VERSION ""

NS_ :

BS_:

BU_: RLPSU DPSU APSU PSB SHVU_RR vHS_B2 FCS EMCU SLB RCM CGW_CCU vDummy_HS_B ATS RLHV PFSU SGU ALBCU DSAU SWRC SHVU_FR RCS RRPSU BLTN_CAM SCM DLBCU OHCL RWPC RRHV WPC HOD ASAU

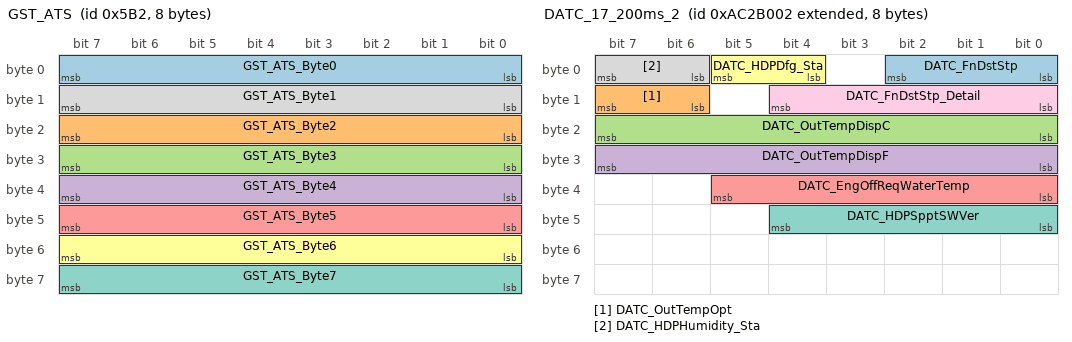
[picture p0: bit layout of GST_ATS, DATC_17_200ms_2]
BO_ 1458 GST_ATS: 8 CGW_CCU
 SG_ GST_ATS_Byte0 : 0|8@1+ (1,0) [0|0] ""  ATS
 SG_ GST_ATS_Byte2 : 16|8@1+ (1,0) [0|0] ""  ATS
 SG_ GST_ATS_Byte3 : 24|8@1+ (1,0) [0|0] ""  ATS
 SG_ GST_ATS_Byte4 : 32|8@1+ (1,0) [0|0] ""  ATS
 SG_ GST_ATS_Byte5 : 40|8@1+ (1,0) [0|0] ""  ATS
 SG_ GST_ATS_Byte6 : 48|8@1+ (1,0) [0|0] ""  ATS
 SG_ GST_ATS_Byte7 : 56|8@1+ (1,0) [0|0] ""  ATS
 SG_ GST_ATS_Byte1 : 8|8@1+ (1,0) [0|0] ""  ATS

BO_ 2328014850 DATC_17_200ms_2: 8 CGW_CCU
 SG_ DATC_FnDstStp : 0|3@1+ (1,0) [0|0] ""  ATS
 SG_ DATC_OutTempOpt : 14|2@1+ (1,0) [0|0] ""  Vector__XXX
 SG_ DATC_OutTempDispC : 16|8@1+ (0.5,-41) [0|0] "¡É"  ATS
 SG_ DATC_OutTempDispF : 24|8@1+ (1,-42) [0|0] "¢µ"  ATS
 SG_ DATC_EngOffReqWaterTemp : 32|6@1+ (1,38) [0|0] "¡É"  Vector__XXX
 SG_ DATC_HDPDfg_Sta : 4|2@1+ (1,0) [0|0] ""  Vector__XXX
 SG_ DATC_HDPSpptSWVer : 40|5@1+ (1,0) [0|0] ""  Vector__XXX
 SG_ DATC_HDPHumidity_Sta : 6|2@1+ (1,0) [0|0] ""  Vector__XXX
 SG_ DATC_FnDstStp_Detail : 8|5@1+ (1,0) [0|0] ""  ATS

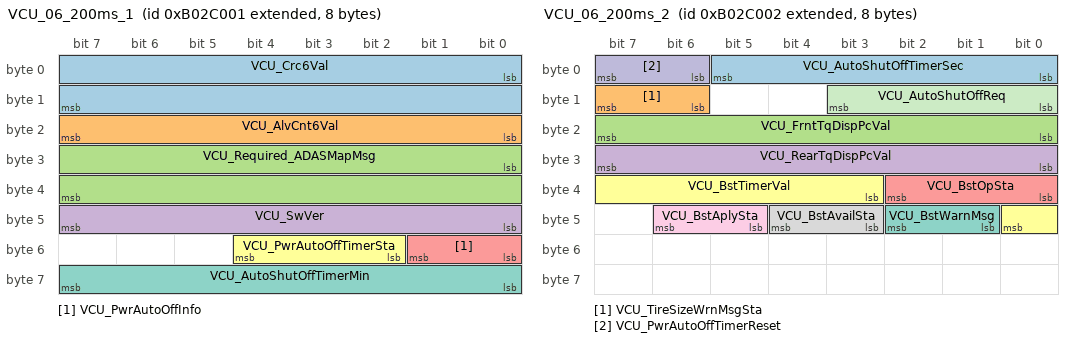
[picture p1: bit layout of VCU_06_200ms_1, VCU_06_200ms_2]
BO_ 2332213249 VCU_06_200ms_1: 8 CGW_CCU
 SG_ VCU_Crc6Val : 0|16@1+ (1,0) [0|0] ""  Vector__XXX
 SG_ VCU_AlvCnt6Val : 16|8@1+ (1,0) [0|0] ""  Vector__XXX
 SG_ VCU_Required_ADASMapMsg : 24|16@1+ (1,0) [0|0] ""  Vector__XXX
 SG_ VCU_SwVer : 40|8@1+ (1,0) [0|0] ""  Vector__XXX
 SG_ VCU_PwrAutoOffInfo : 48|2@1+ (1,0) [0|0] ""  Vector__XXX
 SG_ VCU_PwrAutoOffTimerSta : 50|3@1+ (1,0) [0|0] ""  Vector__XXX
 SG_ VCU_AutoShutOffTimerMin : 56|8@1+ (1,0) [0|0] ""  Vector__XXX

BO_ 2328014851 DATC_17_200ms_3: 8 CGW_CCU

BO_ 2332213250 VCU_06_200ms_2: 8 CGW_CCU
 SG_ VCU_AutoShutOffTimerSec : 0|6@1+ (1,0) [0|0] ""  Vector__XXX
 SG_ VCU_TireSizeWrnMsgSta : 14|2@1+ (1,0) [0|0] ""  Vector__XXX
 SG_ VCU_FrntTqDispPcVal : 16|8@1- (1,0) [0|0] ""  Vector__XXX
 SG_ VCU_RearTqDispPcVal : 24|8@1- (1,0) [0|0] ""  Vector__XXX
 SG_ VCU_BstOpSta : 32|3@1+ (1,0) [0|0] ""  PSB,DLBCU
 SG_ VCU_BstTimerVal : 35|6@1+ (1,0) [0|0] ""  PSB,DLBCU
 SG_ VCU_BstWarnMsg : 41|2@1+ (1,0) [0|0] ""  PSB,DLBCU
 SG_ VCU_BstAvailSta : 43|2@1+ (1,0) [0|0] ""  DLBCU
 SG_ VCU_BstAplySta : 45|2@1+ (1,0) [0|0] ""  DLBCU
 SG_ VCU_PwrAutoOffTimerReset : 6|2@1+ (1,0) [0|0] ""  Vector__XXX
 SG_ VCU_AutoShutOffReq : 8|4@1+ (1,0) [0|0] ""  Vector__XXX

BO_ 2332213251 VCU_06_200ms_3: 8 CGW_CCU

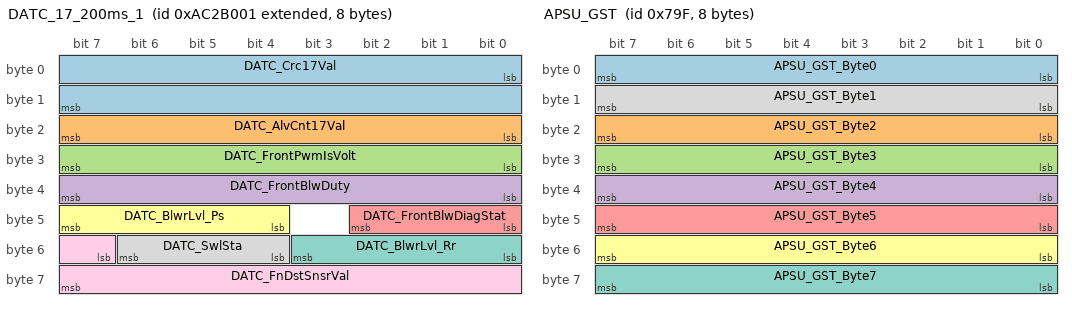
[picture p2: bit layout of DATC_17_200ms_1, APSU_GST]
BO_ 2328014849 DATC_17_200ms_1: 8 CGW_CCU
 SG_ DATC_Crc17Val : 0|16@1+ (1,0) [0|0] ""  Vector__XXX
 SG_ DATC_AlvCnt17Val : 16|8@1+ (1,0) [0|0] ""  Vector__XXX
 SG_ DATC_FrontPwmIsVolt : 24|8@1+ (0.02,0) [0|0] "V"  Vector__XXX
 SG_ DATC_FrontBlwDuty : 32|8@1+ (1,0) [0|0] ""  Vector__XXX
 SG_ DATC_FrontBlwDiagStat : 40|3@1+ (1,0) [0|0] ""  Vector__XXX
 SG_ DATC_BlwrLvl_Ps : 44|4@1+ (1,0) [0|0] ""  Vector__XXX
 SG_ DATC_BlwrLvl_Rr : 48|4@1+ (1,0) [0|0] ""  Vector__XXX
 SG_ DATC_SwlSta : 52|3@1+ (1,0) [0|0] ""  Vector__XXX
 SG_ DATC_FnDstSnsrVal : 55|9@1+ (1,0) [0|0] ""  Vector__XXX

BO_ 1951 APSU_GST: 8 APSU
 SG_ APSU_GST_Byte0 : 0|8@1+ (1,0) [0|0] ""  CGW_CCU
 SG_ APSU_GST_Byte2 : 16|8@1+ (1,0) [0|0] ""  CGW_CCU
 SG_ APSU_GST_Byte3 : 24|8@1+ (1,0) [0|0] ""  CGW_CCU
 SG_ APSU_GST_Byte4 : 32|8@1+ (1,0) [0|0] ""  CGW_CCU
 SG_ APSU_GST_Byte5 : 40|8@1+ (1,0) [0|0] ""  CGW_CCU
 SG_ APSU_GST_Byte6 : 48|8@1+ (1,0) [0|0] ""  CGW_CCU
 SG_ APSU_GST_Byte7 : 56|8@1+ (1,0) [0|0] ""  CGW_CCU
 SG_ APSU_GST_Byte1 : 8|8@1+ (1,0) [0|0] ""  CGW_CCU

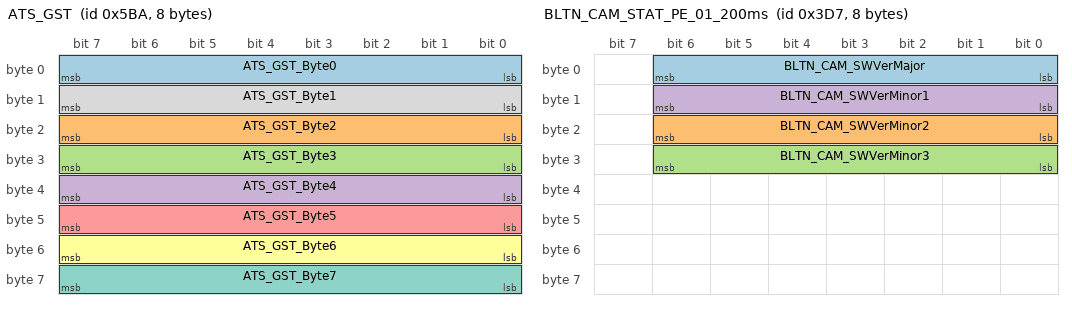
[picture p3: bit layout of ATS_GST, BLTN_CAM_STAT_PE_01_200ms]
BO_ 1466 ATS_GST: 8 ATS
 SG_ ATS_GST_Byte0 : 0|8@1+ (1,0) [0|0] ""  CGW_CCU
 SG_ ATS_GST_Byte2 : 16|8@1+ (1,0) [0|0] ""  CGW_CCU
 SG_ ATS_GST_Byte3 : 24|8@1+ (1,0) [0|0] ""  CGW_CCU
 SG_ ATS_GST_Byte4 : 32|8@1+ (1,0) [0|0] ""  CGW_CCU
 SG_ ATS_GST_Byte5 : 40|8@1+ (1,0) [0|0] ""  CGW_CCU
 SG_ ATS_GST_Byte6 : 48|8@1+ (1,0) [0|0] ""  CGW_CCU
 SG_ ATS_GST_Byte7 : 56|8@1+ (1,0) [0|0] ""  CGW_CCU
 SG_ ATS_GST_Byte1 : 8|8@1+ (1,0) [0|0] ""  CGW_CCU

BO_ 983 BLTN_CAM_STAT_PE_01_200ms: 8 BLTN_CAM
 SG_ BLTN_CAM_SWVerMajor : 0|7@1+ (1,0) [0|0] ""  CGW_CCU
 SG_ BLTN_CAM_SWVerMinor2 : 16|7@1+ (1,0) [0|0] ""  CGW_CCU
 SG_ BLTN_CAM_SWVerMinor3 : 24|7@1+ (1,0) [0|0] ""  CGW_CCU
 SG_ BLTN_CAM_SWVerMinor1 : 8|7@1+ (1,0) [0|0] ""  CGW_CCU

BO_ 981 APSS_01_200ms: 8 APSU
 SG_ APSS_StExtFwdMvBtn : 0|2@1+ (1,0) [0|0] ""  Vector__XXX
 SG_ APSS_StSldFwdMvBtn : 16|2@1+ (1,0) [0|0] ""  CGW_CCU
 SG_ APSS_StSldBwdMvBtn : 18|2@1+ (1,0) [0|0] ""  CGW_CCU
 SG_ APSS_StExtBwdMvBtn : 2|2@1+ (1,0) [0|0] ""  Vector__XXX
 SG_ APSS_StRclFwdMvBtn : 20|2@1+ (1,0) [0|0] ""  CGW_CCU
 SG_ APSS_StRclBwdMvBtn : 22|2@1+ (1,0) [0|0] ""  CGW_CCU
 SG_ APSS_StHgtUpMvBtn : 24|2@1+ (1,0) [0|0] ""  CGW_CCU
 SG_ APSS_StHgtDnMvBtn : 26|2@1+ (1,0) [0|0] ""  CGW_CCU
 SG_ APSS_StTltUpMvBtn : 28|2@1+ (1,0) [0|0] ""  CGW_CCU
 SG_ APSS_StTltDnMvBtn : 30|2@1+ (1,0) [0|0] ""  CGW_CCU
 SG_ APSS_StHRestUpMvBtn : 32|2@1+ (1,0) [0|0] ""  CGW_CCU
 SG_ APSS_StHRestDnMvBtn : 34|2@1+ (1,0) [0|0] ""  CGW_CCU
 SG_ APSS_StHRestFwdMvBtn : 36|2@1+ (1,0) [0|0] ""  CGW_CCU
 SG_ APSS_StHRestBwdMvBtn : 38|2@1+ (1,0) [0|0] ""  CGW_CCU
 SG_ APSS_StLegUpMvBtn : 40|2@1+ (1,0) [0|0] ""  Vector__XXX
 SG_ APSS_StLegDnMvBtn : 42|2@1+ (1,0) [0|0] ""  Vector__XXX
 SG_ APSS_StRlxModeBtn : 44|2@1+ (1,0) [0|0] ""  Vector__XXX
 SG_ APSS_StRlxReturnBtn : 46|2@1+ (1,0) [0|0] ""  Vector__XXX
 SG_ APSS_StRlxTltUpMvBtn : 48|2@1+ (1,0) [0|0] ""  Vector__XXX
 SG_ APSS_StRlxTltDnMvBtn : 50|2@1+ (1,0) [0|0] ""  Vector__XXX

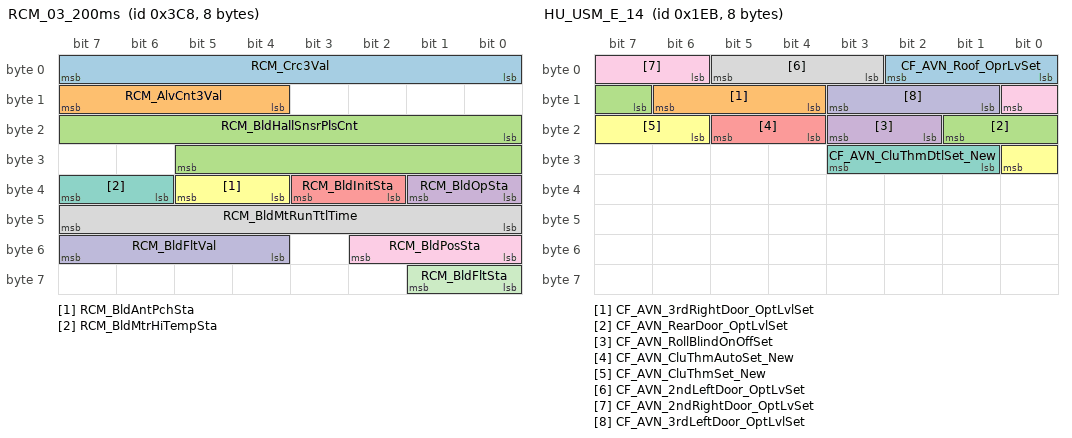
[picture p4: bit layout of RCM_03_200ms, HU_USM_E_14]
BO_ 968 RCM_03_200ms: 8 RCM
 SG_ RCM_Crc3Val : 0|8@1+ (1,0) [0|0] ""  Vector__XXX
 SG_ RCM_AlvCnt3Val : 12|4@1+ (1,0) [0|0] ""  Vector__XXX
 SG_ RCM_BldHallSnsrPlsCnt : 16|14@1+ (1,0) [0|0] "pulse count"  Vector__XXX
 SG_ RCM_BldOpSta : 32|2@1+ (1,0) [0|0] ""  Vector__XXX
 SG_ RCM_BldInitSta : 34|2@1+ (1,0) [0|0] ""  Vector__XXX
 SG_ RCM_BldAntPchSta : 36|2@1+ (1,0) [0|0] ""  Vector__XXX
 SG_ RCM_BldMtrHiTempSta : 38|2@1+ (1,0) [0|0] ""  Vector__XXX
 SG_ RCM_BldMtRunTtlTime : 40|8@1+ (1,0) [0|0] "Sec"  Vector__XXX
 SG_ RCM_BldPosSta : 48|3@1+ (1,0) [0|0] ""  SGU
 SG_ RCM_BldFltVal : 52|4@1+ (1,0) [0|0] ""  Vector__XXX
 SG_ RCM_BldFltSta : 56|2@1+ (1,0) [0|0] ""  Vector__XXX

BO_ 491 HU_USM_E_14: 8 CGW_CCU
 SG_ CF_AVN_Roof_OprLvSet : 0|3@1+ (1,0) [0|0] ""  SGU
 SG_ CF_AVN_3rdRightDoor_OptLvlSet : 12|3@1+ (1,0) [0|0] ""  SGU
 SG_ CF_AVN_RearDoor_OptLvlSet : 15|3@1+ (1,0) [0|0] ""  SGU
 SG_ CF_AVN_RollBlindOnOffSet : 18|2@1+ (1,0) [0|0] ""  SGU
 SG_ CF_AVN_CluThmAutoSet_New : 20|2@1+ (1,0) [0|0] ""  Vector__XXX
 SG_ CF_AVN_CluThmSet_New : 22|3@1+ (1,0) [0|0] ""  Vector__XXX
 SG_ CF_AVN_CluThmDtlSet_New : 25|3@1+ (1,0) [0|0] ""  Vector__XXX
 SG_ CF_AVN_2ndLeftDoor_OptLvSet : 3|3@1+ (1,0) [0|0] ""  SGU
 SG_ CF_AVN_2ndRightDoor_OptLvSet : 6|3@1+ (1,0) [0|0] ""  SGU
 SG_ CF_AVN_3rdLeftDoor_OptLvlSet : 9|3@1+ (1,0) [0|0] ""  SGU

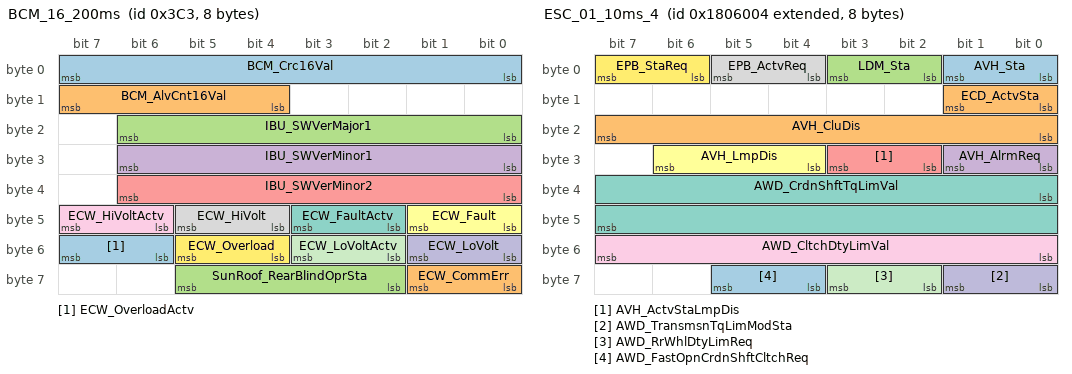
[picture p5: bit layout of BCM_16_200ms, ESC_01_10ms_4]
BO_ 963 BCM_16_200ms: 8 CGW_CCU
 SG_ BCM_Crc16Val : 0|8@1+ (1,0) [0|0] ""  Vector__XXX
 SG_ BCM_AlvCnt16Val : 12|4@1+ (1,0) [0|0] ""  Vector__XXX
 SG_ IBU_SWVerMajor1 : 16|7@1+ (1,0) [0|0] ""  Vector__XXX
 SG_ IBU_SWVerMinor1 : 24|7@1+ (1,0) [0|0] ""  Vector__XXX
 SG_ IBU_SWVerMinor2 : 32|7@1+ (1,0) [0|0] ""  Vector__XXX
 SG_ ECW_Fault : 40|2@1+ (1,0) [0|0] ""  Vector__XXX
 SG_ ECW_FaultActv : 42|2@1+ (1,0) [0|0] ""  Vector__XXX
 SG_ ECW_HiVolt : 44|2@1+ (1,0) [0|0] ""  Vector__XXX
 SG_ ECW_HiVoltActv : 46|2@1+ (1,0) [0|0] ""  Vector__XXX
 SG_ ECW_LoVolt : 48|2@1+ (1,0) [0|0] ""  Vector__XXX
 SG_ ECW_LoVoltActv : 50|2@1+ (1,0) [0|0] ""  Vector__XXX
 SG_ ECW_Overload : 52|2@1+ (1,0) [0|0] ""  Vector__XXX
 SG_ ECW_OverloadActv : 54|2@1+ (1,0) [0|0] ""  Vector__XXX
 SG_ ECW_CommErr : 56|2@1+ (1,0) [0|0] ""  Vector__XXX
 SG_ SunRoof_RearBlindOprSta : 58|4@1+ (1,0) [0|0] ""  ATS

BO_ 2172674052 ESC_01_10ms_4: 8 CGW_CCU
 SG_ AVH_Sta : 0|2@1+ (1,0) [0|0] ""  Vector__XXX
 SG_ AVH_CluDis : 16|8@1+ (1,0) [0|0] ""  Vector__XXX
 SG_ LDM_Sta : 2|2@1+ (1,0) [0|0] ""  Vector__XXX
 SG_ AVH_AlrmReq : 24|2@1+ (1,0) [0|0] ""  Vector__XXX
 SG_ AVH_ActvStaLmpDis : 26|2@1+ (1,0) [0|0] ""  Vector__XXX
 SG_ AVH_LmpDis : 28|3@1+ (1,0) [0|0] ""  Vector__XXX
 SG_ AWD_CrdnShftTqLimVal : 32|16@1+ (1,0) [0|0] "Nm"  Vector__XXX
 SG_ EPB_ActvReq : 4|2@1+ (1,0) [0|0] ""  Vector__XXX
 SG_ AWD_CltchDtyLimVal : 48|8@1+ (0.390625,0) [0|0] "%"  Vector__XXX
 SG_ AWD_TransmsnTqLimModSta : 56|2@1+ (1,0) [0|0] ""  Vector__XXX
 SG_ AWD_RrWhlDtyLimReq : 58|2@1+ (1,0) [0|0] ""  Vector__XXX
 SG_ EPB_StaReq : 6|2@1+ (1,0) [0|0] ""  Vector__XXX
 SG_ AWD_FastOpnCrdnShftCltchReq : 60|2@1+ (1,0) [0|0] ""  Vector__XXX
 SG_ ECD_ActvSta : 8|2@1+ (1,0) [0|0] ""  Vector__XXX

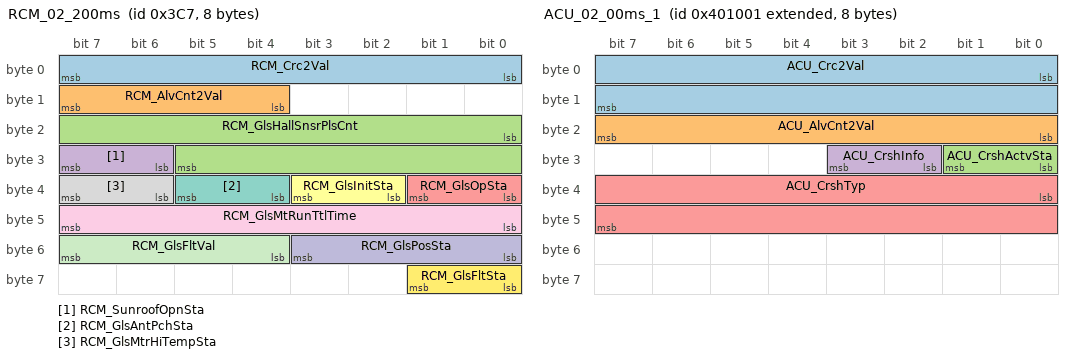
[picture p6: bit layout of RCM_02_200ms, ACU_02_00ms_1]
BO_ 967 RCM_02_200ms: 8 RCM
 SG_ RCM_Crc2Val : 0|8@1+ (1,0) [0|0] ""  Vector__XXX
 SG_ RCM_AlvCnt2Val : 12|4@1+ (1,0) [0|0] ""  Vector__XXX
 SG_ RCM_GlsHallSnsrPlsCnt : 16|14@1+ (1,0) [0|0] "pulse count"  Vector__XXX
 SG_ RCM_SunroofOpnSta : 30|2@1+ (1,0) [0|0] ""  CGW_CCU
 SG_ RCM_GlsOpSta : 32|2@1+ (1,0) [0|0] ""  CGW_CCU
 SG_ RCM_GlsInitSta : 34|2@1+ (1,0) [0|0] ""  Vector__XXX
 SG_ RCM_GlsAntPchSta : 36|2@1+ (1,0) [0|0] ""  Vector__XXX
 SG_ RCM_GlsMtrHiTempSta : 38|2@1+ (1,0) [0|0] ""  Vector__XXX
 SG_ RCM_GlsMtRunTtlTime : 40|8@1+ (1,0) [0|0] "Sec"  Vector__XXX
 SG_ RCM_GlsPosSta : 48|4@1+ (1,0) [0|0] ""  Vector__XXX
 SG_ RCM_GlsFltVal : 52|4@1+ (1,0) [0|0] ""  Vector__XXX
 SG_ RCM_GlsFltSta : 56|2@1+ (1,0) [0|0] ""  CGW_CCU

BO_ 2151682049 ACU_02_00ms_1: 8 CGW_CCU
 SG_ ACU_Crc2Val : 0|16@1+ (1,0) [0|0] ""  Vector__XXX
 SG_ ACU_AlvCnt2Val : 16|8@1+ (1,0) [0|0] ""  Vector__XXX
 SG_ ACU_CrshActvSta : 24|2@1+ (1,0) [0|0] ""  APSU,RRPSU,RLPSU
 SG_ ACU_CrshInfo : 26|2@1+ (1,0) [0|0] ""  Vector__XXX
 SG_ ACU_CrshTyp : 32|16@1+ (1,0) [0|0] ""  Vector__XXX

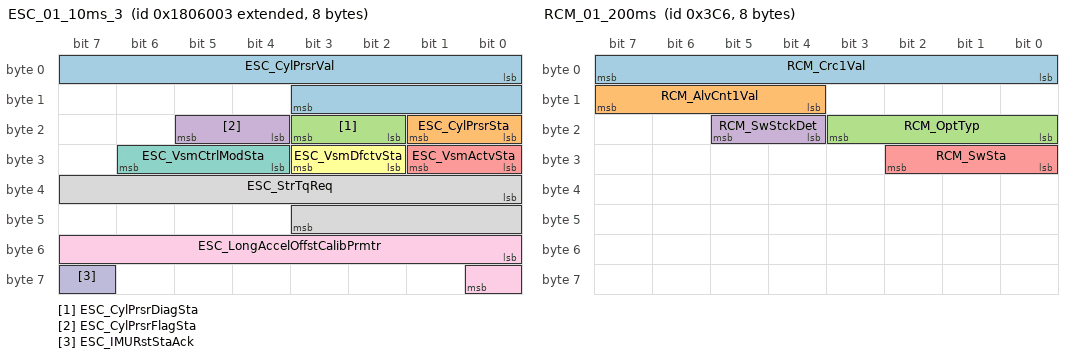
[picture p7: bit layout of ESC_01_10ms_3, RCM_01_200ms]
BO_ 2172674051 ESC_01_10ms_3: 8 CGW_CCU
 SG_ ESC_CylPrsrVal : 0|12@1+ (0.1,0) [0|0] "Bar"  PSB
 SG_ ESC_CylPrsrSta : 16|2@1+ (1,0) [0|0] ""  PSB
 SG_ ESC_CylPrsrDiagSta : 18|2@1+ (1,0) [0|0] ""  PSB
 SG_ ESC_CylPrsrFlagSta : 20|2@1+ (1,0) [0|0] ""  Vector__XXX
 SG_ ESC_VsmActvSta : 24|2@1+ (1,0) [0|0] ""  Vector__XXX
 SG_ ESC_VsmDfctvSta : 26|2@1+ (1,0) [0|0] ""  Vector__XXX
 SG_ ESC_VsmCtrlModSta : 28|3@1+ (1,0) [0|0] ""  Vector__XXX
 SG_ ESC_StrTqReq : 32|12@1+ (0.01,-20.48) [0|0] "Nm"  Vector__XXX
 SG_ ESC_LongAccelOffstCalibPrmtr : 48|9@1+ (0.001,-0.255) [0|0] "g"  Vector__XXX
 SG_ ESC_IMURstStaAck : 63|1@1+ (1,0) [0|0] ""  Vector__XXX

BO_ 966 RCM_01_200ms: 8 RCM
 SG_ RCM_Crc1Val : 0|8@1+ (1,0) [0|0] ""  Vector__XXX
 SG_ RCM_AlvCnt1Val : 12|4@1+ (1,0) [0|0] ""  Vector__XXX
 SG_ RCM_OptTyp : 16|4@1+ (1,0) [0|0] ""  CGW_CCU
 SG_ RCM_SwStckDet : 20|2@1+ (1,0) [0|0] ""  Vector__XXX
 SG_ RCM_SwSta : 24|3@1+ (1,0) [0|0] ""  Vector__XXX

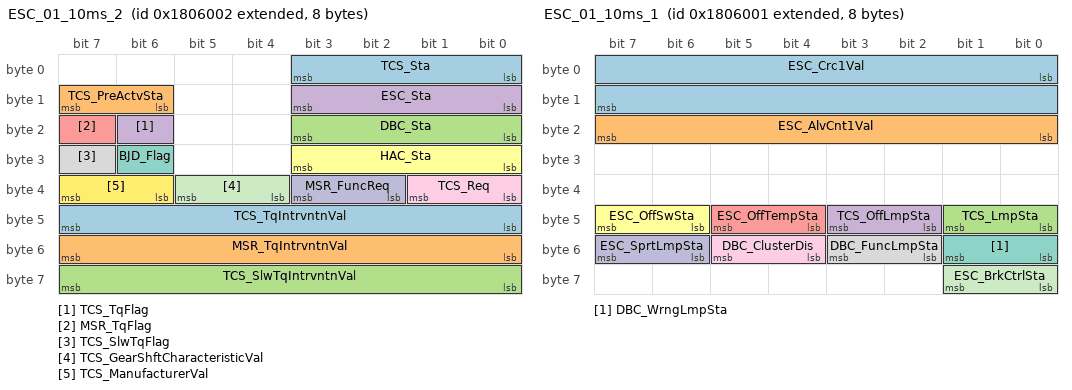
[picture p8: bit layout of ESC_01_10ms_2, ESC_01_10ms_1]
BO_ 2172674050 ESC_01_10ms_2: 8 CGW_CCU
 SG_ TCS_Sta : 0|4@1+ (1,0) [0|0] ""  Vector__XXX
 SG_ TCS_PreActvSta : 14|2@1+ (1,0) [0|0] ""  Vector__XXX
 SG_ DBC_Sta : 16|4@1+ (1,0) [0|0] ""  Vector__XXX
 SG_ TCS_TqFlag : 22|1@1+ (1,0) [0|0] ""  Vector__XXX
 SG_ MSR_TqFlag : 23|1@1+ (1,0) [0|0] ""  Vector__XXX
 SG_ HAC_Sta : 24|4@1+ (1,0) [0|0] ""  Vector__XXX
 SG_ BJD_Flag : 30|1@1+ (1,0) [0|0] ""  Vector__XXX
 SG_ TCS_SlwTqFlag : 31|1@1+ (1,0) [0|0] ""  Vector__XXX
 SG_ TCS_Req : 32|2@1+ (1,0) [0|0] ""  Vector__XXX
 SG_ MSR_FuncReq : 34|2@1+ (1,0) [0|0] ""  Vector__XXX
 SG_ TCS_GearShftCharacteristicVal : 36|2@1+ (1,0) [0|0] ""  Vector__XXX
 SG_ TCS_ManufacturerVal : 38|2@1+ (1,0) [0|0] ""  Vector__XXX
 SG_ TCS_TqIntrvntnVal : 40|8@1+ (0.390625,0) [0|0] "%"  Vector__XXX
 SG_ MSR_TqIntrvntnVal : 48|8@1+ (0.390625,0) [0|0] "%"  Vector__XXX
 SG_ TCS_SlwTqIntrvntnVal : 56|8@1+ (0.390625,0) [0|0] "%"  Vector__XXX
 SG_ ESC_Sta : 8|4@1+ (1,0) [0|0] ""  Vector__XXX

BO_ 2172674049 ESC_01_10ms_1: 8 CGW_CCU
 SG_ ESC_Crc1Val : 0|16@1+ (1,0) [0|0] ""  Vector__XXX
 SG_ ESC_AlvCnt1Val : 16|8@1+ (1,0) [0|0] ""  Vector__XXX
 SG_ TCS_LmpSta : 40|2@1+ (1,0) [0|0] ""  Vector__XXX
 SG_ TCS_OffLmpSta : 42|2@1+ (1,0) [0|0] ""  Vector__XXX
 SG_ ESC_OffTempSta : 44|2@1+ (1,0) [0|0] ""  Vector__XXX
 SG_ ESC_OffSwSta : 46|2@1+ (1,0) [0|0] ""  Vector__XXX
 SG_ DBC_WrngLmpSta : 48|2@1+ (1,0) [0|0] ""  Vector__XXX
 SG_ DBC_FuncLmpSta : 50|2@1+ (1,0) [0|0] ""  Vector__XXX
 SG_ DBC_ClusterDis : 52|2@1+ (1,0) [0|0] ""  Vector__XXX
 SG_ ESC_SprtLmpSta : 54|2@1+ (1,0) [0|0] ""  Vector__XXX
 SG_ ESC_BrkCtrlSta : 56|2@1+ (1,0) [0|0] ""  Vector__XXX

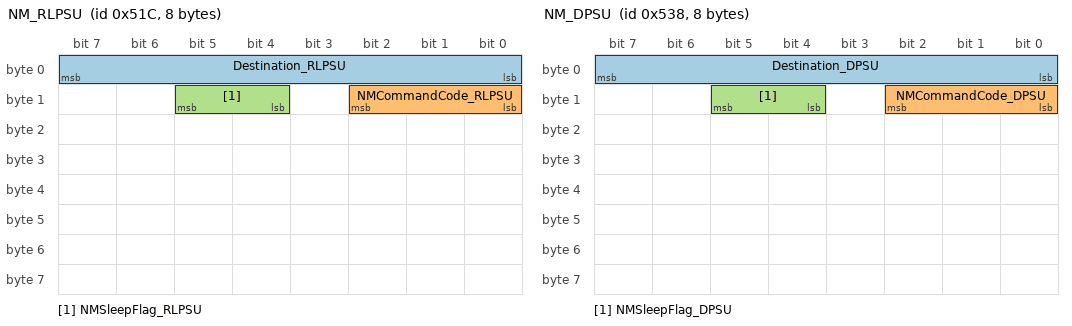
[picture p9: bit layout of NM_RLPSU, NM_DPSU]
BO_ 1308 NM_RLPSU: 8 RLPSU
 SG_ Destination_RLPSU : 0|8@1+ (1,0) [0|0] ""  DPSU,APSU,PSB,SHVU_RR,vHS_B2,FCS,EMCU,SLB,RCM,CGW_CCU,vDummy_HS_B,ATS,RLHV,PFSU,SGU,ALBCU,DSAU,SWRC,SHVU_FR,RCS,RRPSU,BLTN_CAM,SCM,DLBCU,OHCL,RWPC,RRHV,WPC,HOD,ASAU
 SG_ NMCommandCode_RLPSU : 8|3@1+ (1,0) [0|0] ""  DPSU,APSU,PSB,SHVU_RR,vHS_B2,FCS,EMCU,SLB,RCM,CGW_CCU,vDummy_HS_B,ATS,RLHV,PFSU,SGU,ALBCU,DSAU,SWRC,SHVU_FR,RCS,RRPSU,BLTN_CAM,SCM,DLBCU,OHCL,RWPC,RRHV,WPC,HOD,ASAU
 SG_ NMSleepFlag_RLPSU : 12|2@1+ (1,0) [0|0] ""  DPSU,APSU,PSB,SHVU_RR,vHS_B2,FCS,EMCU,SLB,RCM,CGW_CCU,vDummy_HS_B,ATS,RLHV,PFSU,SGU,ALBCU,DSAU,SWRC,SHVU_FR,RCS,RRPSU,BLTN_CAM,SCM,DLBCU,OHCL,RWPC,RRHV,WPC,HOD,ASAU

BO_ 1336 NM_DPSU: 8 DPSU
 SG_ Destination_DPSU : 0|8@1+ (1,0) [0|0] ""  RLPSU,APSU,PSB,SHVU_RR,vHS_B2,FCS,EMCU,SLB,RCM,CGW_CCU,vDummy_HS_B,ATS,RLHV,PFSU,SGU,ALBCU,DSAU,SWRC,SHVU_FR,RCS,RRPSU,BLTN_CAM,SCM,DLBCU,OHCL,RWPC,RRHV,WPC,HOD,ASAU
 SG_ NMCommandCode_DPSU : 8|3@1+ (1,0) [0|0] ""  RLPSU,APSU,PSB,SHVU_RR,vHS_B2,FCS,EMCU,SLB,RCM,CGW_CCU,vDummy_HS_B,ATS,RLHV,PFSU,SGU,ALBCU,DSAU,SWRC,SHVU_FR,RCS,RRPSU,BLTN_CAM,SCM,DLBCU,OHCL,RWPC,RRHV,WPC,HOD,ASAU
 SG_ NMSleepFlag_DPSU : 12|2@1+ (1,0) [0|0] ""  RLPSU,APSU,PSB,SHVU_RR,vHS_B2,FCS,EMCU,SLB,RCM,CGW_CCU,vDummy_HS_B,ATS,RLHV,PFSU,SGU,ALBCU,DSAU,SWRC,SHVU_FR,RCS,RRPSU,BLTN_CAM,SCM,DLBCU,OHCL,RWPC,RRHV,WPC,HOD,ASAU

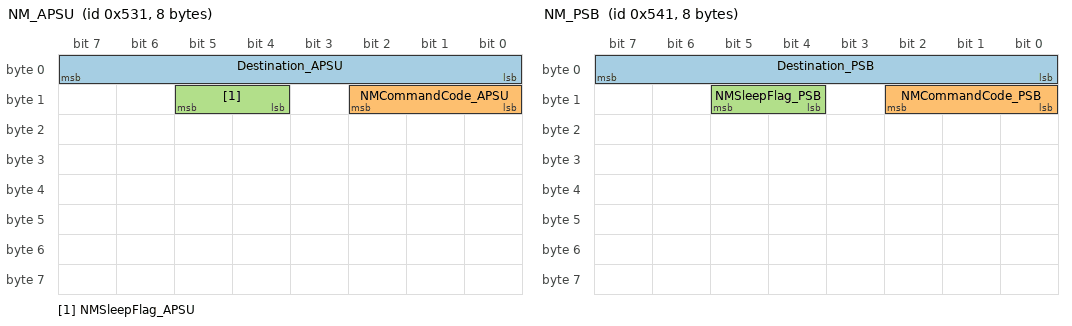
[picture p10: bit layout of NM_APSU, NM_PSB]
BO_ 1329 NM_APSU: 8 APSU
 SG_ Destination_APSU : 0|8@1+ (1,0) [0|0] ""  RLPSU,DPSU,PSB,SHVU_RR,vHS_B2,FCS,EMCU,SLB,RCM,CGW_CCU,vDummy_HS_B,ATS,RLHV,PFSU,SGU,ALBCU,DSAU,SWRC,SHVU_FR,RCS,RRPSU,BLTN_CAM,SCM,DLBCU,OHCL,RWPC,RRHV,WPC,HOD,ASAU
 SG_ NMCommandCode_APSU : 8|3@1+ (1,0) [0|0] ""  RLPSU,DPSU,PSB,SHVU_RR,vHS_B2,FCS,EMCU,SLB,RCM,CGW_CCU,vDummy_HS_B,ATS,RLHV,PFSU,SGU,ALBCU,DSAU,SWRC,SHVU_FR,RCS,RRPSU,BLTN_CAM,SCM,DLBCU,OHCL,RWPC,RRHV,WPC,HOD,ASAU
 SG_ NMSleepFlag_APSU : 12|2@1+ (1,0) [0|0] ""  RLPSU,DPSU,PSB,SHVU_RR,vHS_B2,FCS,EMCU,SLB,RCM,CGW_CCU,vDummy_HS_B,ATS,RLHV,PFSU,SGU,ALBCU,DSAU,SWRC,SHVU_FR,RCS,RRPSU,BLTN_CAM,SCM,DLBCU,OHCL,RWPC,RRHV,WPC,HOD,ASAU

BO_ 1345 NM_PSB: 8 PSB
 SG_ Destination_PSB : 0|8@1+ (1,0) [0|0] ""  RLPSU,DPSU,APSU,SHVU_RR,vHS_B2,FCS,EMCU,SLB,RCM,CGW_CCU,vDummy_HS_B,ATS,RLHV,PFSU,SGU,ALBCU,DSAU,SWRC,SHVU_FR,RCS,RRPSU,BLTN_CAM,SCM,DLBCU,OHCL,RWPC,RRHV,WPC,HOD,ASAU
 SG_ NMCommandCode_PSB : 8|3@1+ (1,0) [0|0] ""  RLPSU,DPSU,APSU,SHVU_RR,vHS_B2,FCS,EMCU,SLB,RCM,CGW_CCU,vDummy_HS_B,ATS,RLHV,PFSU,SGU,ALBCU,DSAU,SWRC,SHVU_FR,RCS,RRPSU,BLTN_CAM,SCM,DLBCU,OHCL,RWPC,RRHV,WPC,HOD,ASAU
 SG_ NMSleepFlag_PSB : 12|2@1+ (1,0) [0|0] ""  RLPSU,DPSU,APSU,SHVU_RR,vHS_B2,FCS,EMCU,SLB,RCM,CGW_CCU,vDummy_HS_B,ATS,RLHV,PFSU,SGU,ALBCU,DSAU,SWRC,SHVU_FR,RCS,RRPSU,BLTN_CAM,SCM,DLBCU,OHCL,RWPC,RRHV,WPC,HOD,ASAU

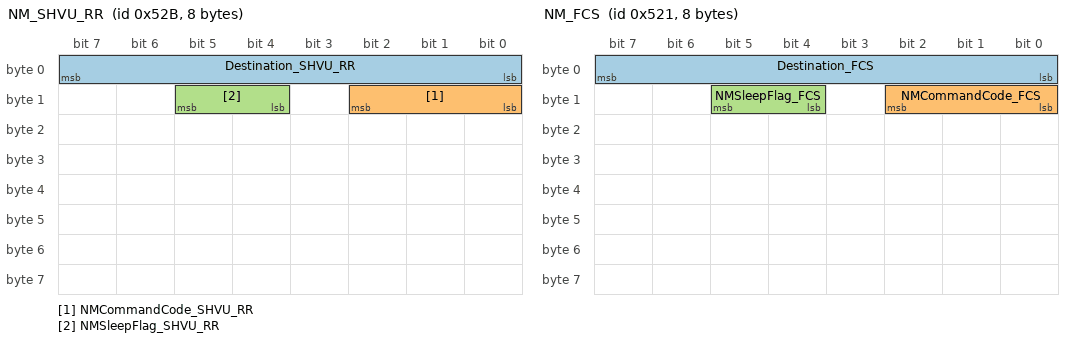
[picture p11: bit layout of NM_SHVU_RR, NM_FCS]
BO_ 1323 NM_SHVU_RR: 8 SHVU_RR
 SG_ Destination_SHVU_RR : 0|8@1+ (1,0) [0|0] ""  RLPSU,DPSU,APSU,PSB,vHS_B2,FCS,EMCU,SLB,RCM,CGW_CCU,vDummy_HS_B,ATS,RLHV,PFSU,SGU,ALBCU,DSAU,SWRC,SHVU_FR,RCS,RRPSU,BLTN_CAM,SCM,DLBCU,OHCL,RWPC,RRHV,WPC,HOD,ASAU
 SG_ NMCommandCode_SHVU_RR : 8|3@1+ (1,0) [0|0] ""  RLPSU,DPSU,APSU,PSB,vHS_B2,FCS,EMCU,SLB,RCM,CGW_CCU,vDummy_HS_B,ATS,RLHV,PFSU,SGU,ALBCU,DSAU,SWRC,SHVU_FR,RCS,RRPSU,BLTN_CAM,SCM,DLBCU,OHCL,RWPC,RRHV,WPC,HOD,ASAU
 SG_ NMSleepFlag_SHVU_RR : 12|2@1+ (1,0) [0|0] ""  RLPSU,DPSU,APSU,PSB,vHS_B2,FCS,EMCU,SLB,RCM,CGW_CCU,vDummy_HS_B,ATS,RLHV,PFSU,SGU,ALBCU,DSAU,SWRC,SHVU_FR,RCS,RRPSU,BLTN_CAM,SCM,DLBCU,OHCL,RWPC,RRHV,WPC,HOD,ASAU

BO_ 1313 NM_FCS: 8 FCS
 SG_ Destination_FCS : 0|8@1+ (1,0) [0|0] ""  RLPSU,DPSU,APSU,PSB,SHVU_RR,vHS_B2,EMCU,SLB,RCM,CGW_CCU,vDummy_HS_B,ATS,RLHV,PFSU,SGU,ALBCU,DSAU,SWRC,SHVU_FR,RCS,RRPSU,BLTN_CAM,SCM,DLBCU,OHCL,RWPC,RRHV,WPC,HOD,ASAU
 SG_ NMCommandCode_FCS : 8|3@1+ (1,0) [0|0] ""  RLPSU,DPSU,APSU,PSB,SHVU_RR,vHS_B2,EMCU,SLB,RCM,CGW_CCU,vDummy_HS_B,ATS,RLHV,PFSU,SGU,ALBCU,DSAU,SWRC,SHVU_FR,RCS,RRPSU,BLTN_CAM,SCM,DLBCU,OHCL,RWPC,RRHV,WPC,HOD,ASAU
 SG_ NMSleepFlag_FCS : 12|2@1+ (1,0) [0|0] ""  RLPSU,DPSU,APSU,PSB,SHVU_RR,vHS_B2,EMCU,SLB,RCM,CGW_CCU,vDummy_HS_B,ATS,RLHV,PFSU,SGU,ALBCU,DSAU,SWRC,SHVU_FR,RCS,RRPSU,BLTN_CAM,SCM,DLBCU,OHCL,RWPC,RRHV,WPC,HOD,ASAU

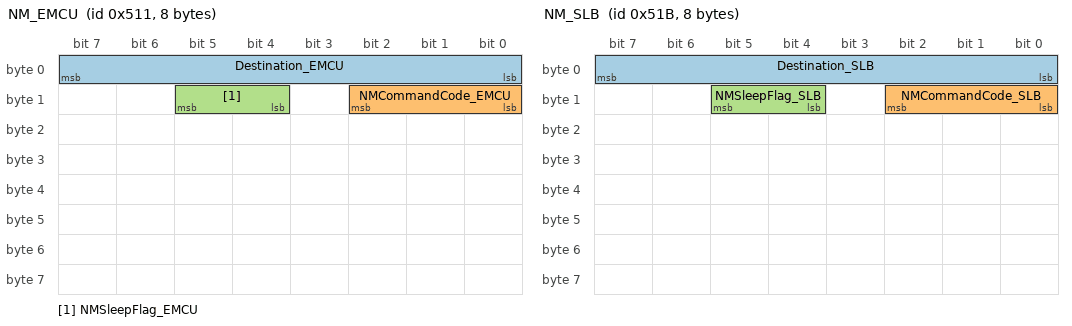
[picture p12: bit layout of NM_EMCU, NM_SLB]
BO_ 1297 NM_EMCU: 8 EMCU
 SG_ Destination_EMCU : 0|8@1+ (1,0) [0|0] ""  RLPSU,DPSU,APSU,PSB,SHVU_RR,vHS_B2,FCS,SLB,RCM,CGW_CCU,vDummy_HS_B,ATS,RLHV,PFSU,SGU,ALBCU,DSAU,SWRC,SHVU_FR,RCS,RRPSU,BLTN_CAM,SCM,DLBCU,OHCL,RWPC,RRHV,WPC,HOD,ASAU
 SG_ NMCommandCode_EMCU : 8|3@1+ (1,0) [0|0] ""  RLPSU,DPSU,APSU,PSB,SHVU_RR,vHS_B2,FCS,SLB,RCM,CGW_CCU,vDummy_HS_B,ATS,RLHV,PFSU,SGU,ALBCU,DSAU,SWRC,SHVU_FR,RCS,RRPSU,BLTN_CAM,SCM,DLBCU,OHCL,RWPC,RRHV,WPC,HOD,ASAU
 SG_ NMSleepFlag_EMCU : 12|2@1+ (1,0) [0|0] ""  RLPSU,DPSU,APSU,PSB,SHVU_RR,vHS_B2,FCS,SLB,RCM,CGW_CCU,vDummy_HS_B,ATS,RLHV,PFSU,SGU,ALBCU,DSAU,SWRC,SHVU_FR,RCS,RRPSU,BLTN_CAM,SCM,DLBCU,OHCL,RWPC,RRHV,WPC,HOD,ASAU

BO_ 1307 NM_SLB: 8 SLB
 SG_ Destination_SLB : 0|8@1+ (1,0) [0|0] ""  RLPSU,DPSU,APSU,PSB,SHVU_RR,vHS_B2,FCS,EMCU,RCM,CGW_CCU,vDummy_HS_B,ATS,RLHV,PFSU,SGU,ALBCU,DSAU,SWRC,SHVU_FR,RCS,RRPSU,BLTN_CAM,SCM,DLBCU,OHCL,RWPC,RRHV,WPC,HOD,ASAU
 SG_ NMCommandCode_SLB : 8|3@1+ (1,0) [0|0] ""  RLPSU,DPSU,APSU,PSB,SHVU_RR,vHS_B2,FCS,EMCU,RCM,CGW_CCU,vDummy_HS_B,ATS,RLHV,PFSU,SGU,ALBCU,DSAU,SWRC,SHVU_FR,RCS,RRPSU,BLTN_CAM,SCM,DLBCU,OHCL,RWPC,RRHV,WPC,HOD,ASAU
 SG_ NMSleepFlag_SLB : 12|2@1+ (1,0) [0|0] ""  RLPSU,DPSU,APSU,PSB,SHVU_RR,vHS_B2,FCS,EMCU,RCM,CGW_CCU,vDummy_HS_B,ATS,RLHV,PFSU,SGU,ALBCU,DSAU,SWRC,SHVU_FR,RCS,RRPSU,BLTN_CAM,SCM,DLBCU,OHCL,RWPC,RRHV,WPC,HOD,ASAU

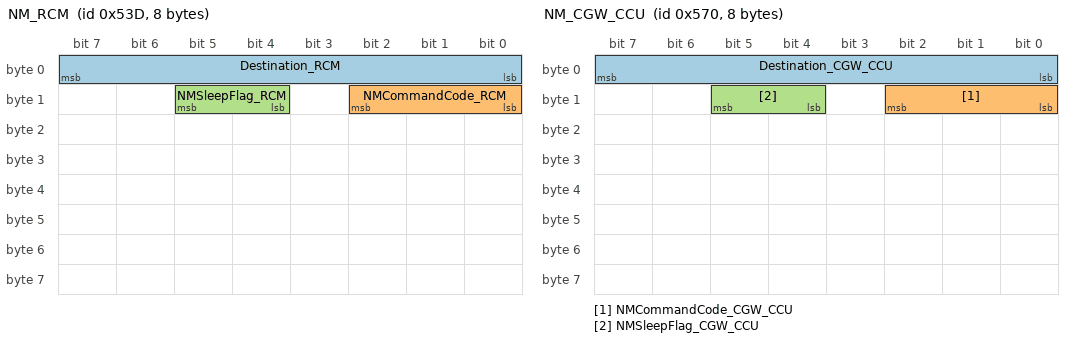
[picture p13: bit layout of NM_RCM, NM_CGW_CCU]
BO_ 1341 NM_RCM: 8 RCM
 SG_ Destination_RCM : 0|8@1+ (1,0) [0|0] ""  RLPSU,DPSU,APSU,PSB,SHVU_RR,vHS_B2,FCS,EMCU,SLB,CGW_CCU,vDummy_HS_B,ATS,RLHV,PFSU,SGU,ALBCU,DSAU,SWRC,SHVU_FR,RCS,RRPSU,BLTN_CAM,SCM,DLBCU,OHCL,RWPC,RRHV,WPC,HOD,ASAU
 SG_ NMCommandCode_RCM : 8|3@1+ (1,0) [0|0] ""  RLPSU,DPSU,APSU,PSB,SHVU_RR,vHS_B2,FCS,EMCU,SLB,CGW_CCU,vDummy_HS_B,ATS,RLHV,PFSU,SGU,ALBCU,DSAU,SWRC,SHVU_FR,RCS,RRPSU,BLTN_CAM,SCM,DLBCU,OHCL,RWPC,RRHV,WPC,HOD,ASAU
 SG_ NMSleepFlag_RCM : 12|2@1+ (1,0) [0|0] ""  RLPSU,DPSU,APSU,PSB,SHVU_RR,vHS_B2,FCS,EMCU,SLB,CGW_CCU,vDummy_HS_B,ATS,RLHV,PFSU,SGU,ALBCU,DSAU,SWRC,SHVU_FR,RCS,RRPSU,BLTN_CAM,SCM,DLBCU,OHCL,RWPC,RRHV,WPC,HOD,ASAU

BO_ 1392 NM_CGW_CCU: 8 CGW_CCU
 SG_ Destination_CGW_CCU : 0|8@1+ (1,0) [0|0] ""  RLPSU,DPSU,APSU,PSB,SHVU_RR,vHS_B2,FCS,EMCU,SLB,RCM,vDummy_HS_B,ATS,RLHV,PFSU,SGU,ALBCU,DSAU,SWRC,SHVU_FR,RCS,RRPSU,BLTN_CAM,SCM,DLBCU,OHCL,RWPC,RRHV,WPC,HOD,ASAU
 SG_ NMCommandCode_CGW_CCU : 8|3@1+ (1,0) [0|0] ""  RLPSU,DPSU,APSU,PSB,SHVU_RR,vHS_B2,FCS,EMCU,SLB,RCM,vDummy_HS_B,ATS,RLHV,PFSU,SGU,ALBCU,DSAU,SWRC,SHVU_FR,RCS,RRPSU,BLTN_CAM,SCM,DLBCU,OHCL,RWPC,RRHV,WPC,HOD,ASAU
 SG_ NMSleepFlag_CGW_CCU : 12|2@1+ (1,0) [0|0] ""  RLPSU,DPSU,APSU,PSB,SHVU_RR,vHS_B2,FCS,EMCU,SLB,RCM,vDummy_HS_B,ATS,RLHV,PFSU,SGU,ALBCU,DSAU,SWRC,SHVU_FR,RCS,RRPSU,BLTN_CAM,SCM,DLBCU,OHCL,RWPC,RRHV,WPC,HOD,ASAU

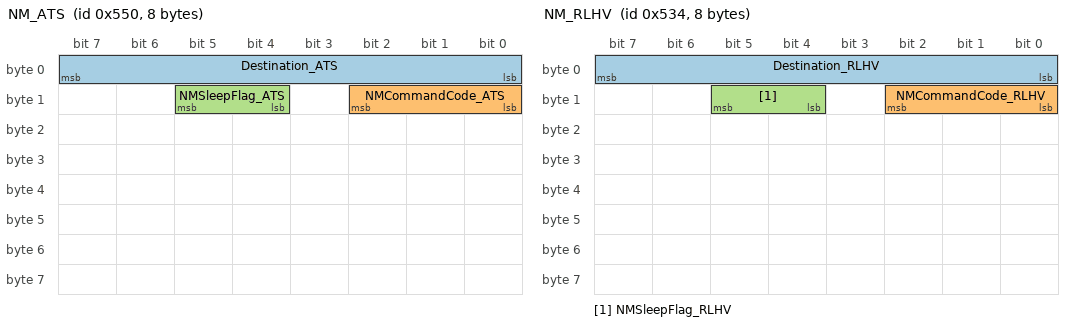
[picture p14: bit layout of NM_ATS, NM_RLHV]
BO_ 1360 NM_ATS: 8 ATS
 SG_ Destination_ATS : 0|8@1+ (1,0) [0|0] ""  RLPSU,DPSU,APSU,PSB,SHVU_RR,vHS_B2,FCS,EMCU,SLB,RCM,CGW_CCU,vDummy_HS_B,RLHV,PFSU,SGU,ALBCU,DSAU,SWRC,SHVU_FR,RCS,RRPSU,BLTN_CAM,SCM,DLBCU,OHCL,RWPC,RRHV,WPC,HOD,ASAU
 SG_ NMCommandCode_ATS : 8|3@1+ (1,0) [0|0] ""  RLPSU,DPSU,APSU,PSB,SHVU_RR,vHS_B2,FCS,EMCU,SLB,RCM,CGW_CCU,vDummy_HS_B,RLHV,PFSU,SGU,ALBCU,DSAU,SWRC,SHVU_FR,RCS,RRPSU,BLTN_CAM,SCM,DLBCU,OHCL,RWPC,RRHV,WPC,HOD,ASAU
 SG_ NMSleepFlag_ATS : 12|2@1+ (1,0) [0|0] ""  RLPSU,DPSU,APSU,PSB,SHVU_RR,vHS_B2,FCS,EMCU,SLB,RCM,CGW_CCU,vDummy_HS_B,RLHV,PFSU,SGU,ALBCU,DSAU,SWRC,SHVU_FR,RCS,RRPSU,BLTN_CAM,SCM,DLBCU,OHCL,RWPC,RRHV,WPC,HOD,ASAU

BO_ 1332 NM_RLHV: 8 RLHV
 SG_ Destination_RLHV : 0|8@1+ (1,0) [0|0] ""  RLPSU,DPSU,APSU,PSB,SHVU_RR,vHS_B2,FCS,EMCU,SLB,RCM,CGW_CCU,vDummy_HS_B,ATS,PFSU,SGU,ALBCU,DSAU,SWRC,SHVU_FR,RCS,RRPSU,BLTN_CAM,SCM,DLBCU,OHCL,RWPC,RRHV,WPC,HOD,ASAU
 SG_ NMCommandCode_RLHV : 8|3@1+ (1,0) [0|0] ""  RLPSU,DPSU,APSU,PSB,SHVU_RR,vHS_B2,FCS,EMCU,SLB,RCM,CGW_CCU,vDummy_HS_B,ATS,PFSU,SGU,ALBCU,DSAU,SWRC,SHVU_FR,RCS,RRPSU,BLTN_CAM,SCM,DLBCU,OHCL,RWPC,RRHV,WPC,HOD,ASAU
 SG_ NMSleepFlag_RLHV : 12|2@1+ (1,0) [0|0] ""  RLPSU,DPSU,APSU,PSB,SHVU_RR,vHS_B2,FCS,EMCU,SLB,RCM,CGW_CCU,vDummy_HS_B,ATS,PFSU,SGU,ALBCU,DSAU,SWRC,SHVU_FR,RCS,RRPSU,BLTN_CAM,SCM,DLBCU,OHCL,RWPC,RRHV,WPC,HOD,ASAU

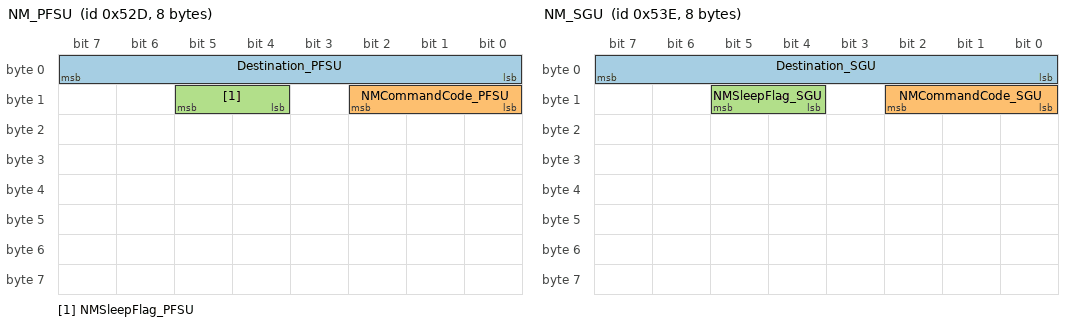
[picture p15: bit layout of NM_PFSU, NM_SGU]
BO_ 1325 NM_PFSU: 8 PFSU
 SG_ Destination_PFSU : 0|8@1+ (1,0) [0|0] ""  RLPSU,DPSU,APSU,PSB,SHVU_RR,vHS_B2,FCS,EMCU,SLB,RCM,CGW_CCU,vDummy_HS_B,ATS,RLHV,SGU,ALBCU,DSAU,SWRC,SHVU_FR,RCS,RRPSU,BLTN_CAM,SCM,DLBCU,OHCL,RWPC,RRHV,WPC,HOD,ASAU
 SG_ NMCommandCode_PFSU : 8|3@1+ (1,0) [0|0] ""  RLPSU,DPSU,APSU,PSB,SHVU_RR,vHS_B2,FCS,EMCU,SLB,RCM,CGW_CCU,vDummy_HS_B,ATS,RLHV,SGU,ALBCU,DSAU,SWRC,SHVU_FR,RCS,RRPSU,BLTN_CAM,SCM,DLBCU,OHCL,RWPC,RRHV,WPC,HOD,ASAU
 SG_ NMSleepFlag_PFSU : 12|2@1+ (1,0) [0|0] ""  RLPSU,DPSU,APSU,PSB,SHVU_RR,vHS_B2,FCS,EMCU,SLB,RCM,CGW_CCU,vDummy_HS_B,ATS,RLHV,SGU,ALBCU,DSAU,SWRC,SHVU_FR,RCS,RRPSU,BLTN_CAM,SCM,DLBCU,OHCL,RWPC,RRHV,WPC,HOD,ASAU

BO_ 1342 NM_SGU: 8 SGU
 SG_ Destination_SGU : 0|8@1+ (1,0) [0|0] ""  RLPSU,DPSU,APSU,PSB,SHVU_RR,vHS_B2,FCS,EMCU,SLB,RCM,CGW_CCU,vDummy_HS_B,ATS,RLHV,PFSU,ALBCU,DSAU,SWRC,SHVU_FR,RCS,RRPSU,BLTN_CAM,SCM,DLBCU,OHCL,RWPC,RRHV,WPC,HOD,ASAU
 SG_ NMCommandCode_SGU : 8|3@1+ (1,0) [0|0] ""  RLPSU,DPSU,APSU,PSB,SHVU_RR,vHS_B2,FCS,EMCU,SLB,RCM,CGW_CCU,vDummy_HS_B,ATS,RLHV,PFSU,ALBCU,DSAU,SWRC,SHVU_FR,RCS,RRPSU,BLTN_CAM,SCM,DLBCU,OHCL,RWPC,RRHV,WPC,HOD,ASAU
 SG_ NMSleepFlag_SGU : 12|2@1+ (1,0) [0|0] ""  RLPSU,DPSU,APSU,PSB,SHVU_RR,vHS_B2,FCS,EMCU,SLB,RCM,CGW_CCU,vDummy_HS_B,ATS,RLHV,PFSU,ALBCU,DSAU,SWRC,SHVU_FR,RCS,RRPSU,BLTN_CAM,SCM,DLBCU,OHCL,RWPC,RRHV,WPC,HOD,ASAU

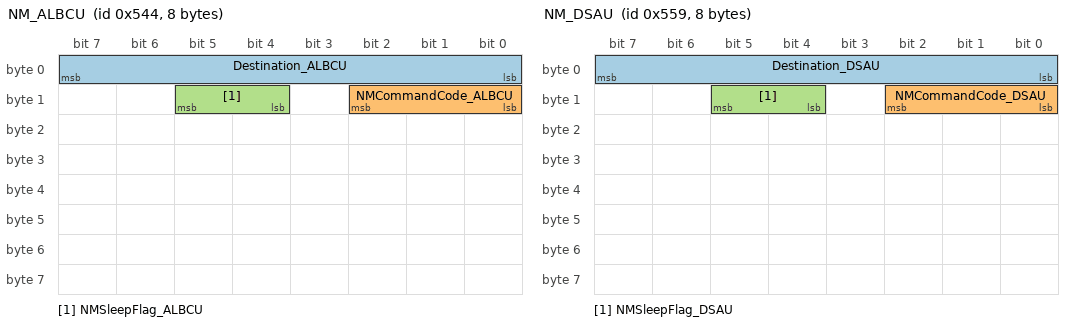
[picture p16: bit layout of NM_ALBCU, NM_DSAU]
BO_ 1348 NM_ALBCU: 8 ALBCU
 SG_ Destination_ALBCU : 0|8@1+ (1,0) [0|0] ""  RLPSU,DPSU,APSU,PSB,SHVU_RR,vHS_B2,FCS,EMCU,SLB,RCM,CGW_CCU,vDummy_HS_B,ATS,RLHV,PFSU,SGU,DSAU,SWRC,SHVU_FR,RCS,RRPSU,BLTN_CAM,SCM,DLBCU,OHCL,RWPC,RRHV,WPC,HOD,ASAU
 SG_ NMCommandCode_ALBCU : 8|3@1+ (1,0) [0|0] ""  RLPSU,DPSU,APSU,PSB,SHVU_RR,vHS_B2,FCS,EMCU,SLB,RCM,CGW_CCU,vDummy_HS_B,ATS,RLHV,PFSU,SGU,DSAU,SWRC,SHVU_FR,RCS,RRPSU,BLTN_CAM,SCM,DLBCU,OHCL,RWPC,RRHV,WPC,HOD,ASAU
 SG_ NMSleepFlag_ALBCU : 12|2@1+ (1,0) [0|0] ""  RLPSU,DPSU,APSU,PSB,SHVU_RR,vHS_B2,FCS,EMCU,SLB,RCM,CGW_CCU,vDummy_HS_B,ATS,RLHV,PFSU,SGU,DSAU,SWRC,SHVU_FR,RCS,RRPSU,BLTN_CAM,SCM,DLBCU,OHCL,RWPC,RRHV,WPC,HOD,ASAU

BO_ 1369 NM_DSAU: 8 DSAU
 SG_ Destination_DSAU : 0|8@1+ (1,0) [0|0] ""  RLPSU,DPSU,APSU,PSB,SHVU_RR,vHS_B2,FCS,EMCU,SLB,RCM,CGW_CCU,vDummy_HS_B,ATS,RLHV,PFSU,SGU,ALBCU,SWRC,SHVU_FR,RCS,RRPSU,BLTN_CAM,SCM,DLBCU,OHCL,RWPC,RRHV,WPC,HOD,ASAU
 SG_ NMCommandCode_DSAU : 8|3@1+ (1,0) [0|0] ""  RLPSU,DPSU,APSU,PSB,SHVU_RR,vHS_B2,FCS,EMCU,SLB,RCM,CGW_CCU,vDummy_HS_B,ATS,RLHV,PFSU,SGU,ALBCU,SWRC,SHVU_FR,RCS,RRPSU,BLTN_CAM,SCM,DLBCU,OHCL,RWPC,RRHV,WPC,HOD,ASAU
 SG_ NMSleepFlag_DSAU : 12|2@1+ (1,0) [0|0] ""  RLPSU,DPSU,APSU,PSB,SHVU_RR,vHS_B2,FCS,EMCU,SLB,RCM,CGW_CCU,vDummy_HS_B,ATS,RLHV,PFSU,SGU,ALBCU,SWRC,SHVU_FR,RCS,RRPSU,BLTN_CAM,SCM,DLBCU,OHCL,RWPC,RRHV,WPC,HOD,ASAU

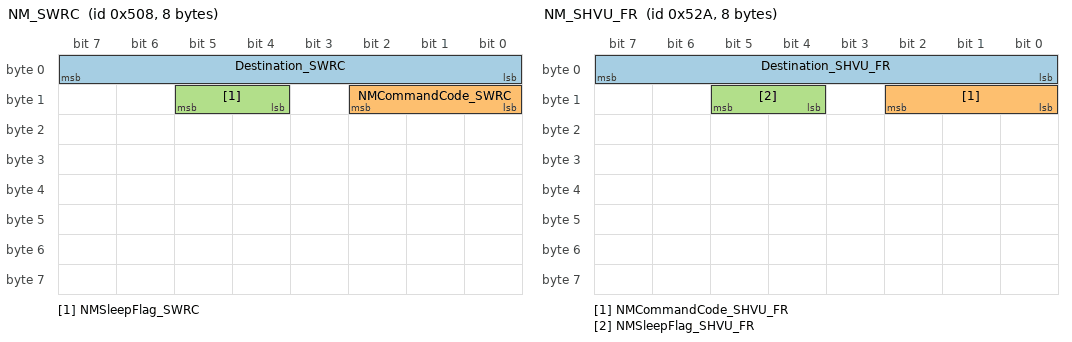
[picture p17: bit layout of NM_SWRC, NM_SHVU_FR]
BO_ 1288 NM_SWRC: 8 SWRC
 SG_ Destination_SWRC : 0|8@1+ (1,0) [0|0] ""  RLPSU,DPSU,APSU,PSB,SHVU_RR,vHS_B2,FCS,EMCU,SLB,RCM,CGW_CCU,vDummy_HS_B,ATS,RLHV,PFSU,SGU,ALBCU,DSAU,SHVU_FR,RCS,RRPSU,BLTN_CAM,SCM,DLBCU,OHCL,RWPC,RRHV,WPC,HOD,ASAU
 SG_ NMCommandCode_SWRC : 8|3@1+ (1,0) [0|0] ""  RLPSU,DPSU,APSU,PSB,SHVU_RR,vHS_B2,FCS,EMCU,SLB,RCM,CGW_CCU,vDummy_HS_B,ATS,RLHV,PFSU,SGU,ALBCU,DSAU,SHVU_FR,RCS,RRPSU,BLTN_CAM,SCM,DLBCU,OHCL,RWPC,RRHV,WPC,HOD,ASAU
 SG_ NMSleepFlag_SWRC : 12|2@1+ (1,0) [0|0] ""  RLPSU,DPSU,APSU,PSB,SHVU_RR,vHS_B2,FCS,EMCU,SLB,RCM,CGW_CCU,vDummy_HS_B,ATS,RLHV,PFSU,SGU,ALBCU,DSAU,SHVU_FR,RCS,RRPSU,BLTN_CAM,SCM,DLBCU,OHCL,RWPC,RRHV,WPC,HOD,ASAU

BO_ 1322 NM_SHVU_FR: 8 SHVU_FR
 SG_ Destination_SHVU_FR : 0|8@1+ (1,0) [0|0] ""  RLPSU,DPSU,APSU,PSB,SHVU_RR,vHS_B2,FCS,EMCU,SLB,RCM,CGW_CCU,vDummy_HS_B,ATS,RLHV,PFSU,SGU,ALBCU,DSAU,SWRC,RCS,RRPSU,BLTN_CAM,SCM,DLBCU,OHCL,RWPC,RRHV,WPC,HOD,ASAU
 SG_ NMCommandCode_SHVU_FR : 8|3@1+ (1,0) [0|0] ""  RLPSU,DPSU,APSU,PSB,SHVU_RR,vHS_B2,FCS,EMCU,SLB,RCM,CGW_CCU,vDummy_HS_B,ATS,RLHV,PFSU,SGU,ALBCU,DSAU,SWRC,RCS,RRPSU,BLTN_CAM,SCM,DLBCU,OHCL,RWPC,RRHV,WPC,HOD,ASAU
 SG_ NMSleepFlag_SHVU_FR : 12|2@1+ (1,0) [0|0] ""  RLPSU,DPSU,APSU,PSB,SHVU_RR,vHS_B2,FCS,EMCU,SLB,RCM,CGW_CCU,vDummy_HS_B,ATS,RLHV,PFSU,SGU,ALBCU,DSAU,SWRC,RCS,RRPSU,BLTN_CAM,SCM,DLBCU,OHCL,RWPC,RRHV,WPC,HOD,ASAU

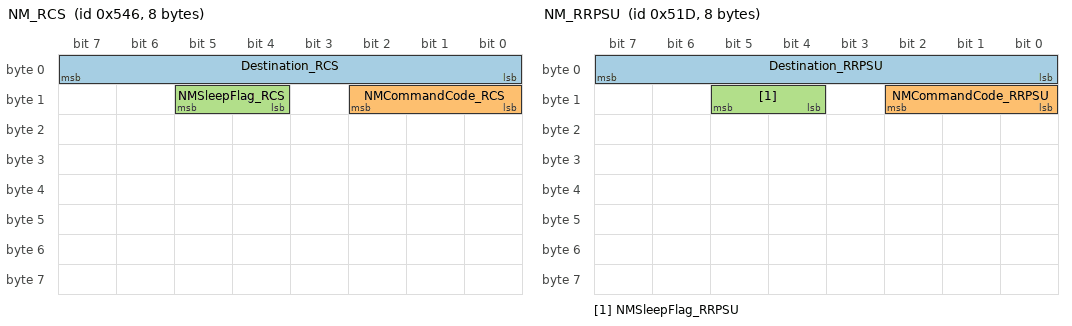
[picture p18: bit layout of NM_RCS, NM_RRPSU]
BO_ 1350 NM_RCS: 8 RCS
 SG_ Destination_RCS : 0|8@1+ (1,0) [0|0] ""  RLPSU,DPSU,APSU,PSB,SHVU_RR,vHS_B2,FCS,EMCU,SLB,RCM,CGW_CCU,vDummy_HS_B,ATS,RLHV,PFSU,SGU,ALBCU,DSAU,SWRC,SHVU_FR,RRPSU,BLTN_CAM,SCM,DLBCU,OHCL,RWPC,RRHV,WPC,HOD,ASAU
 SG_ NMCommandCode_RCS : 8|3@1+ (1,0) [0|0] ""  RLPSU,DPSU,APSU,PSB,SHVU_RR,vHS_B2,FCS,EMCU,SLB,RCM,CGW_CCU,vDummy_HS_B,ATS,RLHV,PFSU,SGU,ALBCU,DSAU,SWRC,SHVU_FR,RRPSU,BLTN_CAM,SCM,DLBCU,OHCL,RWPC,RRHV,WPC,HOD,ASAU
 SG_ NMSleepFlag_RCS : 12|2@1+ (1,0) [0|0] ""  RLPSU,DPSU,APSU,PSB,SHVU_RR,vHS_B2,FCS,EMCU,SLB,RCM,CGW_CCU,vDummy_HS_B,ATS,RLHV,PFSU,SGU,ALBCU,DSAU,SWRC,SHVU_FR,RRPSU,BLTN_CAM,SCM,DLBCU,OHCL,RWPC,RRHV,WPC,HOD,ASAU

BO_ 1309 NM_RRPSU: 8 RRPSU
 SG_ Destination_RRPSU : 0|8@1+ (1,0) [0|0] ""  RLPSU,DPSU,APSU,PSB,SHVU_RR,vHS_B2,FCS,EMCU,SLB,RCM,CGW_CCU,vDummy_HS_B,ATS,RLHV,PFSU,SGU,ALBCU,DSAU,SWRC,SHVU_FR,RCS,BLTN_CAM,SCM,DLBCU,OHCL,RWPC,RRHV,WPC,HOD,ASAU
 SG_ NMCommandCode_RRPSU : 8|3@1+ (1,0) [0|0] ""  RLPSU,DPSU,APSU,PSB,SHVU_RR,vHS_B2,FCS,EMCU,SLB,RCM,CGW_CCU,vDummy_HS_B,ATS,RLHV,PFSU,SGU,ALBCU,DSAU,SWRC,SHVU_FR,RCS,BLTN_CAM,SCM,DLBCU,OHCL,RWPC,RRHV,WPC,HOD,ASAU
 SG_ NMSleepFlag_RRPSU : 12|2@1+ (1,0) [0|0] ""  RLPSU,DPSU,APSU,PSB,SHVU_RR,vHS_B2,FCS,EMCU,SLB,RCM,CGW_CCU,vDummy_HS_B,ATS,RLHV,PFSU,SGU,ALBCU,DSAU,SWRC,SHVU_FR,RCS,BLTN_CAM,SCM,DLBCU,OHCL,RWPC,RRHV,WPC,HOD,ASAU

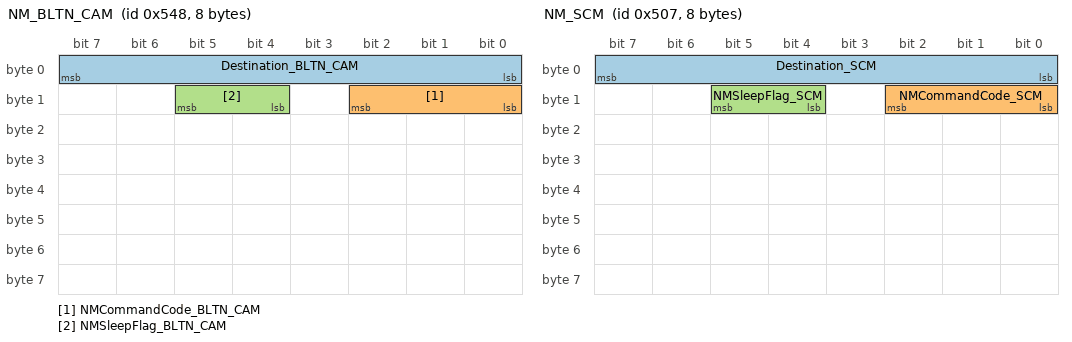
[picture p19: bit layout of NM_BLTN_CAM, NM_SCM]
BO_ 1352 NM_BLTN_CAM: 8 BLTN_CAM
 SG_ Destination_BLTN_CAM : 0|8@1+ (1,0) [0|0] ""  RLPSU,DPSU,APSU,PSB,SHVU_RR,vHS_B2,FCS,EMCU,SLB,RCM,CGW_CCU,vDummy_HS_B,ATS,RLHV,PFSU,SGU,ALBCU,DSAU,SWRC,SHVU_FR,RCS,RRPSU,SCM,DLBCU,OHCL,RWPC,RRHV,WPC,HOD,ASAU
 SG_ NMCommandCode_BLTN_CAM : 8|3@1+ (1,0) [0|0] ""  RLPSU,DPSU,APSU,PSB,SHVU_RR,vHS_B2,FCS,EMCU,SLB,RCM,CGW_CCU,vDummy_HS_B,ATS,RLHV,PFSU,SGU,ALBCU,DSAU,SWRC,SHVU_FR,RCS,RRPSU,SCM,DLBCU,OHCL,RWPC,RRHV,WPC,HOD,ASAU
 SG_ NMSleepFlag_BLTN_CAM : 12|2@1+ (1,0) [0|0] ""  RLPSU,DPSU,APSU,PSB,SHVU_RR,vHS_B2,FCS,EMCU,SLB,RCM,CGW_CCU,vDummy_HS_B,ATS,RLHV,PFSU,SGU,ALBCU,DSAU,SWRC,SHVU_FR,RCS,RRPSU,SCM,DLBCU,OHCL,RWPC,RRHV,WPC,HOD,ASAU

BO_ 1287 NM_SCM: 8 SCM
 SG_ Destination_SCM : 0|8@1+ (1,0) [0|0] ""  RLPSU,DPSU,APSU,PSB,SHVU_RR,vHS_B2,FCS,EMCU,SLB,RCM,CGW_CCU,vDummy_HS_B,ATS,RLHV,PFSU,SGU,ALBCU,DSAU,SWRC,SHVU_FR,RCS,RRPSU,BLTN_CAM,DLBCU,OHCL,RWPC,RRHV,WPC,HOD,ASAU
 SG_ NMCommandCode_SCM : 8|3@1+ (1,0) [0|0] ""  RLPSU,DPSU,APSU,PSB,SHVU_RR,vHS_B2,FCS,EMCU,SLB,RCM,CGW_CCU,vDummy_HS_B,ATS,RLHV,PFSU,SGU,ALBCU,DSAU,SWRC,SHVU_FR,RCS,RRPSU,BLTN_CAM,DLBCU,OHCL,RWPC,RRHV,WPC,HOD,ASAU
 SG_ NMSleepFlag_SCM : 12|2@1+ (1,0) [0|0] ""  RLPSU,DPSU,APSU,PSB,SHVU_RR,vHS_B2,FCS,EMCU,SLB,RCM,CGW_CCU,vDummy_HS_B,ATS,RLHV,PFSU,SGU,ALBCU,DSAU,SWRC,SHVU_FR,RCS,RRPSU,BLTN_CAM,DLBCU,OHCL,RWPC,RRHV,WPC,HOD,ASAU

BO_ 1344 NM_DLBCU: 8 DLBCU
 SG_ Destination_DLBCU : 0|8@1+ (1,0) [0|0] ""  RLPSU,DPSU,APSU,PSB,SHVU_RR,vHS_B2,FCS,EMCU,SLB,RCM,CGW_CCU,vDummy_HS_B,ATS,RLHV,PFSU,SGU,ALBCU,DSAU,SWRC,SHVU_FR,RCS,RRPSU,BLTN_CAM,SCM,OHCL,RWPC,RRHV,WPC,HOD,ASAU
 SG_ NMCommandCode_DLBCU : 8|3@1+ (1,0) [0|0] ""  RLPSU,DPSU,APSU,PSB,SHVU_RR,vHS_B2,FCS,EMCU,SLB,RCM,CGW_CCU,vDummy_HS_B,ATS,RLHV,PFSU,SGU,ALBCU,DSAU,SWRC,SHVU_FR,RCS,RRPSU,BLTN_CAM,SCM,OHCL,RWPC,RRHV,WPC,HOD,ASAU
 SG_ NMSleepFlag_DLBCU : 12|2@1+ (1,0) [0|0] ""  RLPSU,DPSU,APSU,PSB,SHVU_RR,vHS_B2,FCS,EMCU,SLB,RCM,CGW_CCU,vDummy_HS_B,ATS,RLHV,PFSU,SGU,ALBCU,DSAU,SWRC,SHVU_FR,RCS,RRPSU,BLTN_CAM,SCM,OHCL,RWPC,RRHV,WPC,HOD,ASAU

BO_ 1364 NM_OHCL: 8 OHCL
 SG_ Destination_OHCL : 0|8@1+ (1,0) [0|0] ""  RLPSU,DPSU,APSU,PSB,SHVU_RR,vHS_B2,FCS,EMCU,SLB,RCM,CGW_CCU,vDummy_HS_B,ATS,RLHV,PFSU,SGU,ALBCU,DSAU,SWRC,SHVU_FR,RCS,RRPSU,BLTN_CAM,SCM,DLBCU,RWPC,RRHV,WPC,HOD,ASAU
 SG_ NMCommandCode_OHCL : 8|3@1+ (1,0) [0|0] ""  RLPSU,DPSU,APSU,PSB,SHVU_RR,vHS_B2,FCS,EMCU,SLB,RCM,CGW_CCU,vDummy_HS_B,ATS,RLHV,PFSU,SGU,ALBCU,DSAU,SWRC,SHVU_FR,RCS,RRPSU,BLTN_CAM,SCM,DLBCU,RWPC,RRHV,WPC,HOD,ASAU
 SG_ NMSleepFlag_OHCL : 12|2@1+ (1,0) [0|0] ""  RLPSU,DPSU,APSU,PSB,SHVU_RR,vHS_B2,FCS,EMCU,SLB,RCM,CGW_CCU,vDummy_HS_B,ATS,RLHV,PFSU,SGU,ALBCU,DSAU,SWRC,SHVU_FR,RCS,RRPSU,BLTN_CAM,SCM,DLBCU,RWPC,RRHV,WPC,HOD,ASAU

BO_ 1311 NM_RWPC: 8 RWPC
 SG_ Destination_RWPC : 0|8@1+ (1,0) [0|0] ""  RLPSU,DPSU,APSU,PSB,SHVU_RR,vHS_B2,FCS,EMCU,SLB,RCM,CGW_CCU,vDummy_HS_B,ATS,RLHV,PFSU,SGU,ALBCU,DSAU,SWRC,SHVU_FR,RCS,RRPSU,BLTN_CAM,SCM,DLBCU,OHCL,RRHV,WPC,HOD,ASAU
 SG_ NMCommandCode_RWPC : 8|3@1+ (1,0) [0|0] ""  RLPSU,DPSU,APSU,PSB,SHVU_RR,vHS_B2,FCS,EMCU,SLB,RCM,CGW_CCU,vDummy_HS_B,ATS,RLHV,PFSU,SGU,ALBCU,DSAU,SWRC,SHVU_FR,RCS,RRPSU,BLTN_CAM,SCM,DLBCU,OHCL,RRHV,WPC,HOD,ASAU
 SG_ NMSleepFlag_RWPC : 12|2@1+ (1,0) [0|0] ""  RLPSU,DPSU,APSU,PSB,SHVU_RR,vHS_B2,FCS,EMCU,SLB,RCM,CGW_CCU,vDummy_HS_B,ATS,RLHV,PFSU,SGU,ALBCU,DSAU,SWRC,SHVU_FR,RCS,RRPSU,BLTN_CAM,SCM,DLBCU,OHCL,RRHV,WPC,HOD,ASAU

BO_ 1333 NM_RRHV: 8 RRHV
 SG_ Destination_RRHV : 0|8@1+ (1,0) [0|0] ""  RLPSU,DPSU,APSU,PSB,SHVU_RR,vHS_B2,FCS,EMCU,SLB,RCM,CGW_CCU,vDummy_HS_B,ATS,RLHV,PFSU,SGU,ALBCU,DSAU,SWRC,SHVU_FR,RCS,RRPSU,BLTN_CAM,SCM,DLBCU,OHCL,RWPC,WPC,HOD,ASAU
 SG_ NMCommandCode_RRHV : 8|3@1+ (1,0) [0|0] ""  RLPSU,DPSU,APSU,PSB,SHVU_RR,vHS_B2,FCS,EMCU,SLB,RCM,CGW_CCU,vDummy_HS_B,ATS,RLHV,PFSU,SGU,ALBCU,DSAU,SWRC,SHVU_FR,RCS,RRPSU,BLTN_CAM,SCM,DLBCU,OHCL,RWPC,WPC,HOD,ASAU
 SG_ NMSleepFlag_RRHV : 12|2@1+ (1,0) [0|0] ""  RLPSU,DPSU,APSU,PSB,SHVU_RR,vHS_B2,FCS,EMCU,SLB,RCM,CGW_CCU,vDummy_HS_B,ATS,RLHV,PFSU,SGU,ALBCU,DSAU,SWRC,SHVU_FR,RCS,RRPSU,BLTN_CAM,SCM,DLBCU,OHCL,RWPC,WPC,HOD,ASAU

BO_ 1310 NM_WPC: 8 WPC
 SG_ Destination_WPC : 0|8@1+ (1,0) [0|0] ""  RLPSU,DPSU,APSU,PSB,SHVU_RR,vHS_B2,FCS,EMCU,SLB,RCM,CGW_CCU,vDummy_HS_B,ATS,RLHV,PFSU,SGU,ALBCU,DSAU,SWRC,SHVU_FR,RCS,RRPSU,BLTN_CAM,SCM,DLBCU,OHCL,RWPC,RRHV,HOD,ASAU
 SG_ NMCommandCode_WPC : 8|3@1+ (1,0) [0|0] ""  RLPSU,DPSU,APSU,PSB,SHVU_RR,vHS_B2,FCS,EMCU,SLB,RCM,CGW_CCU,vDummy_HS_B,ATS,RLHV,PFSU,SGU,ALBCU,DSAU,SWRC,SHVU_FR,RCS,RRPSU,BLTN_CAM,SCM,DLBCU,OHCL,RWPC,RRHV,HOD,ASAU
 SG_ NMSleepFlag_WPC : 12|2@1+ (1,0) [0|0] ""  RLPSU,DPSU,APSU,PSB,SHVU_RR,vHS_B2,FCS,EMCU,SLB,RCM,CGW_CCU,vDummy_HS_B,ATS,RLHV,PFSU,SGU,ALBCU,DSAU,SWRC,SHVU_FR,RCS,RRPSU,BLTN_CAM,SCM,DLBCU,OHCL,RWPC,RRHV,HOD,ASAU

BO_ 1354 NM_HOD: 8 HOD
 SG_ Destination_HOD : 0|8@1+ (1,0) [0|0] ""  RLPSU,DPSU,APSU,PSB,SHVU_RR,vHS_B2,FCS,EMCU,SLB,RCM,CGW_CCU,vDummy_HS_B,ATS,RLHV,PFSU,SGU,ALBCU,DSAU,SWRC,SHVU_FR,RCS,RRPSU,BLTN_CAM,SCM,DLBCU,OHCL,RWPC,RRHV,WPC,ASAU
 SG_ NMCommandCode_HOD : 8|3@1+ (1,0) [0|0] ""  RLPSU,DPSU,APSU,PSB,SHVU_RR,vHS_B2,FCS,EMCU,SLB,RCM,CGW_CCU,vDummy_HS_B,ATS,RLHV,PFSU,SGU,ALBCU,DSAU,SWRC,SHVU_FR,RCS,RRPSU,BLTN_CAM,SCM,DLBCU,OHCL,RWPC,RRHV,WPC,ASAU
 SG_ NMSleepFlag_HOD : 12|2@1+ (1,0) [0|0] ""  RLPSU,DPSU,APSU,PSB,SHVU_RR,vHS_B2,FCS,EMCU,SLB,RCM,CGW_CCU,vDummy_HS_B,ATS,RLHV,PFSU,SGU,ALBCU,DSAU,SWRC,SHVU_FR,RCS,RRPSU,BLTN_CAM,SCM,DLBCU,OHCL,RWPC,RRHV,WPC,ASAU

BO_ 1363 NM_ASAU: 8 ASAU
 SG_ Destination_ASAU : 0|8@1+ (1,0) [0|0] ""  RLPSU,DPSU,APSU,PSB,SHVU_RR,vHS_B2,FCS,EMCU,SLB,RCM,CGW_CCU,vDummy_HS_B,ATS,RLHV,PFSU,SGU,ALBCU,DSAU,SWRC,SHVU_FR,RCS,RRPSU,BLTN_CAM,SCM,DLBCU,OHCL,RWPC,RRHV,WPC,HOD
 SG_ NMCommandCode_ASAU : 8|3@1+ (1,0) [0|0] ""  RLPSU,DPSU,APSU,PSB,SHVU_RR,vHS_B2,FCS,EMCU,SLB,RCM,CGW_CCU,vDummy_HS_B,ATS,RLHV,PFSU,SGU,ALBCU,DSAU,SWRC,SHVU_FR,RCS,RRPSU,BLTN_CAM,SCM,DLBCU,OHCL,RWPC,RRHV,WPC,HOD
 SG_ NMSleepFlag_ASAU : 12|2@1+ (1,0) [0|0] ""  RLPSU,DPSU,APSU,PSB,SHVU_RR,vHS_B2,FCS,EMCU,SLB,RCM,CGW_CCU,vDummy_HS_B,ATS,RLHV,PFSU,SGU,ALBCU,DSAU,SWRC,SHVU_FR,RCS,RRPSU,BLTN_CAM,SCM,DLBCU,OHCL,RWPC,RRHV,WPC,HOD

CM_ BO_ 2151682049 "[EW] On Event and On Write";
CM_ SG_ 2151682049 ACU_Crc2Val "ACU_CyclicRedundancyCheck2Value";
CM_ SG_ 2151682049 ACU_AlvCnt2Val "ACU_AliveCounter2Value";
CM_ SG_ 2151682049 ACU_CrshActvSta "ACU_CrashActiveStatus ##2G##ACU - ACU13 - CF_Acu_CshAct";
CM_ SG_ 2151682049 ACU_CrshInfo "ACU Crash Event information";
CM_ SG_ 2151682049 ACU_CrshTyp "Indication of crash type";
CM_ BO_ 981 "[PE] Periodic and On Event";
CM_ SG_ 981 APSS_StExtFwdMvBtn "APSS_ExtensionForwardMoveButton";
CM_ SG_ 981 APSS_StSldFwdMvBtn "APSS_SlideForwardMoveButton";
CM_ SG_ 981 APSS_StSldBwdMvBtn "APSS_SlideBackwardMoveButton";
CM_ SG_ 981 APSS_StExtBwdMvBtn "APSS_ExtensionBackwardMoveButton";
CM_ SG_ 981 APSS_StRclFwdMvBtn "APSS_ReclinerForwardMoveButton";
CM_ SG_ 981 APSS_StRclBwdMvBtn "APSS_ReclinerBackwardMoveButton";
CM_ SG_ 981 APSS_StHgtUpMvBtn "APSS_HeightUpMoveButton";
CM_ SG_ 981 APSS_StHgtDnMvBtn "APSS_HeightDownMoveButton";
CM_ SG_ 981 APSS_StTltUpMvBtn "APSS_TiltUpMoveButton";
CM_ SG_ 981 APSS_StTltDnMvBtn "APSS_TiltDownMoveButton";
CM_ SG_ 981 APSS_StHRestUpMvBtn "APSS_Head Rest Up Move Button";
CM_ SG_ 981 APSS_StHRestDnMvBtn "APSS_Head Rest Down Move Button";
CM_ SG_ 981 APSS_StHRestFwdMvBtn "APSS_Head Rest Forward Move Button";
CM_ SG_ 981 APSS_StHRestBwdMvBtn "APSS_Head Rest Backward Move Button";
CM_ SG_ 981 APSS_StLegUpMvBtn "APSS_LegUpMoveButton";
CM_ SG_ 981 APSS_StLegDnMvBtn "APSS_LegDownMoveButton";
CM_ SG_ 981 APSS_StRlxModeBtn "APSS_RelaxModeButton";
CM_ SG_ 981 APSS_StRlxReturnBtn "APSS_RelaxReturnButton";
CM_ SG_ 981 APSS_StRlxTltUpMvBtn "APSS_RelaxTiltUpMoveButton";
CM_ SG_ 981 APSS_StRlxTltDnMvBtn "APSS_RelaxTiltDownMoveButton";
CM_ BO_ 1951 "[TP] Transport Protocol";
CM_ BO_ 1466 "[TP] Transport Protocol";
CM_ SG_ 1466 ATS_GST_Byte0 "Diag Response from ATS";
CM_ SG_ 1466 ATS_GST_Byte2 "Diag Response from ATS";
CM_ SG_ 1466 ATS_GST_Byte3 "Diag Response from ATS";
CM_ SG_ 1466 ATS_GST_Byte4 "Diag Response from ATS";
CM_ SG_ 1466 ATS_GST_Byte5 "Diag Response from ATS";
CM_ SG_ 1466 ATS_GST_Byte6 "Diag Response from ATS";
CM_ SG_ 1466 ATS_GST_Byte7 "Diag Response from ATS";
CM_ SG_ 1466 ATS_GST_Byte1 "Diag Response from ATS";
CM_ BO_ 963 "[PE] Periodic and On Event";
CM_ SG_ 963 BCM_Crc16Val "BCM_CyclicRedundancyCheck16Value";
CM_ SG_ 963 BCM_AlvCnt16Val "BCM_AliveCounter16Value";
CM_ SG_ 963 IBU_SWVerMajor1 "First Word(ASCII) in IBU S/W Ver";
CM_ SG_ 963 IBU_SWVerMinor1 "Second Word(ASCII) in IBU S/W Ver";
CM_ SG_ 963 IBU_SWVerMinor2 "Third Word(ASCII) in IBU S/W Ver";
CM_ BO_ 983 "[PE] Periodic and On Event";
CM_ SG_ 983 BLTN_CAM_SWVerMajor "First Word(ASCII) in Built-in Cam S/W Ver";
CM_ SG_ 983 BLTN_CAM_SWVerMinor2 "Minor2 in Built-in Cam S/W Ver";
CM_ SG_ 983 BLTN_CAM_SWVerMinor3 "Minor3 in Built-in Cam S/W Ver";
CM_ SG_ 983 BLTN_CAM_SWVerMinor1 "Minor1 in Built-in Cam S/W Ver";
CM_ BO_ 2328014849 "[P] Periodic";
CM_ SG_ 2328014849 DATC_Crc17Val "DATC_CyclicRedundancyCheck17Value";
CM_ SG_ 2328014849 DATC_AlvCnt17Val "DATC_AliveCounter17Value";
CM_ SG_ 2328014849 DATC_FrontPwmIsVolt "DATC Blow Motor converted Voltage";
CM_ SG_ 2328014849 DATC_FrontBlwDuty "DATC Blow Motor command duty";
CM_ SG_ 2328014849 DATC_FrontBlwDiagStat "DATC Blow Motor diagnosis state";
CM_ SG_ 2328014849 DATC_BlwrLvl_Ps "DATC_BlowerLevel_Passenger";
CM_ SG_ 2328014849 DATC_BlwrLvl_Rr "DATC_BlowerLevel_Rear";
CM_ SG_ 2328014849 DATC_SwlSta "SRS Warning lamp status";
CM_ BO_ 2328014850 "[P] Periodic";
CM_ SG_ 2328014850 DATC_FnDstStp "DATC_FineDustStep";
CM_ SG_ 2328014850 DATC_OutTempDispC "DATC_OutsideTemperatureDisplay(¡É)";
CM_ SG_ 2328014850 DATC_OutTempDispF "DATC_OutsideTemperatureDisplay(¢µ)";
CM_ SG_ 2328014850 DATC_EngOffReqWaterTemp "Cooling water temperature conditions to request the engine off";
CM_ SG_ 2328014850 DATC_HDPDfg_Sta "DATC_HDPAutoDefog_Status";
CM_ SG_ 2328014850 DATC_HDPSpptSWVer "DATC_HDPSupportSoftWareVersion";
CM_ SG_ 2328014850 DATC_HDPHumidity_Sta "DATC_HDPHumidity_Status";
CM_ SG_ 2328014850 DATC_FnDstStp_Detail "DATC_FineDustStep_Detail";
CM_ BO_ 2328014851 "[P] Periodic";
CM_ BO_ 2172674049 "[P] Periodic";
CM_ SG_ 2172674049 ESC_Crc1Val "ESC_CyclicRedundancyCheck1Value";
CM_ SG_ 2172674049 ESC_AlvCnt1Val "ESC_AliveCounter1Value";
CM_ SG_ 2172674049 TCS_LmpSta "TCS_LampStatus ##2G##ESC - TCS15 - TCS_LAMP";
CM_ SG_ 2172674049 TCS_OffLmpSta "TCS_OffLampStatus ##2G##ESC - TCS15 - TCS_OFF_LAMP";
CM_ SG_ 2172674049 ESC_OffTempSta "ESC_OffStepStatus ##2G##ESC - TCS15 - ESC_Off_Step";
CM_ SG_ 2172674049 ESC_OffSwSta "ESC_OffSiwtchStatus";
CM_ SG_ 2172674049 DBC_WrngLmpSta "DBC_WarningLampStatus ##2G##ESC - TCS15 - DBC_W_LAMP";
CM_ SG_ 2172674049 DBC_FuncLmpSta "DBC_FuncitonLampStatus ##2G##ESC - TCS15 - DBC_F_LAMP";
CM_ SG_ 2172674049 DBC_ClusterDis "DBC Pop-up Signal for Deactivation";
CM_ SG_ 2172674049 ESC_SprtLmpSta "ESC Sport Lamp Status ##2G##ESC - TCS15 - ESC_SPORT_LAMP";
CM_ SG_ 2172674049 ESC_BrkCtrlSta "ESC_BrakeControlStatus ##2G##ESC - TCS11 - CF_Esc_BrkCtl";
CM_ BO_ 2172674050 "[P] Periodic";
CM_ SG_ 2172674050 TCS_Sta "Status of TCS Function";
CM_ SG_ 2172674050 TCS_PreActvSta "TCS_PreActiveStatus ##2G##ESC - TCS13 - Pre_TCS_CTL";
CM_ SG_ 2172674050 DBC_Sta "Status of DBC Function";
CM_ SG_ 2172674050 TCS_TqFlag "Flag indicating positive or negative TCS Intervention";
CM_ SG_ 2172674050 MSR_TqFlag "Flag indicating positive or negative MSR Intervention";
CM_ SG_ 2172674050 HAC_Sta "Status of HAC Function";
CM_ SG_ 2172674050 BJD_Flag "Brake Judder Detection";
CM_ SG_ 2172674050 TCS_SlwTqFlag "Flag indicating positive or negative SLOW TCS Intervention";
CM_ SG_ 2172674050 TCS_Req "TCS_Request ##2G##ESC - TCS11 - TCS_REQ";
CM_ SG_ 2172674050 MSR_FuncReq "MSR_FunctionRequest ##2G##ESC - TCS11 - MSR_C_REQ";
CM_ SG_ 2172674050 TCS_GearShftCharacteristicVal "TCS_GearShiftCharacteristicValue ##2G##ESC - TCS11 - TCS_GSC";
CM_ SG_ 2172674050 TCS_ManufacturerVal "TCS_ManufacturerInformationValue ##2G##ESC - TCS11 - TCS_MFRN";
CM_ SG_ 2172674050 TCS_TqIntrvntnVal "TCS_TorqueInterventionValue ##2G##ESC - TCS11 - TQI_TCS";
CM_ SG_ 2172674050 MSR_TqIntrvntnVal "MSR_TorqueInterventionValue ##2G##ESC - TCS11 - TQI_MSR";
CM_ SG_ 2172674050 TCS_SlwTqIntrvntnVal "TCS_SlowTorqueInterventionValue ##2G##ESC - TCS11 - TQI_SLW_TCS";
CM_ SG_ 2172674050 ESC_Sta "Status of ESC Function";
CM_ BO_ 2172674051 "[P] Periodic";
CM_ SG_ 2172674051 ESC_CylPrsrVal "ESC_CylinderPressureValue ##2G##ESC - ESP12 - CYL_PRES";
CM_ SG_ 2172674051 ESC_CylPrsrSta "ESC_CylinderPressureStatus ##2G##ESC - ESP12 - CYL_PRES_STAT";
CM_ SG_ 2172674051 ESC_CylPrsrDiagSta "ESC_CylinderPressureDiagnosisStatus ##2G##ESC - ESP12 - CYL_PRESS_DIAG";
CM_ SG_ 2172674051 ESC_CylPrsrFlagSta "ESC_CylinderPressureFlagStatus ##2G##ESC - ESP12 - CYL_PRES_FLAG";
CM_ SG_ 2172674051 ESC_VsmActvSta "ESC_VsmActiveStatus ##2G##ESC - VSM11 - CF_Esc_Act";
CM_ SG_ 2172674051 ESC_VsmDfctvSta "ESC_VsmDefectiveStatus ##2G##ESC - VSM11 - CF_Esc_Def";
CM_ SG_ 2172674051 ESC_VsmCtrlModSta "ESC_VsmControlModeStatus ##2G##ESC - VSM11 - CF_Esc_CtrMode";
CM_ SG_ 2172674051 ESC_StrTqReq "ESC_SteeringTorqueReqeust ##2G##ESC - TCS15 - CR_Esc_StrTqReq";
CM_ SG_ 2172674051 ESC_LongAccelOffstCalibPrmtr "Longitudinal Acceleration Offset Calibration Parameter";
CM_ SG_ 2172674051 ESC_IMURstStaAck "IMU Reset Status Acknowledge";
CM_ BO_ 2172674052 "[P] Periodic";
CM_ SG_ 2172674052 AVH_Sta "AVH_Status ##2G##ESC - ESP11 - AVH_STAT";
CM_ SG_ 2172674052 AVH_CluDis "AVH_ClusterDisplay ##2G##ESC - TCS15 - AVH_CLU";
CM_ SG_ 2172674052 LDM_Sta "LDM_Status ##2G##ESC - ESP11 - LDM_STAT";
CM_ SG_ 2172674052 AVH_AlrmReq "AVH_AlarmRequest ##2G##ESC - TCS15 - AVH_ALARM";
CM_ SG_ 2172674052 AVH_ActvStaLmpDis "AVH_ActiveStatusLampDisplay ##2G##ESC - TCS15 - AVH_I_LAMP";
CM_ SG_ 2172674052 AVH_LmpDis "AVH_LampDisplay ##2G##ESC - TCS15 - AVH_LAMP";
CM_ SG_ 2172674052 AWD_CrdnShftTqLimVal "AWD_CardanShaftTorqueLimitValue ##2G##ESC - ESP11 - 4WD_TQC_LIM";
CM_ SG_ 2172674052 EPB_ActvReq "EPB_ActiveRequest ##2G##ESC - ESP11 - REQ_EPB_ACT";
CM_ SG_ 2172674052 AWD_CltchDtyLimVal "AWD_ClutchDutyLimitValue ##2G##ESC - ESP11 - 4WD_CLU_LIM";
CM_ SG_ 2172674052 AWD_TransmsnTqLimModSta "AWD_TransmissionTorqueLimitModeStatus ##2G##ESC - ESP11 - 4WD_LIM_MODE";
CM_ SG_ 2172674052 AWD_RrWhlDtyLimReq "AWD_RearWheelDutyLimitRequest ##2G##ESC - ESP11 - 4WD_LIM_REQ";
CM_ SG_ 2172674052 EPB_StaReq "EPB_StatusRequest ##2G##ESC - ESP11 - REQ_EPB_STAT";
CM_ SG_ 2172674052 AWD_FastOpnCrdnShftCltchReq "AWD_FastOpenCardanShaftClutchRequest ##2G##ESC - ESP11 - 4WD_OPEN";
CM_ SG_ 2172674052 ECD_ActvSta "ECD_ActiveStatus ##2G##ESC - ESP11 - ECD_ACT";
CM_ BO_ 1458 "[TP] Transport Protocol";
CM_ SG_ 1458 GST_ATS_Byte0 "Diag Request for ATS";
CM_ SG_ 1458 GST_ATS_Byte2 "Diag Request for ATS";
CM_ SG_ 1458 GST_ATS_Byte3 "Diag Request for ATS";
CM_ SG_ 1458 GST_ATS_Byte4 "Diag Request for ATS";
CM_ SG_ 1458 GST_ATS_Byte5 "Diag Request for ATS";
CM_ SG_ 1458 GST_ATS_Byte6 "Diag Request for ATS";
CM_ SG_ 1458 GST_ATS_Byte7 "Diag Request for ATS";
CM_ SG_ 1458 GST_ATS_Byte1 "Diag Request for ATS";
CM_ BO_ 491 "[EC] On Event and On Change";
CM_ BO_ 966 "[PE] Periodic and On Event";
CM_ SG_ 966 RCM_Crc1Val "RCM_CyclicRedundancyCheck1Value";
CM_ SG_ 966 RCM_AlvCnt1Val "RCM_AliveCounter1Value";
CM_ SG_ 966 RCM_OptTyp "RCM (Roof Control Module) Option Type";
CM_ SG_ 966 RCM_SwStckDet "Sunroof Switch Stuck Detection";
CM_ SG_ 966 RCM_SwSta "OHCL Sunroof Switch Input Status";
CM_ BO_ 967 "[PE] Periodic and On Event";
CM_ SG_ 967 RCM_Crc2Val "RCM_CyclicRedundancyCheck2Value";
CM_ SG_ 967 RCM_AlvCnt2Val "RCM_AliveCounter2Value";
CM_ SG_ 967 RCM_GlsHallSnsrPlsCnt "Sunroof Glass Motor Hall Sensor Pulse Count";
CM_ SG_ 967 RCM_SunroofOpnSta "Sunroof Glass Open Status";
CM_ SG_ 967 RCM_GlsOpSta "Sunroof Glass Operation Status";
CM_ SG_ 967 RCM_GlsInitSta "Sunroof Glass Initialization Status";
CM_ SG_ 967 RCM_GlsAntPchSta "Sunroof Glass Anti Pinch Status";
CM_ SG_ 967 RCM_GlsMtrHiTempSta "Sunroof Glass Motor High Termperature Status";
CM_ SG_ 967 RCM_GlsMtRunTtlTime "Sunroof Glass Motor Run Total Time";
CM_ SG_ 967 RCM_GlsPosSta "Sunroof Glass Position Status";
CM_ SG_ 967 RCM_GlsFltVal "Sunroof Glass Fault Value";
CM_ SG_ 967 RCM_GlsFltSta "Sunroof Glass Fault Status";
CM_ BO_ 968 "[PE] Periodic and On Event";
CM_ SG_ 968 RCM_Crc3Val "RCM_CyclicRedundancyCheck3Value";
CM_ SG_ 968 RCM_AlvCnt3Val "RCM_AliveCounter3Value";
CM_ SG_ 968 RCM_BldHallSnsrPlsCnt "Sunroof Blind Motor Hall Sensor Pulse Count";
CM_ SG_ 968 RCM_BldOpSta "Sunroof Blind Operation Status";
CM_ SG_ 968 RCM_BldInitSta "Sunroof Blind Initialization Status";
CM_ SG_ 968 RCM_BldAntPchSta "Sunroof Blind Anti Pinch Status";
CM_ SG_ 968 RCM_BldMtrHiTempSta "Sunroof Blind Motor High Termperature Status";
CM_ SG_ 968 RCM_BldMtRunTtlTime "Sunroof Blind Motor Run Total Time";
CM_ SG_ 968 RCM_BldPosSta "Sunroof Blind Position Status";
CM_ SG_ 968 RCM_BldFltVal "Sunroof Blind Fault Value";
CM_ SG_ 968 RCM_BldFltSta "Sunroof Blind Fault Status";
CM_ BO_ 2332213249 "[P] Periodic";
CM_ SG_ 2332213249 VCU_Crc6Val "VCU_CyclicRedundancyCheck6Value";
CM_ SG_ 2332213249 VCU_AlvCnt6Val "VCU_AliveCounter6Value";
CM_ SG_ 2332213249 VCU_Required_ADASMapMsg "VCU_Required_ADASMapMessage";
CM_ SG_ 2332213249 VCU_SwVer "VCU_SWVersion";
CM_ SG_ 2332213249 VCU_PwrAutoOffInfo "VCU_PowerAutoOffInformation";
CM_ SG_ 2332213249 VCU_PwrAutoOffTimerSta "VCU_PowerAutoOffTimerStatus";
CM_ SG_ 2332213249 VCU_AutoShutOffTimerMin "VCU_AutoShutOffTimerMinute";
CM_ BO_ 2332213250 "[P] Periodic";
CM_ SG_ 2332213250 VCU_AutoShutOffTimerSec "VCU_AutoShutOffTimerSecond";
CM_ SG_ 2332213250 VCU_TireSizeWrnMsgSta "VCU_TireSizeWarningMessageStatus";
CM_ SG_ 2332213250 VCU_FrntTqDispPcVal "VCU_FrontTorqueDisplayPercentValue";
CM_ SG_ 2332213250 VCU_RearTqDispPcVal "VCU_RearTorqueDisplayPercentValue";
CM_ SG_ 2332213250 VCU_BstOpSta "VCU_Boost Operating Status";
CM_ SG_ 2332213250 VCU_BstTimerVal "VCU_Boost Timer Value";
CM_ SG_ 2332213250 VCU_BstWarnMsg "VCU_Boost Warning Message";
CM_ SG_ 2332213250 VCU_BstAvailSta "VCU Boost Available Status";
CM_ SG_ 2332213250 VCU_BstAplySta "VCU Boost Apply Status";
CM_ SG_ 2332213250 VCU_PwrAutoOffTimerReset "VCU_PowerAutoOffTimerReset";
CM_ SG_ 2332213250 VCU_AutoShutOffReq "VCU_AutoShutOffRequest";
CM_ BO_ 2332213251 "[P] Periodic";
CM_ BO_ 1308 "NM Message";
CM_ SG_ 1308 Destination_RLPSU "NM Source Node Identifier";
CM_ SG_ 1308 NMCommandCode_RLPSU "NM Control Bit Vector - Repeat Message Request";
CM_ SG_ 1308 NMSleepFlag_RLPSU "NM Control Bit Vector - NM Coordinator ID";
CM_ BO_ 1336 "NM Message";
CM_ SG_ 1336 Destination_DPSU "NM Source Node Identifier";
CM_ SG_ 1336 NMCommandCode_DPSU "NM Control Bit Vector - Repeat Message Request";
CM_ SG_ 1336 NMSleepFlag_DPSU "NM Control Bit Vector - NM Coordinator ID";
CM_ BO_ 1329 "NM Message";
CM_ SG_ 1329 Destination_APSU "NM Source Node Identifier";
CM_ SG_ 1329 NMCommandCode_APSU "NM Control Bit Vector - Repeat Message Request";
CM_ SG_ 1329 NMSleepFlag_APSU "NM Control Bit Vector - NM Coordinator ID";
CM_ BO_ 1345 "NM Message";
CM_ SG_ 1345 Destination_PSB "NM Source Node Identifier";
CM_ SG_ 1345 NMCommandCode_PSB "NM Control Bit Vector - Repeat Message Request";
CM_ SG_ 1345 NMSleepFlag_PSB "NM Control Bit Vector - NM Coordinator ID";
CM_ BO_ 1323 "NM Message";
CM_ SG_ 1323 Destination_SHVU_RR "NM Source Node Identifier";
CM_ SG_ 1323 NMCommandCode_SHVU_RR "NM Control Bit Vector - Repeat Message Request";
CM_ SG_ 1323 NMSleepFlag_SHVU_RR "NM Control Bit Vector - NM Coordinator ID";
CM_ BO_ 1313 "NM Message";
CM_ SG_ 1313 Destination_FCS "NM Source Node Identifier";
CM_ SG_ 1313 NMCommandCode_FCS "NM Control Bit Vector - Repeat Message Request";
CM_ SG_ 1313 NMSleepFlag_FCS "NM Control Bit Vector - NM Coordinator ID";
CM_ BO_ 1297 "NM Message";
CM_ SG_ 1297 Destination_EMCU "NM Source Node Identifier";
CM_ SG_ 1297 NMCommandCode_EMCU "NM Control Bit Vector - Repeat Message Request";
CM_ SG_ 1297 NMSleepFlag_EMCU "NM Control Bit Vector - NM Coordinator ID";
CM_ BO_ 1307 "NM Message";
CM_ SG_ 1307 Destination_SLB "NM Source Node Identifier";
CM_ SG_ 1307 NMCommandCode_SLB "NM Control Bit Vector - Repeat Message Request";
CM_ SG_ 1307 NMSleepFlag_SLB "NM Control Bit Vector - NM Coordinator ID";
CM_ BO_ 1341 "NM Message";
CM_ SG_ 1341 Destination_RCM "NM Source Node Identifier";
CM_ SG_ 1341 NMCommandCode_RCM "NM Control Bit Vector - Repeat Message Request";
CM_ SG_ 1341 NMSleepFlag_RCM "NM Control Bit Vector - NM Coordinator ID";
CM_ BO_ 1392 "NM Message";
CM_ SG_ 1392 Destination_CGW_CCU "NM Source Node Identifier";
CM_ SG_ 1392 NMCommandCode_CGW_CCU "NM Control Bit Vector - Repeat Message Request";
CM_ SG_ 1392 NMSleepFlag_CGW_CCU "NM Control Bit Vector - NM Coordinator ID";
CM_ BO_ 1360 "NM Message";
CM_ SG_ 1360 Destination_ATS "NM Source Node Identifier";
CM_ SG_ 1360 NMCommandCode_ATS "NM Control Bit Vector - Repeat Message Request";
CM_ SG_ 1360 NMSleepFlag_ATS "NM Control Bit Vector - NM Coordinator ID";
CM_ BO_ 1332 "NM Message";
CM_ SG_ 1332 Destination_RLHV "NM Source Node Identifier";
CM_ SG_ 1332 NMCommandCode_RLHV "NM Control Bit Vector - Repeat Message Request";
CM_ SG_ 1332 NMSleepFlag_RLHV "NM Control Bit Vector - NM Coordinator ID";
CM_ BO_ 1325 "NM Message";
CM_ SG_ 1325 Destination_PFSU "NM Source Node Identifier";
CM_ SG_ 1325 NMCommandCode_PFSU "NM Control Bit Vector - Repeat Message Request";
CM_ SG_ 1325 NMSleepFlag_PFSU "NM Control Bit Vector - NM Coordinator ID";
CM_ BO_ 1342 "NM Message";
CM_ SG_ 1342 Destination_SGU "NM Source Node Identifier";
CM_ SG_ 1342 NMCommandCode_SGU "NM Control Bit Vector - Repeat Message Request";
CM_ SG_ 1342 NMSleepFlag_SGU "NM Control Bit Vector - NM Coordinator ID";
CM_ BO_ 1348 "NM Message";
CM_ SG_ 1348 Destination_ALBCU "NM Source Node Identifier";
CM_ SG_ 1348 NMCommandCode_ALBCU "NM Control Bit Vector - Repeat Message Request";
CM_ SG_ 1348 NMSleepFlag_ALBCU "NM Control Bit Vector - NM Coordinator ID";
CM_ BO_ 1369 "NM Message";
CM_ SG_ 1369 Destination_DSAU "NM Source Node Identifier";
CM_ SG_ 1369 NMCommandCode_DSAU "NM Control Bit Vector - Repeat Message Request";
CM_ SG_ 1369 NMSleepFlag_DSAU "NM Control Bit Vector - NM Coordinator ID";
CM_ BO_ 1288 "NM Message";
CM_ SG_ 1288 Destination_SWRC "NM Source Node Identifier";
CM_ SG_ 1288 NMCommandCode_SWRC "NM Control Bit Vector - Repeat Message Request";
CM_ SG_ 1288 NMSleepFlag_SWRC "NM Control Bit Vector - NM Coordinator ID";
CM_ BO_ 1322 "NM Message";
CM_ SG_ 1322 Destination_SHVU_FR "NM Source Node Identifier";
CM_ SG_ 1322 NMCommandCode_SHVU_FR "NM Control Bit Vector - Repeat Message Request";
CM_ SG_ 1322 NMSleepFlag_SHVU_FR "NM Control Bit Vector - NM Coordinator ID";
CM_ BO_ 1350 "NM Message";
CM_ SG_ 1350 Destination_RCS "NM Source Node Identifier";
CM_ SG_ 1350 NMCommandCode_RCS "NM Control Bit Vector - Repeat Message Request";
CM_ SG_ 1350 NMSleepFlag_RCS "NM Control Bit Vector - NM Coordinator ID";
CM_ BO_ 1309 "NM Message";
CM_ SG_ 1309 Destination_RRPSU "NM Source Node Identifier";
CM_ SG_ 1309 NMCommandCode_RRPSU "NM Control Bit Vector - Repeat Message Request";
CM_ SG_ 1309 NMSleepFlag_RRPSU "NM Control Bit Vector - NM Coordinator ID";
CM_ BO_ 1352 "NM Message";
CM_ SG_ 1352 Destination_BLTN_CAM "NM Source Node Identifier";
CM_ SG_ 1352 NMCommandCode_BLTN_CAM "NM Control Bit Vector - Repeat Message Request";
CM_ SG_ 1352 NMSleepFlag_BLTN_CAM "NM Control Bit Vector - NM Coordinator ID";
CM_ BO_ 1287 "NM Message";
CM_ SG_ 1287 Destination_SCM "NM Source Node Identifier";
CM_ SG_ 1287 NMCommandCode_SCM "NM Control Bit Vector - Repeat Message Request";
CM_ SG_ 1287 NMSleepFlag_SCM "NM Control Bit Vector - NM Coordinator ID";
CM_ BO_ 1344 "NM Message";
CM_ SG_ 1344 Destination_DLBCU "NM Source Node Identifier";
CM_ SG_ 1344 NMCommandCode_DLBCU "NM Control Bit Vector - Repeat Message Request";
CM_ SG_ 1344 NMSleepFlag_DLBCU "NM Control Bit Vector - NM Coordinator ID";
CM_ BO_ 1364 "NM Message";
CM_ SG_ 1364 Destination_OHCL "NM Source Node Identifier";
CM_ SG_ 1364 NMCommandCode_OHCL "NM Control Bit Vector - Repeat Message Request";
CM_ SG_ 1364 NMSleepFlag_OHCL "NM Control Bit Vector - NM Coordinator ID";
CM_ BO_ 1311 "NM Message";
CM_ SG_ 1311 Destination_RWPC "NM Source Node Identifier";
CM_ SG_ 1311 NMCommandCode_RWPC "NM Control Bit Vector - Repeat Message Request";
CM_ SG_ 1311 NMSleepFlag_RWPC "NM Control Bit Vector - NM Coordinator ID";
CM_ BO_ 1333 "NM Message";
CM_ SG_ 1333 Destination_RRHV "NM Source Node Identifier";
CM_ SG_ 1333 NMCommandCode_RRHV "NM Control Bit Vector - Repeat Message Request";
CM_ SG_ 1333 NMSleepFlag_RRHV "NM Control Bit Vector - NM Coordinator ID";
CM_ BO_ 1310 "NM Message";
CM_ SG_ 1310 Destination_WPC "NM Source Node Identifier";
CM_ SG_ 1310 NMCommandCode_WPC "NM Control Bit Vector - Repeat Message Request";
CM_ SG_ 1310 NMSleepFlag_WPC "NM Control Bit Vector - NM Coordinator ID";
CM_ BO_ 1354 "NM Message";
CM_ SG_ 1354 Destination_HOD "NM Source Node Identifier";
CM_ SG_ 1354 NMCommandCode_HOD "NM Control Bit Vector - Repeat Message Request";
CM_ SG_ 1354 NMSleepFlag_HOD "NM Control Bit Vector - NM Coordinator ID";
CM_ BO_ 1363 "NM Message";
CM_ SG_ 1363 Destination_ASAU "NM Source Node Identifier";
CM_ SG_ 1363 NMCommandCode_ASAU "NM Control Bit Vector - Repeat Message Request";
CM_ SG_ 1363 NMSleepFlag_ASAU "NM Control Bit Vector - NM Coordinator ID";
BA_DEF_ BO_ "DiagState" ENUM "No","Yes" ;
BA_DEF_ BO_ "DiagResponse" ENUM "No","Yes" ;
BA_DEF_ BO_ "DiagRequest" ENUM "No","Yes" ;
BA_DEF_ BO_ "TpMessage" ENUM "No","Yes" ;
BA_DEF_ BO_ "UsrMsgIDSforwardDeviation" INT 0 100 ;
BA_DEF_ BO_ "UsrMsgIDSbackwardDeviation" INT 50 1000 ;
BA_DEF_ BO_ "GenMsgCycleTime" INT 0 2000 ;
BA_DEF_ BO_ "GenMsgStartDelayTime" INT 0 2000 ;
BA_DEF_ BO_ "GenMsgSendType" ENUM "Cyclic","NoMsgSendType" ;
BA_DEF_ BO_ "GenMsgCycleTimeFast" INT 0 500 ;
BA_DEF_ BO_ "GenMsgDelayTime" INT 0 20 ;
BA_DEF_ BO_ "GenMsgILSupport" ENUM "No","Yes" ;
BA_DEF_ BO_ "GenMsgNrOfRepetition" INT 0 3 ;
BA_DEF_ BO_ "NmMessage" ENUM "No","Yes" ;
BA_DEF_ BO_ "NWM-Botschaft" ENUM "No","Yes" ;
BA_DEF_ BO_ "TpTxIndex" INT 0 255 ;
BA_DEF_ BO_ "VFrameFormat" ENUM "StandardCAN","ExtendedCAN","reserved","reserved","reserved","reserved","reserved","reserved","reserved","reserved","reserved","reserved","reserved","reserved","StandardCAN_FD","ExtendedCAN_FD" ;
BA_DEF_ SG_ "UserSigValidity" ENUM "B+","ACC","IG","IG1","IG2","IG3","IG1 or IG2","IG1 or IG3","Undef" ;
BA_DEF_ SG_ "TimeoutValue" STRING ;
BA_DEF_ SG_ "UsrSigPurpose" ENUM "Undef","FN","DIAG","DIAG(Req)","DIAG(Res)","DIAG(Phy)","DEV","CCP(Req)","CCP(Res)","NM","TP" ;
BA_DEF_ SG_ "GenSigStartValue" INT 0 1215752192 ;
BA_DEF_ SG_ "NetworkRequest" ENUM "Yes","No" ;
BA_DEF_ SG_ "NetworkRequestHoldingTime" INT 0 65535 ;
BA_DEF_ SG_ "Description" STRING ;
BA_DEF_ SG_ "Version" STRING ;
BA_DEF_ SG_ "GenSigEnvVarType" ENUM "Int","Float","Undef" ;
BA_DEF_ SG_ "GenSigSendType" ENUM "Cyclic","OnWrite","OnWriteWithRepetition","OnChange","OnChangeWithRepetition","IfActive","IfActiveWithRepetition","NoSigSendType","OnChangeAndIfActive","OnChangeAndIfActiveWithRepetition" ;
BA_DEF_ SG_ "GwSigLatencyTime" INT 0 65536 ;
BA_DEF_ SG_ "GwSigMissingSourceType" ENUM "Undef","OldValue","DefaultValue","InitialValue" ;
BA_DEF_ SG_ "NWM-WakeupAllowed" ENUM "<n.a.>" ;
BA_DEF_ SG_ "RoutingFactor" INT 1 1215752192 ;
BA_DEF_REL_ BU_SG_REL_ "GenSigTimeoutTime" INT 0 7000 ;
BA_DEF_DEF_ "DiagState" "No" ;
BA_DEF_DEF_ "DiagResponse" "No" ;
BA_DEF_DEF_ "DiagRequest" "No" ;
BA_DEF_DEF_ "TpMessage" "No" ;
BA_DEF_DEF_ "UsrMsgIDSforwardDeviation" 10 ;
BA_DEF_DEF_ "UsrMsgIDSbackwardDeviation" 100 ;
BA_DEF_DEF_ "GenMsgCycleTime" 200 ;
BA_DEF_DEF_ "GenMsgStartDelayTime" 0 ;
BA_DEF_DEF_ "GenMsgSendType" "NoMsgSendType" ;
BA_DEF_DEF_ "GenMsgCycleTimeFast" 40 ;
BA_DEF_DEF_ "GenMsgDelayTime" 20 ;
BA_DEF_DEF_ "GenMsgILSupport" "Yes" ;
BA_DEF_DEF_ "GenMsgNrOfRepetition" 3 ;
BA_DEF_DEF_ "NmMessage" "No" ;
BA_DEF_DEF_ "NWM-Botschaft" "No" ;
BA_DEF_DEF_ "TpTxIndex" 0 ;
BA_DEF_DEF_ "VFrameFormat" "StandardCAN" ;
BA_DEF_DEF_ "UserSigValidity" "IG" ;
BA_DEF_DEF_ "TimeoutValue" "" ;
BA_DEF_DEF_ "UsrSigPurpose" "FN" ;
BA_DEF_DEF_ "GenSigStartValue" 0 ;
BA_DEF_DEF_ "NetworkRequest" "No" ;
BA_DEF_DEF_ "NetworkRequestHoldingTime" 0 ;
BA_DEF_DEF_ "Description" "" ;
BA_DEF_DEF_ "Version" "" ;
BA_DEF_DEF_ "GenSigEnvVarType" "Undef" ;
BA_DEF_DEF_ "GenSigSendType" "NoSigSendType" ;
BA_DEF_DEF_ "GwSigLatencyTime" 40 ;
BA_DEF_DEF_ "GwSigMissingSourceType" "Undef" ;
BA_DEF_DEF_ "NWM-WakeupAllowed" "<n.a.>" ;
BA_DEF_DEF_ "RoutingFactor" 1 ;
BA_DEF_DEF_REL_ "GenSigTimeoutTime" 500 ;
BA_ "GenMsgCycleTime" BO_ 2151682049 0;
BA_ "GenMsgDelayTime" BO_ 2151682049 10;
BA_ "VFrameFormat" BO_ 2151682049 1;
BA_ "Description" SG_ 2151682049 ACU_Crc2Val "The data area for CRC calculation is based on the data length (DLC) of the message DB.

The CRC shall be calculated over the entire data block (excluding the CRC bytes) including the user data, alive counter and Data ID

 

- CRC Polynomial (0x1021) , Initial Value : 0xFFFF, XOR value : 0x0000, Data ID : Message ID + 0xF800 

- The initial value is for CRC calculation and the message should be sent with the calculated result value. 

- The mathematical expression to 16 bit CRC polynomial is given here. G(x) = x16 + x12 + x5 + 1";
BA_ "GenSigSendType" SG_ 2151682049 ACU_Crc2Val 2;
BA_ "GenSigStartValue" SG_ 2151682049 ACU_Crc2Val 65535;
BA_ "UserSigValidity" SG_ 2151682049 ACU_Crc2Val 3;
BA_ "Version" SG_ 2151682049 ACU_Crc2Val "18.11.08";
BA_ "Description" SG_ 2151682049 ACU_AlvCnt2Val "For the first transmission request for a data element the counter shall be initialized with 0 and shall be incremented by 1 for every subsequent send request. 

When the counter reaches the maximum value(0xFF), then it shall restart with 0 for the next send request";
BA_ "GenSigSendType" SG_ 2151682049 ACU_AlvCnt2Val 2;
BA_ "UserSigValidity" SG_ 2151682049 ACU_AlvCnt2Val 3;
BA_ "Version" SG_ 2151682049 ACU_AlvCnt2Val "18.11.08";
BA_ "Description" SG_ 2151682049 ACU_CrshActvSta "Information regarding the crash. It indicates crash is active or inactive.";
BA_ "GenSigSendType" SG_ 2151682049 ACU_CrshActvSta 2;
BA_ "UserSigValidity" SG_ 2151682049 ACU_CrshActvSta 3;
BA_REL_ "GenSigTimeoutTime" BU_SG_REL_ APSU SG_ 2151682049 ACU_CrshActvSta 0;
BA_REL_ "GenSigTimeoutTime" BU_SG_REL_ RRPSU SG_ 2151682049 ACU_CrshActvSta 0;
BA_REL_ "GenSigTimeoutTime" BU_SG_REL_ RLPSU SG_ 2151682049 ACU_CrshActvSta 0;
BA_ "Version" SG_ 2151682049 ACU_CrshActvSta "17.12.00";
BA_ "Description" SG_ 2151682049 ACU_CrshInfo "1)When crash output is issued, this signal is transmitted as 0x2. 

2)When crash output is not issued and ACU meets MCB requirement of ESC.  this signal is transmitted as 0x1.



Just then If ACU receives feedback signal from ESC this signal is transmitted as 0x0.

If ACU do NOT receive feedback signal from ESC previous signal value is maintaned.



¡ØThis signal is transmmited until power-off";
BA_ "GenSigSendType" SG_ 2151682049 ACU_CrshInfo 2;
BA_ "UserSigValidity" SG_ 2151682049 ACU_CrshInfo 3;
BA_ "Version" SG_ 2151682049 ACU_CrshInfo "19.02.06";
BA_ "Description" SG_ 2151682049 ACU_CrshTyp "This signal indicates types of  crash. 

If a collision occurs continuously at same IGN cycle each crash type bit set to 1 according to the type of collision.



1)First byte Information 

xxxx xxxxB : No deployment Crash (Crash output signal not issued)

xxxx xxx1B : Front Crash (First stage only)

xxxx xx1xB : Front Crash (Full stage)

xxxx x1xxB : Side Crash (Driver side) 

xxxx 1xxxB : Side Crash (Passenger side)

xxx1 xxxxB : Rollover Crash (Restraints activation)

xx1x xxxxB : Rollover event information transmission (Restraints non-activation)

x1xx xxxxB : Side Crash Detection For Door Unlock (NON-SAB vehicle)

1xxx xxxxB : Rear Crash 

2)Second byte information 

xxxx xxx1B : Pre Crash (Pretentioner or Pretentioner + KAB)

other bits : RESERVED

¡Øx means that Not set as 1

¡ØFor example, If Driver side crash occurs and then Front crash-full stage occurs  continuously, Type of crash bit set to 0000 0000 0000 0110B";
BA_ "GenSigSendType" SG_ 2151682049 ACU_CrshTyp 2;
BA_ "UserSigValidity" SG_ 2151682049 ACU_CrshTyp 3;
BA_ "Version" SG_ 2151682049 ACU_CrshTyp "19.02.06";
BA_ "GenMsgSendType" BO_ 981 0;
BA_ "Description" SG_ 981 APSS_StExtFwdMvBtn "Á¶¼ö¼® Äí¼Ç ÀÍ½ºÅÙ¼Ç Æ÷¿öµå ¹öÆ°";
BA_ "GenSigSendType" SG_ 981 APSS_StExtFwdMvBtn 4;
BA_ "UserSigValidity" SG_ 981 APSS_StExtFwdMvBtn 0;
BA_ "NetworkRequest" SG_ 981 APSS_StExtFwdMvBtn 0;
BA_ "NetworkRequestHoldingTime" SG_ 981 APSS_StExtFwdMvBtn 5000;
BA_ "Version" SG_ 981 APSS_StExtFwdMvBtn "20.11.02";
BA_ "Description" SG_ 981 APSS_StSldFwdMvBtn "Á¶¼ö¼® ½½¶óÀÌµù Æ÷¿öµå ¹öÆ°";
BA_ "GenSigSendType" SG_ 981 APSS_StSldFwdMvBtn 4;
BA_ "UserSigValidity" SG_ 981 APSS_StSldFwdMvBtn 0;
BA_REL_ "GenSigTimeoutTime" BU_SG_REL_ CGW_CCU SG_ 981 APSS_StSldFwdMvBtn 1500;
BA_ "NetworkRequest" SG_ 981 APSS_StSldFwdMvBtn 0;
BA_ "NetworkRequestHoldingTime" SG_ 981 APSS_StSldFwdMvBtn 5000;
BA_ "Version" SG_ 981 APSS_StSldFwdMvBtn "20.03.01";
BA_ "Description" SG_ 981 APSS_StSldBwdMvBtn "Á¶¼ö¼® ½½¶óÀÌµù ¹é¿öµå ¹öÆ°";
BA_ "GenSigSendType" SG_ 981 APSS_StSldBwdMvBtn 4;
BA_ "UserSigValidity" SG_ 981 APSS_StSldBwdMvBtn 0;
BA_REL_ "GenSigTimeoutTime" BU_SG_REL_ CGW_CCU SG_ 981 APSS_StSldBwdMvBtn 1500;
BA_ "NetworkRequest" SG_ 981 APSS_StSldBwdMvBtn 0;
BA_ "NetworkRequestHoldingTime" SG_ 981 APSS_StSldBwdMvBtn 5000;
BA_ "Version" SG_ 981 APSS_StSldBwdMvBtn "20.03.01";
BA_ "Description" SG_ 981 APSS_StExtBwdMvBtn "Á¶¼ö¼® Äí¼Ç ÀÍ½ºÅÙ¼Ç ¹é¿öµå ¹öÆ°";
BA_ "GenSigSendType" SG_ 981 APSS_StExtBwdMvBtn 4;
BA_ "UserSigValidity" SG_ 981 APSS_StExtBwdMvBtn 0;
BA_ "NetworkRequest" SG_ 981 APSS_StExtBwdMvBtn 0;
BA_ "NetworkRequestHoldingTime" SG_ 981 APSS_StExtBwdMvBtn 5000;
BA_ "Version" SG_ 981 APSS_StExtBwdMvBtn "20.11.02";
BA_ "Description" SG_ 981 APSS_StRclFwdMvBtn "Á¶¼ö¼® ¸®Å¬¶óÀÌ´× Æ÷¿öµå ¹öÆ°";
BA_ "GenSigSendType" SG_ 981 APSS_StRclFwdMvBtn 4;
BA_ "UserSigValidity" SG_ 981 APSS_StRclFwdMvBtn 0;
BA_REL_ "GenSigTimeoutTime" BU_SG_REL_ CGW_CCU SG_ 981 APSS_StRclFwdMvBtn 1500;
BA_ "NetworkRequest" SG_ 981 APSS_StRclFwdMvBtn 0;
BA_ "NetworkRequestHoldingTime" SG_ 981 APSS_StRclFwdMvBtn 5000;
BA_ "Version" SG_ 981 APSS_StRclFwdMvBtn "20.03.01";
BA_ "Description" SG_ 981 APSS_StRclBwdMvBtn "Á¶¼ö¼® ¸®Å¬¶óÀÌ´× ¹é¿öµå ¹öÆ°";
BA_ "GenSigSendType" SG_ 981 APSS_StRclBwdMvBtn 4;
BA_ "UserSigValidity" SG_ 981 APSS_StRclBwdMvBtn 0;
BA_REL_ "GenSigTimeoutTime" BU_SG_REL_ CGW_CCU SG_ 981 APSS_StRclBwdMvBtn 1500;
BA_ "NetworkRequest" SG_ 981 APSS_StRclBwdMvBtn 0;
BA_ "NetworkRequestHoldingTime" SG_ 981 APSS_StRclBwdMvBtn 5000;
BA_ "Version" SG_ 981 APSS_StRclBwdMvBtn "20.03.01";
BA_ "Description" SG_ 981 APSS_StHgtUpMvBtn "Á¶¼ö¼® ÇÏÀÌÆ® ¾÷ ¹öÆ°";
BA_ "GenSigSendType" SG_ 981 APSS_StHgtUpMvBtn 4;
BA_ "UserSigValidity" SG_ 981 APSS_StHgtUpMvBtn 0;
BA_REL_ "GenSigTimeoutTime" BU_SG_REL_ CGW_CCU SG_ 981 APSS_StHgtUpMvBtn 1500;
BA_ "NetworkRequest" SG_ 981 APSS_StHgtUpMvBtn 0;
BA_ "NetworkRequestHoldingTime" SG_ 981 APSS_StHgtUpMvBtn 5000;
BA_ "Version" SG_ 981 APSS_StHgtUpMvBtn "20.03.01";
BA_ "Description" SG_ 981 APSS_StHgtDnMvBtn "Á¶¼ö¼® ÇÏÀÌÆ® ´Ù¿î ¹öÆ°";
BA_ "GenSigSendType" SG_ 981 APSS_StHgtDnMvBtn 4;
BA_ "UserSigValidity" SG_ 981 APSS_StHgtDnMvBtn 0;
BA_REL_ "GenSigTimeoutTime" BU_SG_REL_ CGW_CCU SG_ 981 APSS_StHgtDnMvBtn 1500;
BA_ "NetworkRequest" SG_ 981 APSS_StHgtDnMvBtn 0;
BA_ "NetworkRequestHoldingTime" SG_ 981 APSS_StHgtDnMvBtn 5000;
BA_ "Version" SG_ 981 APSS_StHgtDnMvBtn "20.03.01";
BA_ "Description" SG_ 981 APSS_StTltUpMvBtn "Á¶¼ö¼® Æ¿Æ® ¾÷ ¹öÆ°";
BA_ "GenSigSendType" SG_ 981 APSS_StTltUpMvBtn 4;
BA_ "UserSigValidity" SG_ 981 APSS_StTltUpMvBtn 0;
BA_REL_ "GenSigTimeoutTime" BU_SG_REL_ CGW_CCU SG_ 981 APSS_StTltUpMvBtn 1500;
BA_ "NetworkRequest" SG_ 981 APSS_StTltUpMvBtn 0;
BA_ "NetworkRequestHoldingTime" SG_ 981 APSS_StTltUpMvBtn 5000;
BA_ "Version" SG_ 981 APSS_StTltUpMvBtn "20.03.01";
BA_ "Description" SG_ 981 APSS_StTltDnMvBtn "Á¶¼ö¼® Æ¿Æ® ´Ù¿î ¹öÆ°";
BA_ "GenSigSendType" SG_ 981 APSS_StTltDnMvBtn 4;
BA_ "UserSigValidity" SG_ 981 APSS_StTltDnMvBtn 0;
BA_REL_ "GenSigTimeoutTime" BU_SG_REL_ CGW_CCU SG_ 981 APSS_StTltDnMvBtn 1500;
BA_ "NetworkRequest" SG_ 981 APSS_StTltDnMvBtn 0;
BA_ "NetworkRequestHoldingTime" SG_ 981 APSS_StTltDnMvBtn 5000;
BA_ "Version" SG_ 981 APSS_StTltDnMvBtn "20.03.01";
BA_ "Description" SG_ 981 APSS_StHRestUpMvBtn "µ¿½Â¼® Çìµå·¹½ºÆ® up ¹öÆ°";
BA_ "GenSigSendType" SG_ 981 APSS_StHRestUpMvBtn 4;
BA_ "UserSigValidity" SG_ 981 APSS_StHRestUpMvBtn 0;
BA_REL_ "GenSigTimeoutTime" BU_SG_REL_ CGW_CCU SG_ 981 APSS_StHRestUpMvBtn 1500;
BA_ "NetworkRequest" SG_ 981 APSS_StHRestUpMvBtn 0;
BA_ "NetworkRequestHoldingTime" SG_ 981 APSS_StHRestUpMvBtn 5000;
BA_ "Version" SG_ 981 APSS_StHRestUpMvBtn "20.03.01";
BA_ "Description" SG_ 981 APSS_StHRestDnMvBtn "µ¿½Â¼® Çìµå·¹½ºÆ® down ¹öÆ°";
BA_ "GenSigSendType" SG_ 981 APSS_StHRestDnMvBtn 4;
BA_ "UserSigValidity" SG_ 981 APSS_StHRestDnMvBtn 0;
BA_REL_ "GenSigTimeoutTime" BU_SG_REL_ CGW_CCU SG_ 981 APSS_StHRestDnMvBtn 1500;
BA_ "NetworkRequest" SG_ 981 APSS_StHRestDnMvBtn 0;
BA_ "NetworkRequestHoldingTime" SG_ 981 APSS_StHRestDnMvBtn 5000;
BA_ "Version" SG_ 981 APSS_StHRestDnMvBtn "20.03.01";
BA_ "Description" SG_ 981 APSS_StHRestFwdMvBtn "µ¿½Â¼® Çìµå·¹½ºÆ® fwd ¹öÆ°";
BA_ "GenSigSendType" SG_ 981 APSS_StHRestFwdMvBtn 4;
BA_ "UserSigValidity" SG_ 981 APSS_StHRestFwdMvBtn 0;
BA_REL_ "GenSigTimeoutTime" BU_SG_REL_ CGW_CCU SG_ 981 APSS_StHRestFwdMvBtn 1500;
BA_ "NetworkRequest" SG_ 981 APSS_StHRestFwdMvBtn 0;
BA_ "NetworkRequestHoldingTime" SG_ 981 APSS_StHRestFwdMvBtn 5000;
BA_ "Version" SG_ 981 APSS_StHRestFwdMvBtn "20.03.01";
BA_ "Description" SG_ 981 APSS_StHRestBwdMvBtn "µ¿½Â¼® Çìµå·¹½ºÆ® BWD ¹öÆ°";
BA_ "GenSigSendType" SG_ 981 APSS_StHRestBwdMvBtn 4;
BA_ "UserSigValidity" SG_ 981 APSS_StHRestBwdMvBtn 0;
BA_REL_ "GenSigTimeoutTime" BU_SG_REL_ CGW_CCU SG_ 981 APSS_StHRestBwdMvBtn 1500;
BA_ "NetworkRequest" SG_ 981 APSS_StHRestBwdMvBtn 0;
BA_ "NetworkRequestHoldingTime" SG_ 981 APSS_StHRestBwdMvBtn 5000;
BA_ "Version" SG_ 981 APSS_StHRestBwdMvBtn "20.03.01";
BA_ "Description" SG_ 981 APSS_StLegUpMvBtn "Á¶¼ö¼® ·¹±×·¹½ºÆ® ¾÷ ¹öÆ°";
BA_ "GenSigSendType" SG_ 981 APSS_StLegUpMvBtn 4;
BA_ "UserSigValidity" SG_ 981 APSS_StLegUpMvBtn 0;
BA_ "NetworkRequest" SG_ 981 APSS_StLegUpMvBtn 0;
BA_ "NetworkRequestHoldingTime" SG_ 981 APSS_StLegUpMvBtn 5000;
BA_ "Version" SG_ 981 APSS_StLegUpMvBtn "20.03.01";
BA_ "Description" SG_ 981 APSS_StLegDnMvBtn "Á¶¼ö¼® ·¹±×·¹½ºÆ® ´Ù¿î ¹öÆ°";
BA_ "GenSigSendType" SG_ 981 APSS_StLegDnMvBtn 4;
BA_ "UserSigValidity" SG_ 981 APSS_StLegDnMvBtn 0;
BA_ "NetworkRequest" SG_ 981 APSS_StLegDnMvBtn 0;
BA_ "NetworkRequestHoldingTime" SG_ 981 APSS_StLegDnMvBtn 5000;
BA_ "Version" SG_ 981 APSS_StLegDnMvBtn "20.03.01";
BA_ "Description" SG_ 981 APSS_StRlxModeBtn "Á¶¼ö¼® ¸±·º½º ¸ðµå ¹öÆ°";
BA_ "GenSigSendType" SG_ 981 APSS_StRlxModeBtn 4;
BA_ "UserSigValidity" SG_ 981 APSS_StRlxModeBtn 0;
BA_ "NetworkRequest" SG_ 981 APSS_StRlxModeBtn 0;
BA_ "NetworkRequestHoldingTime" SG_ 981 APSS_StRlxModeBtn 5000;
BA_ "Version" SG_ 981 APSS_StRlxModeBtn "20.03.01";
BA_ "Description" SG_ 981 APSS_StRlxReturnBtn "Á¶¼ö¼® ¸±·º½º ¸®ÅÏ ¹öÆ°";
BA_ "GenSigSendType" SG_ 981 APSS_StRlxReturnBtn 4;
BA_ "UserSigValidity" SG_ 981 APSS_StRlxReturnBtn 0;
BA_ "NetworkRequest" SG_ 981 APSS_StRlxReturnBtn 0;
BA_ "NetworkRequestHoldingTime" SG_ 981 APSS_StRlxReturnBtn 5000;
BA_ "Version" SG_ 981 APSS_StRlxReturnBtn "20.03.01";
BA_ "Description" SG_ 981 APSS_StRlxTltUpMvBtn "Á¶¼ö¼® ¸±·º½º Æ¿Æ® ¾÷ ¹öÆ°";
BA_ "GenSigSendType" SG_ 981 APSS_StRlxTltUpMvBtn 4;
BA_ "UserSigValidity" SG_ 981 APSS_StRlxTltUpMvBtn 0;
BA_ "NetworkRequest" SG_ 981 APSS_StRlxTltUpMvBtn 0;
BA_ "NetworkRequestHoldingTime" SG_ 981 APSS_StRlxTltUpMvBtn 5000;
BA_ "Version" SG_ 981 APSS_StRlxTltUpMvBtn "20.03.01";
BA_ "Description" SG_ 981 APSS_StRlxTltDnMvBtn "Á¶¼ö¼® ¸±·º½º Æ¿Æ® ´Ù¿î ¹öÆ°";
BA_ "GenSigSendType" SG_ 981 APSS_StRlxTltDnMvBtn 4;
BA_ "UserSigValidity" SG_ 981 APSS_StRlxTltDnMvBtn 0;
BA_ "NetworkRequest" SG_ 981 APSS_StRlxTltDnMvBtn 0;
BA_ "NetworkRequestHoldingTime" SG_ 981 APSS_StRlxTltDnMvBtn 5000;
BA_ "Version" SG_ 981 APSS_StRlxTltDnMvBtn "20.03.01";
BA_ "GenMsgCycleTime" BO_ 1951 0;
BA_ "GenMsgCycleTimeFast" BO_ 1951 0;
BA_ "GenMsgNrOfRepetition" BO_ 1951 0;
BA_ "DiagResponse" BO_ 1951 1;
BA_ "GenMsgILSupport" BO_ 1951 0;
BA_ "TpMessage" BO_ 1951 1;
BA_ "TpTxIndex" BO_ 1951 109;
BA_ "Description" SG_ 1951 APSU_GST_Byte0 "TP Index : 109";
BA_ "UsrSigPurpose" SG_ 1951 APSU_GST_Byte0 4;
BA_ "UserSigValidity" SG_ 1951 APSU_GST_Byte0 0;
BA_REL_ "GenSigTimeoutTime" BU_SG_REL_ CGW_CCU SG_ 1951 APSU_GST_Byte0 0;
BA_ "NetworkRequest" SG_ 1951 APSU_GST_Byte0 0;
BA_ "NetworkRequestHoldingTime" SG_ 1951 APSU_GST_Byte0 5000;
BA_ "Version" SG_ 1951 APSU_GST_Byte0 "21.02.04";
BA_ "Description" SG_ 1951 APSU_GST_Byte2 "TP Index : 109";
BA_ "UsrSigPurpose" SG_ 1951 APSU_GST_Byte2 4;
BA_ "UserSigValidity" SG_ 1951 APSU_GST_Byte2 0;
BA_REL_ "GenSigTimeoutTime" BU_SG_REL_ CGW_CCU SG_ 1951 APSU_GST_Byte2 0;
BA_ "NetworkRequest" SG_ 1951 APSU_GST_Byte2 0;
BA_ "NetworkRequestHoldingTime" SG_ 1951 APSU_GST_Byte2 5000;
BA_ "Version" SG_ 1951 APSU_GST_Byte2 "21.02.04";
BA_ "Description" SG_ 1951 APSU_GST_Byte3 "TP Index : 109";
BA_ "UsrSigPurpose" SG_ 1951 APSU_GST_Byte3 4;
BA_ "UserSigValidity" SG_ 1951 APSU_GST_Byte3 0;
BA_REL_ "GenSigTimeoutTime" BU_SG_REL_ CGW_CCU SG_ 1951 APSU_GST_Byte3 0;
BA_ "NetworkRequest" SG_ 1951 APSU_GST_Byte3 0;
BA_ "NetworkRequestHoldingTime" SG_ 1951 APSU_GST_Byte3 5000;
BA_ "Version" SG_ 1951 APSU_GST_Byte3 "21.02.04";
BA_ "Description" SG_ 1951 APSU_GST_Byte4 "TP Index : 109";
BA_ "UsrSigPurpose" SG_ 1951 APSU_GST_Byte4 4;
BA_ "UserSigValidity" SG_ 1951 APSU_GST_Byte4 0;
BA_REL_ "GenSigTimeoutTime" BU_SG_REL_ CGW_CCU SG_ 1951 APSU_GST_Byte4 0;
BA_ "NetworkRequest" SG_ 1951 APSU_GST_Byte4 0;
BA_ "NetworkRequestHoldingTime" SG_ 1951 APSU_GST_Byte4 5000;
BA_ "Version" SG_ 1951 APSU_GST_Byte4 "21.02.04";
BA_ "Description" SG_ 1951 APSU_GST_Byte5 "TP Index : 109";
BA_ "UsrSigPurpose" SG_ 1951 APSU_GST_Byte5 4;
BA_ "UserSigValidity" SG_ 1951 APSU_GST_Byte5 0;
BA_REL_ "GenSigTimeoutTime" BU_SG_REL_ CGW_CCU SG_ 1951 APSU_GST_Byte5 0;
BA_ "NetworkRequest" SG_ 1951 APSU_GST_Byte5 0;
BA_ "NetworkRequestHoldingTime" SG_ 1951 APSU_GST_Byte5 5000;
BA_ "Version" SG_ 1951 APSU_GST_Byte5 "21.02.04";
BA_ "Description" SG_ 1951 APSU_GST_Byte6 "TP Index : 109";
BA_ "UsrSigPurpose" SG_ 1951 APSU_GST_Byte6 4;
BA_ "UserSigValidity" SG_ 1951 APSU_GST_Byte6 0;
BA_REL_ "GenSigTimeoutTime" BU_SG_REL_ CGW_CCU SG_ 1951 APSU_GST_Byte6 0;
BA_ "NetworkRequest" SG_ 1951 APSU_GST_Byte6 0;
BA_ "NetworkRequestHoldingTime" SG_ 1951 APSU_GST_Byte6 5000;
BA_ "Version" SG_ 1951 APSU_GST_Byte6 "21.02.04";
BA_ "Description" SG_ 1951 APSU_GST_Byte7 "TP Index : 109";
BA_ "UsrSigPurpose" SG_ 1951 APSU_GST_Byte7 4;
BA_ "UserSigValidity" SG_ 1951 APSU_GST_Byte7 0;
BA_REL_ "GenSigTimeoutTime" BU_SG_REL_ CGW_CCU SG_ 1951 APSU_GST_Byte7 0;
BA_ "NetworkRequest" SG_ 1951 APSU_GST_Byte7 0;
BA_ "NetworkRequestHoldingTime" SG_ 1951 APSU_GST_Byte7 5000;
BA_ "Version" SG_ 1951 APSU_GST_Byte7 "21.02.04";
BA_ "Description" SG_ 1951 APSU_GST_Byte1 "TP Index : 109";
BA_ "UsrSigPurpose" SG_ 1951 APSU_GST_Byte1 4;
BA_ "UserSigValidity" SG_ 1951 APSU_GST_Byte1 0;
BA_REL_ "GenSigTimeoutTime" BU_SG_REL_ CGW_CCU SG_ 1951 APSU_GST_Byte1 0;
BA_ "NetworkRequest" SG_ 1951 APSU_GST_Byte1 0;
BA_ "NetworkRequestHoldingTime" SG_ 1951 APSU_GST_Byte1 5000;
BA_ "Version" SG_ 1951 APSU_GST_Byte1 "21.02.04";
BA_ "GenMsgCycleTime" BO_ 1466 0;
BA_ "GenMsgCycleTimeFast" BO_ 1466 0;
BA_ "GenMsgNrOfRepetition" BO_ 1466 0;
BA_ "DiagResponse" BO_ 1466 1;
BA_ "GenMsgILSupport" BO_ 1466 0;
BA_ "TpMessage" BO_ 1466 1;
BA_ "TpTxIndex" BO_ 1466 212;
BA_ "Description" SG_ 1466 ATS_GST_Byte0 "TP Index : 212";
BA_ "UsrSigPurpose" SG_ 1466 ATS_GST_Byte0 4;
BA_ "UserSigValidity" SG_ 1466 ATS_GST_Byte0 0;
BA_REL_ "GenSigTimeoutTime" BU_SG_REL_ CGW_CCU SG_ 1466 ATS_GST_Byte0 0;
BA_ "NetworkRequest" SG_ 1466 ATS_GST_Byte0 0;
BA_ "NetworkRequestHoldingTime" SG_ 1466 ATS_GST_Byte0 5000;
BA_ "Version" SG_ 1466 ATS_GST_Byte0 "21.02.04";
BA_ "Description" SG_ 1466 ATS_GST_Byte2 "TP Index : 212";
BA_ "UsrSigPurpose" SG_ 1466 ATS_GST_Byte2 4;
BA_ "UserSigValidity" SG_ 1466 ATS_GST_Byte2 0;
BA_REL_ "GenSigTimeoutTime" BU_SG_REL_ CGW_CCU SG_ 1466 ATS_GST_Byte2 0;
BA_ "NetworkRequest" SG_ 1466 ATS_GST_Byte2 0;
BA_ "NetworkRequestHoldingTime" SG_ 1466 ATS_GST_Byte2 5000;
BA_ "Version" SG_ 1466 ATS_GST_Byte2 "21.02.04";
BA_ "Description" SG_ 1466 ATS_GST_Byte3 "TP Index : 212";
BA_ "UsrSigPurpose" SG_ 1466 ATS_GST_Byte3 4;
BA_ "UserSigValidity" SG_ 1466 ATS_GST_Byte3 0;
BA_REL_ "GenSigTimeoutTime" BU_SG_REL_ CGW_CCU SG_ 1466 ATS_GST_Byte3 0;
BA_ "NetworkRequest" SG_ 1466 ATS_GST_Byte3 0;
BA_ "NetworkRequestHoldingTime" SG_ 1466 ATS_GST_Byte3 5000;
BA_ "Version" SG_ 1466 ATS_GST_Byte3 "21.02.04";
BA_ "Description" SG_ 1466 ATS_GST_Byte4 "TP Index : 212";
BA_ "UsrSigPurpose" SG_ 1466 ATS_GST_Byte4 4;
BA_ "UserSigValidity" SG_ 1466 ATS_GST_Byte4 0;
BA_REL_ "GenSigTimeoutTime" BU_SG_REL_ CGW_CCU SG_ 1466 ATS_GST_Byte4 0;
BA_ "NetworkRequest" SG_ 1466 ATS_GST_Byte4 0;
BA_ "NetworkRequestHoldingTime" SG_ 1466 ATS_GST_Byte4 5000;
BA_ "Version" SG_ 1466 ATS_GST_Byte4 "21.02.04";
BA_ "Description" SG_ 1466 ATS_GST_Byte5 "TP Index : 212";
BA_ "UsrSigPurpose" SG_ 1466 ATS_GST_Byte5 4;
BA_ "UserSigValidity" SG_ 1466 ATS_GST_Byte5 0;
BA_REL_ "GenSigTimeoutTime" BU_SG_REL_ CGW_CCU SG_ 1466 ATS_GST_Byte5 0;
BA_ "NetworkRequest" SG_ 1466 ATS_GST_Byte5 0;
BA_ "NetworkRequestHoldingTime" SG_ 1466 ATS_GST_Byte5 5000;
BA_ "Version" SG_ 1466 ATS_GST_Byte5 "21.02.04";
BA_ "Description" SG_ 1466 ATS_GST_Byte6 "TP Index : 212";
BA_ "UsrSigPurpose" SG_ 1466 ATS_GST_Byte6 4;
BA_ "UserSigValidity" SG_ 1466 ATS_GST_Byte6 0;
BA_REL_ "GenSigTimeoutTime" BU_SG_REL_ CGW_CCU SG_ 1466 ATS_GST_Byte6 0;
BA_ "NetworkRequest" SG_ 1466 ATS_GST_Byte6 0;
BA_ "NetworkRequestHoldingTime" SG_ 1466 ATS_GST_Byte6 5000;
BA_ "Version" SG_ 1466 ATS_GST_Byte6 "21.02.04";
BA_ "Description" SG_ 1466 ATS_GST_Byte7 "TP Index : 212";
BA_ "UsrSigPurpose" SG_ 1466 ATS_GST_Byte7 4;
BA_ "UserSigValidity" SG_ 1466 ATS_GST_Byte7 0;
BA_REL_ "GenSigTimeoutTime" BU_SG_REL_ CGW_CCU SG_ 1466 ATS_GST_Byte7 0;
BA_ "NetworkRequest" SG_ 1466 ATS_GST_Byte7 0;
BA_ "NetworkRequestHoldingTime" SG_ 1466 ATS_GST_Byte7 5000;
BA_ "Version" SG_ 1466 ATS_GST_Byte7 "21.02.04";
BA_ "Description" SG_ 1466 ATS_GST_Byte1 "TP Index : 212";
BA_ "UsrSigPurpose" SG_ 1466 ATS_GST_Byte1 4;
BA_ "UserSigValidity" SG_ 1466 ATS_GST_Byte1 0;
BA_REL_ "GenSigTimeoutTime" BU_SG_REL_ CGW_CCU SG_ 1466 ATS_GST_Byte1 0;
BA_ "NetworkRequest" SG_ 1466 ATS_GST_Byte1 0;
BA_ "NetworkRequestHoldingTime" SG_ 1466 ATS_GST_Byte1 5000;
BA_ "Version" SG_ 1466 ATS_GST_Byte1 "21.02.04";
BA_ "GenMsgSendType" BO_ 963 0;
BA_ "Description" SG_ 963 BCM_Crc16Val "The data area for CRC calculation is based on the data length (DLC) of the message DB.

The CRC shall be calculated over the entire data block (excluding the CRC bytes) including the user data, alive counter and Data ID 

 

- CRC Polynomial (0x1D) , Initial Value : 0x00, XOR value : 0xFF, Data ID Mode : Both, Data ID : Message ID + 0xF800 

- The initial value is for CRC calculation and the message should be sent with the calculated result value. 

The mathematical expression to 8 bit CRC polynomial is given here. G(x) = x8 + x4 + x3 + x2 + 1";
BA_ "GenSigSendType" SG_ 963 BCM_Crc16Val 4;
BA_ "GenSigStartValue" SG_ 963 BCM_Crc16Val 255;
BA_ "UserSigValidity" SG_ 963 BCM_Crc16Val 0;
BA_ "Version" SG_ 963 BCM_Crc16Val "18.11.08";
BA_ "Description" SG_ 963 BCM_AlvCnt16Val "For the first transmission request for a data element the counter shall be initialized with 0 and shall be incremented by 1

for every subsequent send request. When the counter reaches the maximum value(0xE), then it shall restart with 0 for the next send request";
BA_ "GenSigSendType" SG_ 963 BCM_AlvCnt16Val 4;
BA_ "UserSigValidity" SG_ 963 BCM_AlvCnt16Val 0;
BA_ "Version" SG_ 963 BCM_AlvCnt16Val "18.11.08";
BA_ "Description" SG_ 963 IBU_SWVerMajor1 "Indicate the IBU software version as follows:

- The software version is displayed in three digits.

- The Major and Minor digits are separated by '.'

- Signal values are transmitted to ASCII codes.



¡Ø Example

C_IBU_SWVerMajor1 : 0x41 (HEX) -> ASCII CODE : 'A' 

C_IBU_SWVerMinor1 : 0x30 (HEX) -> ASCII CODE : '0'

C_IBU_SWVerMinor2 : 0x33 (HEX) -> ASCII CODE : '3'

=> IBU S/W Ver is displayed 'A.03'";
BA_ "GenSigSendType" SG_ 963 IBU_SWVerMajor1 4;
BA_ "UserSigValidity" SG_ 963 IBU_SWVerMajor1 0;
BA_ "Version" SG_ 963 IBU_SWVerMajor1 "20.12.04";
BA_ "Description" SG_ 963 IBU_SWVerMinor1 "Indicate the IBU software version as follows:

- The software version is displayed in three digits.

- The Major and Minor digits are separated by '.'

- Signal values are transmitted to ASCII codes.



¡Ø Example

C_IBU_SWVerMajor1 : 0x41 (HEX) -> ASCII CODE : 'A' 

C_IBU_SWVerMinor1 : 0x30 (HEX) -> ASCII CODE : '0'

C_IBU_SWVerMinor2 : 0x33 (HEX) -> ASCII CODE : '3'

=> IBU S/W Ver is displayed 'A.03'";
BA_ "GenSigSendType" SG_ 963 IBU_SWVerMinor1 4;
BA_ "UserSigValidity" SG_ 963 IBU_SWVerMinor1 0;
BA_ "Version" SG_ 963 IBU_SWVerMinor1 "18.10.02";
BA_ "Description" SG_ 963 IBU_SWVerMinor2 "Indicate the IBU software version as follows:

- The software version is displayed in three digits.

- The Major and Minor digits are separated by '.'

- Signal values are transmitted to ASCII codes.



¡Ø Example

C_IBU_SWVerMajor1 : 0x41 (HEX) -> ASCII CODE : 'A' 

C_IBU_SWVerMinor1 : 0x30 (HEX) -> ASCII CODE : '0'

C_IBU_SWVerMinor2 : 0x33 (HEX) -> ASCII CODE : '3'

=> IBU S/W Ver is displayed 'A.03'";
BA_ "GenSigSendType" SG_ 963 IBU_SWVerMinor2 4;
BA_ "UserSigValidity" SG_ 963 IBU_SWVerMinor2 0;
BA_ "Version" SG_ 963 IBU_SWVerMinor2 "18.10.02";
BA_ "Description" SG_ 963 ECW_Fault "ECW LIN to CAN Signal 

- LIN Signal Name : FAULT_ECW";
BA_ "GenSigSendType" SG_ 963 ECW_Fault 4;
BA_ "UserSigValidity" SG_ 963 ECW_Fault 0;
BA_ "NetworkRequest" SG_ 963 ECW_Fault 0;
BA_ "NetworkRequestHoldingTime" SG_ 963 ECW_Fault 5000;
BA_ "Version" SG_ 963 ECW_Fault "20.05.02";
BA_ "Description" SG_ 963 ECW_FaultActv "ECW LIN to CAN Signal

- LIN Signal Name : FAULT_ACTIVE";
BA_ "GenSigSendType" SG_ 963 ECW_FaultActv 4;
BA_ "GenSigStartValue" SG_ 963 ECW_FaultActv 1;
BA_ "UserSigValidity" SG_ 963 ECW_FaultActv 0;
BA_ "NetworkRequest" SG_ 963 ECW_FaultActv 0;
BA_ "NetworkRequestHoldingTime" SG_ 963 ECW_FaultActv 5000;
BA_ "Version" SG_ 963 ECW_FaultActv "20.05.02";
BA_ "Description" SG_ 963 ECW_HiVolt "ECW LIN to CAN Signal

- LIN Signal Name : HIGH_VOLT_ECW";
BA_ "GenSigSendType" SG_ 963 ECW_HiVolt 4;
BA_ "UserSigValidity" SG_ 963 ECW_HiVolt 0;
BA_ "NetworkRequest" SG_ 963 ECW_HiVolt 0;
BA_ "NetworkRequestHoldingTime" SG_ 963 ECW_HiVolt 5000;
BA_ "Version" SG_ 963 ECW_HiVolt "20.05.02";
BA_ "Description" SG_ 963 ECW_HiVoltActv "ECW LIN to CAN Signal

- LIN Signal Name : HIGH_VOLT_ACTIVE";
BA_ "GenSigSendType" SG_ 963 ECW_HiVoltActv 4;
BA_ "GenSigStartValue" SG_ 963 ECW_HiVoltActv 1;
BA_ "UserSigValidity" SG_ 963 ECW_HiVoltActv 0;
BA_ "NetworkRequest" SG_ 963 ECW_HiVoltActv 0;
BA_ "NetworkRequestHoldingTime" SG_ 963 ECW_HiVoltActv 5000;
BA_ "Version" SG_ 963 ECW_HiVoltActv "20.05.02";
BA_ "Description" SG_ 963 ECW_LoVolt "ECW LIN to CAN Signal

- LIN Signal Name : LOW_VOLT_ECW";
BA_ "GenSigSendType" SG_ 963 ECW_LoVolt 4;
BA_ "UserSigValidity" SG_ 963 ECW_LoVolt 0;
BA_ "NetworkRequest" SG_ 963 ECW_LoVolt 0;
BA_ "NetworkRequestHoldingTime" SG_ 963 ECW_LoVolt 5000;
BA_ "Version" SG_ 963 ECW_LoVolt "20.05.02";
BA_ "Description" SG_ 963 ECW_LoVoltActv "ECW LIN to CAN Signal

- LIN Signal Name : LOW_VOLT_ACTIVE";
BA_ "GenSigSendType" SG_ 963 ECW_LoVoltActv 4;
BA_ "GenSigStartValue" SG_ 963 ECW_LoVoltActv 1;
BA_ "UserSigValidity" SG_ 963 ECW_LoVoltActv 0;
BA_ "NetworkRequest" SG_ 963 ECW_LoVoltActv 0;
BA_ "NetworkRequestHoldingTime" SG_ 963 ECW_LoVoltActv 5000;
BA_ "Version" SG_ 963 ECW_LoVoltActv "20.05.02";
BA_ "Description" SG_ 963 ECW_Overload "ECW LIN to CAN Signal

- LIN Signal Name : OVERLOAD_ECW";
BA_ "GenSigSendType" SG_ 963 ECW_Overload 4;
BA_ "UserSigValidity" SG_ 963 ECW_Overload 0;
BA_ "NetworkRequest" SG_ 963 ECW_Overload 0;
BA_ "NetworkRequestHoldingTime" SG_ 963 ECW_Overload 5000;
BA_ "Version" SG_ 963 ECW_Overload "20.05.02";
BA_ "Description" SG_ 963 ECW_OverloadActv "ECW LIN to CAN Signal

- LIN Signal Name : OVERLOAD_ACTIVE";
BA_ "GenSigSendType" SG_ 963 ECW_OverloadActv 4;
BA_ "GenSigStartValue" SG_ 963 ECW_OverloadActv 1;
BA_ "UserSigValidity" SG_ 963 ECW_OverloadActv 0;
BA_ "NetworkRequest" SG_ 963 ECW_OverloadActv 0;
BA_ "NetworkRequestHoldingTime" SG_ 963 ECW_OverloadActv 5000;
BA_ "Version" SG_ 963 ECW_OverloadActv "20.05.02";
BA_ "Description" SG_ 963 ECW_CommErr "ECW LIN to CAN Signal

- LIN Signal Name : ERR_COMM_ECW";
BA_ "GenSigSendType" SG_ 963 ECW_CommErr 4;
BA_ "UserSigValidity" SG_ 963 ECW_CommErr 0;
BA_ "NetworkRequest" SG_ 963 ECW_CommErr 0;
BA_ "NetworkRequestHoldingTime" SG_ 963 ECW_CommErr 5000;
BA_ "Version" SG_ 963 ECW_CommErr "20.05.02";
BA_ "Description" SG_ 963 SunRoof_RearBlindOprSta "Rear BlindPanel information (LIN to CAN signal)

- LIN Singal name : SunRoof_RearBlindOprSta";
BA_ "GenSigSendType" SG_ 963 SunRoof_RearBlindOprSta 4;
BA_ "GenSigStartValue" SG_ 963 SunRoof_RearBlindOprSta 15;
BA_ "UserSigValidity" SG_ 963 SunRoof_RearBlindOprSta 0;
BA_REL_ "GenSigTimeoutTime" BU_SG_REL_ ATS SG_ 963 SunRoof_RearBlindOprSta 1500;
BA_ "Version" SG_ 963 SunRoof_RearBlindOprSta "20.07.00";
BA_ "GenMsgSendType" BO_ 983 0;
BA_ "Description" SG_ 983 BLTN_CAM_SWVerMajor "Indicate the Built-in Cam software version as follows:

- The software version is displayed in seven digits.

- The Major, Minor1, Minor2, Minor3 digits are separated by '.'

- Major Signal value is transmitted to ASCII codes.

- Minor1/Minor2/Minor2 Signal values are transmitted to unsigned integer(2digit).

- Major version has 2 charactors, the first charactors must be '0'



¡Ø Example

BLTN_CAM_SwVerMajor : 0x41 (HEX) -> ASCII CODE : 'A' 

BLTN_CAM_SwVerMinor1 : 0x01 (HEX) -> unsigned int : 01

BLTN_CAM_SwVerMinor2 : 0x0A (HEX) -> unsigned int : 10

BLTN_CAM_SwVerMinor3 : 0x47 (HEX) -> unsigned int : 71

=> BLTN_CAM S/W Ver is displayed '0A.01.10.71'";
BA_ "GenSigSendType" SG_ 983 BLTN_CAM_SWVerMajor 4;
BA_ "UserSigValidity" SG_ 983 BLTN_CAM_SWVerMajor 0;
BA_REL_ "GenSigTimeoutTime" BU_SG_REL_ CGW_CCU SG_ 983 BLTN_CAM_SWVerMajor 1500;
BA_ "RoutingFactor" SG_ 983 BLTN_CAM_SWVerMajor 0;
BA_ "Version" SG_ 983 BLTN_CAM_SWVerMajor "21.07.05";
BA_ "Description" SG_ 983 BLTN_CAM_SWVerMinor2 "Indicate the Built-in Cam software version as follows:

- The software version is displayed in seven digits.

- The Major, Minor1, Minor2, Minor3 digits are separated by '.'

- Major Signal value is transmitted to ASCII codes.

- Minor1/Minor2/Minor2 Signal values are transmitted to unsigned integer(2digit).

- Major version has 2 charactors, the first charactors must be '0'



¡Ø Example

BLTN_CAM_SwVerMajor : 0x41 (HEX) -> ASCII CODE : 'A' 

BLTN_CAM_SwVerMinor1 : 0x01 (HEX) -> unsigned int : 01

BLTN_CAM_SwVerMinor2 : 0x0A (HEX) -> unsigned int : 10

BLTN_CAM_SwVerMinor3 : 0x47 (HEX) -> unsigned int : 71

=> BLTN_CAM S/W Ver is displayed '0A.01.10.71'";
BA_ "GenSigSendType" SG_ 983 BLTN_CAM_SWVerMinor2 4;
BA_ "UserSigValidity" SG_ 983 BLTN_CAM_SWVerMinor2 0;
BA_REL_ "GenSigTimeoutTime" BU_SG_REL_ CGW_CCU SG_ 983 BLTN_CAM_SWVerMinor2 1500;
BA_ "RoutingFactor" SG_ 983 BLTN_CAM_SWVerMinor2 0;
BA_ "Version" SG_ 983 BLTN_CAM_SWVerMinor2 "21.07.05";
BA_ "Description" SG_ 983 BLTN_CAM_SWVerMinor3 "Indicate the Built-in Cam software version as follows:

- The software version is displayed in seven digits.

- The Major, Minor1, Minor2, Minor3 digits are separated by '.'

- Major Signal value is transmitted to ASCII codes.

- Minor1/Minor2/Minor2 Signal values are transmitted to unsigned integer(2digit).

- Major version has 2 charactors, the first charactors must be '0'



¡Ø Example

BLTN_CAM_SwVerMajor : 0x41 (HEX) -> ASCII CODE : 'A' 

BLTN_CAM_SwVerMinor1 : 0x01 (HEX) -> unsigned int : 01

BLTN_CAM_SwVerMinor2 : 0x0A (HEX) -> unsigned int : 10

BLTN_CAM_SwVerMinor3 : 0x47 (HEX) -> unsigned int : 71

=> BLTN_CAM S/W Ver is displayed '0A.01.10.71'";
BA_ "GenSigSendType" SG_ 983 BLTN_CAM_SWVerMinor3 4;
BA_ "UserSigValidity" SG_ 983 BLTN_CAM_SWVerMinor3 0;
BA_REL_ "GenSigTimeoutTime" BU_SG_REL_ CGW_CCU SG_ 983 BLTN_CAM_SWVerMinor3 1500;
BA_ "RoutingFactor" SG_ 983 BLTN_CAM_SWVerMinor3 0;
BA_ "Version" SG_ 983 BLTN_CAM_SWVerMinor3 "21.07.05";
BA_ "Description" SG_ 983 BLTN_CAM_SWVerMinor1 "Indicate the Built-in Cam software version as follows:

- The software version is displayed in seven digits.

- The Major, Minor1, Minor2, Minor3 digits are separated by '.'

- Major Signal value is transmitted to ASCII codes.

- Minor1/Minor2/Minor2 Signal values are transmitted to unsigned integer(2digit).

- Major version has 2 charactors, the first charactors must be '0'



¡Ø Example

BLTN_CAM_SwVerMajor : 0x41 (HEX) -> ASCII CODE : 'A' 

BLTN_CAM_SwVerMinor1 : 0x01 (HEX) -> unsigned int : 01

BLTN_CAM_SwVerMinor2 : 0x0A (HEX) -> unsigned int : 10

BLTN_CAM_SwVerMinor3 : 0x47 (HEX) -> unsigned int : 71

=> BLTN_CAM S/W Ver is displayed '0A.01.10.71'";
BA_ "GenSigSendType" SG_ 983 BLTN_CAM_SWVerMinor1 4;
BA_ "UserSigValidity" SG_ 983 BLTN_CAM_SWVerMinor1 0;
BA_REL_ "GenSigTimeoutTime" BU_SG_REL_ CGW_CCU SG_ 983 BLTN_CAM_SWVerMinor1 1500;
BA_ "RoutingFactor" SG_ 983 BLTN_CAM_SWVerMinor1 0;
BA_ "Version" SG_ 983 BLTN_CAM_SWVerMinor1 "21.07.05";
BA_ "GenMsgSendType" BO_ 2328014849 0;
BA_ "GenMsgCycleTimeFast" BO_ 2328014849 0;
BA_ "GenMsgNrOfRepetition" BO_ 2328014849 0;
BA_ "VFrameFormat" BO_ 2328014849 1;
BA_ "Description" SG_ 2328014849 DATC_Crc17Val "The data area for CRC calculation is based on the data length (DLC) of the message DB.

The CRC shall be calculated over the entire data block (excluding the CRC bytes) including the user data, alive counter and Data ID

 

- CRC Polynomial (0x1021) , Initial Value : 0xFFFF, XOR value : 0x0000, Data ID : Message ID + 0xF800 

- The initial value is for CRC calculation and the message should be sent with the calculated result value. 

- The mathematical expression to 16 bit CRC polynomial is given here. G(x) = x16 + x12 + x5 + 1";
BA_ "GenSigStartValue" SG_ 2328014849 DATC_Crc17Val 65535;
BA_ "UserSigValidity" SG_ 2328014849 DATC_Crc17Val 3;
BA_ "Version" SG_ 2328014849 DATC_Crc17Val "19.08.05";
BA_ "Description" SG_ 2328014849 DATC_AlvCnt17Val "For the first transmission request for a data element the counter shall be initialized with 0 and shall be incremented by 1 for every subsequent send request. 

When the counter reaches the maximum value(0xFF), then it shall restart with 0 for the next send request";
BA_ "UserSigValidity" SG_ 2328014849 DATC_AlvCnt17Val 3;
BA_ "Version" SG_ 2328014849 DATC_AlvCnt17Val "19.08.05";
BA_ "UserSigValidity" SG_ 2328014849 DATC_FrontPwmIsVolt 7;
BA_ "Version" SG_ 2328014849 DATC_FrontPwmIsVolt "19.08.05";
BA_ "UserSigValidity" SG_ 2328014849 DATC_FrontBlwDuty 7;
BA_ "Version" SG_ 2328014849 DATC_FrontBlwDuty "19.08.05";
BA_ "UserSigValidity" SG_ 2328014849 DATC_FrontBlwDiagStat 7;
BA_ "Version" SG_ 2328014849 DATC_FrontBlwDiagStat "19.08.05";
BA_ "Description" SG_ 2328014849 DATC_BlwrLvl_Ps "This signal indicates step of Front Passenger side blower operation .";
BA_ "UserSigValidity" SG_ 2328014849 DATC_BlwrLvl_Ps 7;
BA_ "Version" SG_ 2328014849 DATC_BlwrLvl_Ps "20.02.04";
BA_ "Description" SG_ 2328014849 DATC_BlwrLvl_Rr "This signal indicates step of Rear blower operation .";
BA_ "UserSigValidity" SG_ 2328014849 DATC_BlwrLvl_Rr 7;
BA_ "Version" SG_ 2328014849 DATC_BlwrLvl_Rr "20.02.03";
BA_ "Description" SG_ 2328014849 DATC_SwlSta "This signal is generated by one of the following 5 self-diagnostic result of micro-controller of DATC.

1) ¡°Lamp ON¡± status as a self-status diagnostic result of DATC

2) ¡°Lamp OFF¡± status as a self-status diagnostic result of DATC

3) ¡°Lamp flashing with 1hz frequency / 50% duty ratio¡± as a self-status result diagnostic result of DATC

4) ¡°Lamp Circuit Failure¡± as a self-diagnostic result of DATC circuit 

5) ¡°No Valid ACU message¡± as ACU_01_100ms message check result by DATC";
BA_ "UserSigValidity" SG_ 2328014849 DATC_SwlSta 3;
BA_ "Version" SG_ 2328014849 DATC_SwlSta "20.05.00";
BA_ "Description" SG_ 2328014849 DATC_FnDstSnsrVal "This signal indicate fine dust sensor value.

It is valid from 0 to 500.";
BA_ "UserSigValidity" SG_ 2328014849 DATC_FnDstSnsrVal 7;
BA_ "Version" SG_ 2328014849 DATC_FnDstSnsrVal "20.09.00";
BA_ "GenMsgSendType" BO_ 2328014850 0;
BA_ "GenMsgCycleTimeFast" BO_ 2328014850 0;
BA_ "GenMsgNrOfRepetition" BO_ 2328014850 0;
BA_ "VFrameFormat" BO_ 2328014850 1;
BA_ "Description" SG_ 2328014850 DATC_FnDstStp "This signal indicate Fine Dust Step for CCS";
BA_ "UserSigValidity" SG_ 2328014850 DATC_FnDstStp 7;
BA_REL_ "GenSigTimeoutTime" BU_SG_REL_ ATS SG_ 2328014850 DATC_FnDstStp 1500;
BA_ "Version" SG_ 2328014850 DATC_FnDstStp "20.07.10";
BA_ "UserSigValidity" SG_ 2328014850 DATC_OutTempOpt 7;
BA_ "Version" SG_ 2328014850 DATC_OutTempOpt "21.01.02";
BA_ "Description" SG_ 2328014850 DATC_OutTempDispC "This signal indicates Outside temperature (¡É).

(Use for display only)";
BA_ "UserSigValidity" SG_ 2328014850 DATC_OutTempDispC 7;
BA_REL_ "GenSigTimeoutTime" BU_SG_REL_ ATS SG_ 2328014850 DATC_OutTempDispC 1500;
BA_ "Version" SG_ 2328014850 DATC_OutTempDispC "20.10.00";
BA_ "Description" SG_ 2328014850 DATC_OutTempDispF "This signal indicates Outside Temperature (¢µ)

(Use for display only)";
BA_ "UserSigValidity" SG_ 2328014850 DATC_OutTempDispF 7;
BA_REL_ "GenSigTimeoutTime" BU_SG_REL_ ATS SG_ 2328014850 DATC_OutTempDispF 1500;
BA_ "Version" SG_ 2328014850 DATC_OutTempDispF "20.10.00";
BA_ "Description" SG_ 2328014850 DATC_EngOffReqWaterTemp "Cooling water temperature conditions to request the engine off";
BA_ "UserSigValidity" SG_ 2328014850 DATC_EngOffReqWaterTemp 7;
BA_ "Version" SG_ 2328014850 DATC_EngOffReqWaterTemp "21.07.05";
BA_ "Description" SG_ 2328014850 DATC_HDPDfg_Sta "This signal indicate AutoDefog status information for HDP.";
BA_ "TimeoutValue" SG_ 2328014850 DATC_HDPDfg_Sta "0x1";
BA_ "UserSigValidity" SG_ 2328014850 DATC_HDPDfg_Sta 3;
BA_ "Version" SG_ 2328014850 DATC_HDPDfg_Sta "21.08.02";
BA_ "Description" SG_ 2328014850 DATC_HDPSpptSWVer "This signal indicate the part to be matched on the specification version applied between DATC and ADAS_DRV (HDP control unit) for observe the regulation about autonomous driving.";
BA_ "TimeoutValue" SG_ 2328014850 DATC_HDPSpptSWVer "0x1F";
BA_ "UserSigValidity" SG_ 2328014850 DATC_HDPSpptSWVer 7;
BA_ "Version" SG_ 2328014850 DATC_HDPSpptSWVer "21.11.00";
BA_ "Description" SG_ 2328014850 DATC_HDPHumidity_Sta "This signal indicate Humidity status information for HDP.";
BA_ "UserSigValidity" SG_ 2328014850 DATC_HDPHumidity_Sta 3;
BA_ "Version" SG_ 2328014850 DATC_HDPHumidity_Sta "20.05.02";
BA_ "Description" SG_ 2328014850 DATC_FnDstStp_Detail "This signal indicate Detail State of Fine Dust Step for ATS.";
BA_ "UserSigValidity" SG_ 2328014850 DATC_FnDstStp_Detail 7;
BA_REL_ "GenSigTimeoutTime" BU_SG_REL_ ATS SG_ 2328014850 DATC_FnDstStp_Detail 1500;
BA_ "Version" SG_ 2328014850 DATC_FnDstStp_Detail "20.09.00";
BA_ "GenMsgSendType" BO_ 2328014851 0;
BA_ "GenMsgCycleTimeFast" BO_ 2328014851 0;
BA_ "GenMsgNrOfRepetition" BO_ 2328014851 0;
BA_ "VFrameFormat" BO_ 2328014851 1;
BA_ "GenMsgSendType" BO_ 2172674049 0;
BA_ "GenMsgCycleTime" BO_ 2172674049 50;
BA_ "GenMsgCycleTimeFast" BO_ 2172674049 0;
BA_ "GenMsgNrOfRepetition" BO_ 2172674049 0;
BA_ "VFrameFormat" BO_ 2172674049 1;
BA_ "Description" SG_ 2172674049 ESC_Crc1Val "The data area for CRC calculation is based on the data length (DLC) of the message DB.

The CRC shall be calculated over the entire data block (excluding the CRC bytes) including the user data, alive counter and Data ID

 

- CRC Polynomial (0x1021) , Initial Value : 0xFFFF, XOR value : 0x0000, Data ID : Message ID + 0xF800 

- The initial value is for CRC calculation and the message should be sent with the calculated result value. 

- The mathematical expression to 16 bit CRC polynomial is given here. G(x) = x16 + x12 + x5 + 1";
BA_ "GenSigStartValue" SG_ 2172674049 ESC_Crc1Val 65535;
BA_ "UserSigValidity" SG_ 2172674049 ESC_Crc1Val 3;
BA_ "RoutingFactor" SG_ 2172674049 ESC_Crc1Val 5;
BA_ "Version" SG_ 2172674049 ESC_Crc1Val "18.11.08";
BA_ "Description" SG_ 2172674049 ESC_AlvCnt1Val "For the first transmission request for a data element the counter shall be initialized with 0 and shall be incremented by 1 for every subsequent send request. 

When the counter reaches the maximum value(0xFF), then it shall restart with 0 for the next send request";
BA_ "UserSigValidity" SG_ 2172674049 ESC_AlvCnt1Val 3;
BA_ "RoutingFactor" SG_ 2172674049 ESC_AlvCnt1Val 5;
BA_ "Version" SG_ 2172674049 ESC_AlvCnt1Val "18.11.08";
BA_ "Description" SG_ 2172674049 TCS_LmpSta "The signal indicates the status of the ¡°TCS/ESC Function/Warning Lamp¡±";
BA_ "UserSigValidity" SG_ 2172674049 TCS_LmpSta 3;
BA_ "RoutingFactor" SG_ 2172674049 TCS_LmpSta 5;
BA_ "Version" SG_ 2172674049 TCS_LmpSta "17.12.00";
BA_ "Description" SG_ 2172674049 TCS_OffLmpSta "The signal indicates the status of the ¡°TCS/ESC OFF SW Lamp¡±";
BA_ "UserSigValidity" SG_ 2172674049 TCS_OffLmpSta 3;
BA_ "RoutingFactor" SG_ 2172674049 TCS_OffLmpSta 5;
BA_ "Version" SG_ 2172674049 TCS_OffLmpSta "17.12.00";
BA_ "Description" SG_ 2172674049 ESC_OffTempSta "Information regarding the ESC OFF step by switch input of driver.";
BA_ "UserSigValidity" SG_ 2172674049 ESC_OffTempSta 3;
BA_ "RoutingFactor" SG_ 2172674049 ESC_OffTempSta 5;
BA_ "Version" SG_ 2172674049 ESC_OffTempSta "17.12.00";
BA_ "Description" SG_ 2172674049 ESC_OffSwSta "This signal is to indicate the esc off switch is pressed or not.";
BA_ "UserSigValidity" SG_ 2172674049 ESC_OffSwSta 3;
BA_ "RoutingFactor" SG_ 2172674049 ESC_OffSwSta 5;
BA_ "Version" SG_ 2172674049 ESC_OffSwSta "20.05.02";
BA_ "Description" SG_ 2172674049 DBC_WrngLmpSta "The signal indicates the status of the ¡°DBC Warning lamp¡±";
BA_ "UserSigValidity" SG_ 2172674049 DBC_WrngLmpSta 3;
BA_ "RoutingFactor" SG_ 2172674049 DBC_WrngLmpSta 5;
BA_ "Version" SG_ 2172674049 DBC_WrngLmpSta "17.12.00";
BA_ "Description" SG_ 2172674049 DBC_FuncLmpSta "The signal indicates the status of the ¡°DBC Function lamp¡±";
BA_ "UserSigValidity" SG_ 2172674049 DBC_FuncLmpSta 3;
BA_ "RoutingFactor" SG_ 2172674049 DBC_FuncLmpSta 5;
BA_ "Version" SG_ 2172674049 DBC_FuncLmpSta "17.12.00";
BA_ "Description" SG_ 2172674049 DBC_ClusterDis "DBC Pop-up Signal for Deactivation";
BA_ "UserSigValidity" SG_ 2172674049 DBC_ClusterDis 3;
BA_ "RoutingFactor" SG_ 2172674049 DBC_ClusterDis 5;
BA_ "Version" SG_ 2172674049 DBC_ClusterDis "18.07.03";
BA_ "Description" SG_ 2172674049 ESC_SprtLmpSta "This signal indicates the status of the 'ESC SPORT Lamp'";
BA_ "UserSigValidity" SG_ 2172674049 ESC_SprtLmpSta 3;
BA_ "RoutingFactor" SG_ 2172674049 ESC_SprtLmpSta 5;
BA_ "Version" SG_ 2172674049 ESC_SprtLmpSta "20.10.00";
BA_ "Description" SG_ 2172674049 ESC_BrkCtrlSta "This signal indicates that if brake control from the ECU request is in activation or not  during cruise control or speed limiter.";
BA_ "UserSigValidity" SG_ 2172674049 ESC_BrkCtrlSta 3;
BA_ "RoutingFactor" SG_ 2172674049 ESC_BrkCtrlSta 5;
BA_ "Version" SG_ 2172674049 ESC_BrkCtrlSta "17.12.00";
BA_ "GenMsgSendType" BO_ 2172674050 0;
BA_ "GenMsgCycleTime" BO_ 2172674050 50;
BA_ "GenMsgCycleTimeFast" BO_ 2172674050 0;
BA_ "GenMsgNrOfRepetition" BO_ 2172674050 0;
BA_ "VFrameFormat" BO_ 2172674050 1;
BA_ "Description" SG_ 2172674050 TCS_Sta "Information regarding the status of TCS function.



If the function has not been coded(fixed) yet, this signal will be transmitted as 0xE.



If the vehicle has been applied only ABS(without ESC), this signal will be fixed as 0x0.";
BA_ "UserSigValidity" SG_ 2172674050 TCS_Sta 3;
BA_ "RoutingFactor" SG_ 2172674050 TCS_Sta 5;
BA_ "Version" SG_ 2172674050 TCS_Sta "18.12.01";
BA_ "Description" SG_ 2172674050 TCS_PreActvSta "Pre TCS Control Signal";
BA_ "UserSigValidity" SG_ 2172674050 TCS_PreActvSta 3;
BA_ "RoutingFactor" SG_ 2172674050 TCS_PreActvSta 5;
BA_ "Version" SG_ 2172674050 TCS_PreActvSta "17.12.00";
BA_ "Description" SG_ 2172674050 DBC_Sta "Information regarding the status of DBC function.



If the function has not been coded(fixed) yet, this signal will be transmitted as 0xE.";
BA_ "UserSigValidity" SG_ 2172674050 DBC_Sta 3;
BA_ "RoutingFactor" SG_ 2172674050 DBC_Sta 5;
BA_ "Version" SG_ 2172674050 DBC_Sta "18.12.01";
BA_ "Description" SG_ 2172674050 TCS_TqFlag "Flag indicating positive or negative TCS Intervention";
BA_ "UserSigValidity" SG_ 2172674050 TCS_TqFlag 3;
BA_ "RoutingFactor" SG_ 2172674050 TCS_TqFlag 5;
BA_ "Version" SG_ 2172674050 TCS_TqFlag "18.07.01";
BA_ "Description" SG_ 2172674050 MSR_TqFlag "Flag indicating positive or negative MSR Intervention";
BA_ "UserSigValidity" SG_ 2172674050 MSR_TqFlag 3;
BA_ "RoutingFactor" SG_ 2172674050 MSR_TqFlag 5;
BA_ "Version" SG_ 2172674050 MSR_TqFlag "18.07.01";
BA_ "Description" SG_ 2172674050 HAC_Sta "Information regarding the status of HAC function.



If the function has not been coded(fixed) yet, this signal wilil be transmitted as 0xE.";
BA_ "UserSigValidity" SG_ 2172674050 HAC_Sta 3;
BA_ "RoutingFactor" SG_ 2172674050 HAC_Sta 5;
BA_ "Version" SG_ 2172674050 HAC_Sta "18.12.01";
BA_ "Description" SG_ 2172674050 BJD_Flag "Judder Detection Flag

0x0(No Event), 0x1(Event)";
BA_ "UserSigValidity" SG_ 2172674050 BJD_Flag 3;
BA_ "RoutingFactor" SG_ 2172674050 BJD_Flag 5;
BA_ "Version" SG_ 2172674050 BJD_Flag "20.04.02";
BA_ "Description" SG_ 2172674050 TCS_SlwTqFlag "Flag indicating positive or negative SLOW TCS Intervention";
BA_ "UserSigValidity" SG_ 2172674050 TCS_SlwTqFlag 3;
BA_ "RoutingFactor" SG_ 2172674050 TCS_SlwTqFlag 5;
BA_ "Version" SG_ 2172674050 TCS_SlwTqFlag "18.07.01";
BA_ "Description" SG_ 2172674050 TCS_Req "Request for an indicated desired engine torque, the combination of signals calls, on the one hand, for a desire for charge reduction (TCS or ESC function), and, on the other hand, for a desire for charge increase (MSR function).



TCS_REQ : Identifies a TCS control or ESC control intervention. This bit is to prevent the triggering of unintended TCS/ESC interventions.



TCS function:

In the case of a torque reduction, following conditions must be fulfilled. : 

TCS_REQ=1, MSR_C_REQ=0, TQI_TCS < 0FFH and TQI_MSR = 00H



MSR function :

 In the case of a torque increase, following conditions must be fulfilled. : 

 MSR_C_REQ = 1, TCS_REQ = 0, TQI_MSR > 00H and TQI_TCS = 1¡¯s complement of TQI_MSR";
BA_ "UserSigValidity" SG_ 2172674050 TCS_Req 3;
BA_ "RoutingFactor" SG_ 2172674050 TCS_Req 5;
BA_ "Version" SG_ 2172674050 TCS_Req "17.12.00";
BA_ "Description" SG_ 2172674050 MSR_FuncReq "Request for an indicated desired engine torque, the combination of signals calls, on the one hand, for a desire for charge reduction (TCS or ESC function), and, on the other hand, for a desire for charge increase (MSR function).



MSR_C_REQ : Identifies an engine drag torque control for which fuel cut off prohibition is specified.



TCS function:

In the case of a torque reduction, following conditions must be fulfilled. : 

TCS_REQ=1, MSR_C_REQ=0, TQI_TCS < 0FFH and TQI_MSR = 00H



MSR function :

 In the case of a torque increase, following conditions must be fulfilled. : 

 MSR_C_REQ = 1, TCS_REQ = 0, TQI_MSR > 00H and TQI_TCS = 1¡¯s complement of TQI_MSR";
BA_ "UserSigValidity" SG_ 2172674050 MSR_FuncReq 3;
BA_ "RoutingFactor" SG_ 2172674050 MSR_FuncReq 5;
BA_ "Version" SG_ 2172674050 MSR_FuncReq "17.12.00";
BA_ "Description" SG_ 2172674050 TCS_GearShftCharacteristicVal "Interface signal between TCS/ESC and TCU influencing the TCU switching characteristics in the case of an TCS control system.";
BA_ "UserSigValidity" SG_ 2172674050 TCS_GearShftCharacteristicVal 3;
BA_ "RoutingFactor" SG_ 2172674050 TCS_GearShftCharacteristicVal 5;
BA_ "Version" SG_ 2172674050 TCS_GearShftCharacteristicVal "17.12.00";
BA_ "Description" SG_ 2172674050 TCS_ManufacturerVal "TCS manufacturer information to distinguish between a system which requires only TQI_TCS function and a system which requires both TQI_TCS and TQI_SLW_TCS functions. This signal indicates that TCS requests torque reduction using only TQI_TCS or using both TQI_TCS and TQI_SLW_TCS.



If this signal is set to '1', this means that torque reduction method (Throttle Control or Injection Control) is determined by the value of TQI_TCS only. (TQI_SLW_TCS is not used and should be set to FFH)";
BA_ "UserSigValidity" SG_ 2172674050 TCS_ManufacturerVal 3;
BA_ "RoutingFactor" SG_ 2172674050 TCS_ManufacturerVal 5;
BA_ "Version" SG_ 2172674050 TCS_ManufacturerVal "17.12.00";
BA_ "Description" SG_ 2172674050 TCS_TqIntrvntnVal "Request for an indicated desired engine torque, the combination of signals calls, on the one hand, for a desire for charge reduction (TCS or ESC function), and, on the other hand, for a desire for charge increase (MSR function).



TQI_TCS : Torque reduction according to TQI_TCS is accomplished in the EMS by different methodes depending on the type of engine (Diesel, Gasoline, with or without ETC). Possible methodes are the reduction of airflow into the engine cylinders, the ignition angle adjustment and/or shutdown of cylinders and the reduction of injection etc. Torque reduction down to the engine drag torque range has to be possible



TCS function:

In the case of a torque reduction, following conditions must be fulfilled. : 

TCS_REQ=1, MSR_C_REQ=0, TQI_TCS < 0FFH and TQI_MSR = 00H



MSR function :

 In the case of a torque increase, following conditions must be fulfilled. : 

 MSR_C_REQ = 1, TCS_REQ = 0, TQI_MSR > 00H and TQI_TCS = 1¡¯s complement of TQI_MSR 



The specified torque TQI_x is referred to a maximum torque TQ_STND. From this conversion into a physical quantity results a range of 0..99.6094% for TQ_STND.";
BA_ "GenSigStartValue" SG_ 2172674050 TCS_TqIntrvntnVal 255;
BA_ "UserSigValidity" SG_ 2172674050 TCS_TqIntrvntnVal 3;
BA_ "RoutingFactor" SG_ 2172674050 TCS_TqIntrvntnVal 5;
BA_ "Version" SG_ 2172674050 TCS_TqIntrvntnVal "17.12.00";
BA_ "Description" SG_ 2172674050 MSR_TqIntrvntnVal "Request for an indicated desired engine torque, the combination of signals calls, on the one hand, for a desire for charge reduction (TCS or ESC function), and, on the other hand, for a desire for charge increase (MSR function).



TQI_MSR : The torque increase according to TQI_MSR is accomplished in the EMS via the idle-charge actuator (limited by the maximum air flow of the idle-charge actuator) or electrical throttle controller (DIESEL : increase of fuel injection) up to the driving torque range.



TCS function:

In the case of a torque reduction, following conditions must be fulfilled. : 

TCS_REQ=1, MSR_C_REQ=0, TQI_TCS < 0FFH and TQI_MSR = 00H



MSR function :

 In the case of a torque increase, following conditions must be fulfilled. : 

 MSR_C_REQ = 1, TCS_REQ = 0, TQI_MSR > 00H and TQI_TCS = 1¡¯s complement of TQI_MSR 



The specified torque TQI_x is referred to a maximum torque TQ_STND. From this conversion into a physical quantity results a range of 0..99.6094% for TQ_STND.";
BA_ "UserSigValidity" SG_ 2172674050 MSR_TqIntrvntnVal 3;
BA_ "RoutingFactor" SG_ 2172674050 MSR_TqIntrvntnVal 5;
BA_ "Version" SG_ 2172674050 MSR_TqIntrvntnVal "17.12.00";
BA_ "Description" SG_ 2172674050 TCS_SlwTqIntrvntnVal "Request for an indicated desired engine torque, the combination of signals calls, on the one hand, for a desire for charge reduction (TCS or ESC function), and, on the other hand, for a desire for charge increase (MSR function).



TQI_SLW_TCS : The driving torque reduction according to TQI_SLW_TCS is accomplished in the EMS by reduction of airflow into engine cylinders (electrical throttle control) down to the engine drag torque range.



The specified torque TQI_x is referred to a maximum torque TQ_STND. From this conversion into a physical quantity results a range of 0..99.6094% for TQ_STND.";
BA_ "GenSigStartValue" SG_ 2172674050 TCS_SlwTqIntrvntnVal 255;
BA_ "UserSigValidity" SG_ 2172674050 TCS_SlwTqIntrvntnVal 3;
BA_ "RoutingFactor" SG_ 2172674050 TCS_SlwTqIntrvntnVal 5;
BA_ "Version" SG_ 2172674050 TCS_SlwTqIntrvntnVal "17.12.00";
BA_ "Description" SG_ 2172674050 ESC_Sta "Information regarding the status of ESC function.



If the function has not been coded(fixed) yet, this signal will be transmitted as 0xE.



If the vehicle has been applied only ABS(without ESC), this signal will be fixed as 0x0.";
BA_ "UserSigValidity" SG_ 2172674050 ESC_Sta 3;
BA_ "RoutingFactor" SG_ 2172674050 ESC_Sta 5;
BA_ "Version" SG_ 2172674050 ESC_Sta "18.12.01";
BA_ "GenMsgSendType" BO_ 2172674051 0;
BA_ "GenMsgCycleTime" BO_ 2172674051 50;
BA_ "GenMsgCycleTimeFast" BO_ 2172674051 0;
BA_ "GenMsgNrOfRepetition" BO_ 2172674051 0;
BA_ "VFrameFormat" BO_ 2172674051 1;
BA_ "Description" SG_ 2172674051 ESC_CylPrsrVal "This signal indicates pressure of brake master cylinder and provides information how deeply  a driver is pressing brake pedal.";
BA_ "UserSigValidity" SG_ 2172674051 ESC_CylPrsrVal 3;
BA_ "RoutingFactor" SG_ 2172674051 ESC_CylPrsrVal 5;
BA_ "Version" SG_ 2172674051 ESC_CylPrsrVal "17.12.00";
BA_ "Description" SG_ 2172674051 ESC_CylPrsrSta "This signal indicates validity of CYL_PRES signal.";
BA_ "GenSigStartValue" SG_ 2172674051 ESC_CylPrsrSta 1;
BA_ "UserSigValidity" SG_ 2172674051 ESC_CylPrsrSta 3;
BA_ "RoutingFactor" SG_ 2172674051 ESC_CylPrsrSta 5;
BA_ "Version" SG_ 2172674051 ESC_CylPrsrSta "18.02.00";
BA_ "Description" SG_ 2172674051 ESC_CylPrsrDiagSta "This signal indicates self-diagnosis mode of master cylinder pressure signal. During system check, master cylinder pressure information cannot be sent(not available) and this bit should be set to 1.";
BA_ "GenSigStartValue" SG_ 2172674051 ESC_CylPrsrDiagSta 1;
BA_ "UserSigValidity" SG_ 2172674051 ESC_CylPrsrDiagSta 3;
BA_ "RoutingFactor" SG_ 2172674051 ESC_CylPrsrDiagSta 5;
BA_ "Version" SG_ 2172674051 ESC_CylPrsrDiagSta "17.12.00";
BA_ "Description" SG_ 2172674051 ESC_CylPrsrFlagSta "This signal means that the pressure of master cylinder is 15 bar or over.

(0x0 : under 15 bar, 0x1 : 15 bar or over)



This signal may be difference with actual BLS(Brake Lamp Switch) state.

So the ESC does not guarantee using this signal as substituting the BLS.

(If any problem is happened in other ECU, ESC does not cope with it)



And the other ECUs receiving this signal have to check the value of CYL_PRES_STAT.

If the CYL_PRES_STAT signal's value is invalid, other ECUs do not use this signal to control parameter.(This signal is invalid, too)";
BA_ "UserSigValidity" SG_ 2172674051 ESC_CylPrsrFlagSta 3;
BA_ "RoutingFactor" SG_ 2172674051 ESC_CylPrsrFlagSta 5;
BA_ "Version" SG_ 2172674051 ESC_CylPrsrFlagSta "17.12.00";
BA_ "Description" SG_ 2172674051 ESC_VsmActvSta "ESC controller provides an information on VSM (ESC+MDPS) Active signal. It indicates VSM control is

active or inactive.";
BA_ "UserSigValidity" SG_ 2172674051 ESC_VsmActvSta 3;
BA_ "RoutingFactor" SG_ 2172674051 ESC_VsmActvSta 5;
BA_ "Version" SG_ 2172674051 ESC_VsmActvSta "17.12.00";
BA_ "Description" SG_ 2172674051 ESC_VsmDfctvSta "Information regarding the VSM ¡°defective¡± Indication";
BA_ "UserSigValidity" SG_ 2172674051 ESC_VsmDfctvSta 3;
BA_ "RoutingFactor" SG_ 2172674051 ESC_VsmDfctvSta 5;
BA_ "Version" SG_ 2172674051 ESC_VsmDfctvSta "17.12.00";
BA_ "Description" SG_ 2172674051 ESC_VsmCtrlModSta "Classify mode1 , mode2 and mode3 of torque overlay. 

- Mode1 is sensor value overlay mode.

- Mode2 is output torque overlay mode. 

- Mode3 is for an alternative mode for Mobis VSM system";
BA_ "UserSigValidity" SG_ 2172674051 ESC_VsmCtrlModSta 3;
BA_ "RoutingFactor" SG_ 2172674051 ESC_VsmCtrlModSta 5;
BA_ "Version" SG_ 2172674051 ESC_VsmCtrlModSta "17.12.00";
BA_ "Description" SG_ 2172674051 ESC_StrTqReq "Requested additional Assist torque of MDPS gets from ESC to make vehicle more stable.



Relationship between signals:

ESC_StrTrqReq = 0 Nm  ( DST inactive )

-> ESC_DstAct = 0, ESC_DstCtrMode = 0

ESC_StrTrqReq < 0 Nm  or  ESC_StrTrqReq > 0 Nm  (active DST intervention)

-> ESC_DstAct = 1, ESC_DstCtrMode = 1";
BA_ "GenSigStartValue" SG_ 2172674051 ESC_StrTqReq 2048;
BA_ "UserSigValidity" SG_ 2172674051 ESC_StrTqReq 3;
BA_ "RoutingFactor" SG_ 2172674051 ESC_StrTqReq 5;
BA_ "Version" SG_ 2172674051 ESC_StrTqReq "17.12.00";
BA_ "Description" SG_ 2172674051 ESC_LongAccelOffstCalibPrmtr "This signal indicates information regarding the calibration parameter for longitudinal acceleration value.

This signal doesn't guarantee the actual offset value.

But this signal is the result of the measuring process about the offset which is the longitudinal acceleration value when the vehicle is on the flat ground.

(ÀÌ ½ÅÈ£´Â Â÷·®ÀÌ ÆòÆòÇÑ Áö¸é¿¡ ÀÖÀ» ¶§ Á¾¹æÇâ °¡¼Óµµ °ªÀÎ ¿É¼Â¿¡ ´ëÇÑ ÃøÁ¤ ÇÁ·Î¼¼½ºÀÇ °á°úÀÓ.)

Hence, the ECUs which receive this signal have to use this signal as substract from the longitudinal acceleration value from the sensor.

(µû¶ó¼­, ÀÌ ½ÅÈ£¸¦ ¼ö½ÅÇÏ´Â ECU´Â ÀÌ ½ÅÈ£¸¦ ¼¾¼­ÀÇ Á¾¹æÇâ °¡¼Óµµ °ª¿¡¼­ »©±â À§ÇØ »ç¿ëÇØ¾ß ÇÔ.)

The allowed use of this signal is for harmonizing with ESC and the other ECU.

So the other ECU must not diagnosis about this signal.



physical range : -0.255g..0.255g = 000H..1FEh



Conversion : (PH) = ((HEX)-0x0FFH)*0.001[g/digit]

                              = (HEX)*0.001[g/digit] - 0.255[g]

                     1FFh = Offset Calibration has not completed yet.";
BA_ "GenSigStartValue" SG_ 2172674051 ESC_LongAccelOffstCalibPrmtr 255;
BA_ "UserSigValidity" SG_ 2172674051 ESC_LongAccelOffstCalibPrmtr 3;
BA_ "RoutingFactor" SG_ 2172674051 ESC_LongAccelOffstCalibPrmtr 5;
BA_ "Version" SG_ 2172674051 ESC_LongAccelOffstCalibPrmtr "19.11.02";
BA_ "Description" SG_ 2172674051 ESC_IMURstStaAck "This signal is used to response for IMU sensor's reset status.

When the IMU sensor is about to reset, it will transmit the reset flag.

(After then the ACU will wait for acknowledge signal from ESC.)

If the ESC receive the reset flag from ACU, ESC will transmit this signal in order to let the ACU knows.";
BA_ "UserSigValidity" SG_ 2172674051 ESC_IMURstStaAck 3;
BA_ "RoutingFactor" SG_ 2172674051 ESC_IMURstStaAck 5;
BA_ "Version" SG_ 2172674051 ESC_IMURstStaAck "18.03.06";
BA_ "GenMsgSendType" BO_ 2172674052 0;
BA_ "GenMsgCycleTime" BO_ 2172674052 50;
BA_ "GenMsgCycleTimeFast" BO_ 2172674052 0;
BA_ "GenMsgNrOfRepetition" BO_ 2172674052 0;
BA_ "VFrameFormat" BO_ 2172674052 1;
BA_ "Description" SG_ 2172674052 AVH_Sta "This signal indicates whether the vehicle is held with hydraulic brake (service brake).";
BA_ "UserSigValidity" SG_ 2172674052 AVH_Sta 3;
BA_ "RoutingFactor" SG_ 2172674052 AVH_Sta 5;
BA_ "Version" SG_ 2172674052 AVH_Sta "17.12.00";
BA_ "Description" SG_ 2172674052 AVH_CluDis "An ESC can show its information message to driver on a cluster or a display module with this signal.";
BA_ "UserSigValidity" SG_ 2172674052 AVH_CluDis 3;
BA_ "RoutingFactor" SG_ 2172674052 AVH_CluDis 5;
BA_ "Version" SG_ 2172674052 AVH_CluDis "20.01.02";
BA_ "Description" SG_ 2172674052 LDM_Sta "Information about ESC-Readiness to perform Dynamic Braking Function (DBF) or Automatic Vehicle Hold (AVH) which is requested by AVH switch.



LDM_STAT (0H)

 - EPB function : EPB is slave

LDM_STAT (1H)

 - EPB function : EPB stand alone";
BA_ "UserSigValidity" SG_ 2172674052 LDM_Sta 3;
BA_ "RoutingFactor" SG_ 2172674052 LDM_Sta 5;
BA_ "Version" SG_ 2172674052 LDM_Sta "17.12.00";
BA_ "Description" SG_ 2172674052 AVH_AlrmReq "This signal indicates that an ESC requests cluster or tone controller to ring the alarm according to the status of an ESC";
BA_ "UserSigValidity" SG_ 2172674052 AVH_AlrmReq 3;
BA_ "RoutingFactor" SG_ 2172674052 AVH_AlrmReq 5;
BA_ "Version" SG_ 2172674052 AVH_AlrmReq "17.12.00";
BA_ "Description" SG_ 2172674052 AVH_ActvStaLmpDis "This signal indicates AVH active status lamp request from ESC to cluster.";
BA_ "UserSigValidity" SG_ 2172674052 AVH_ActvStaLmpDis 3;
BA_ "RoutingFactor" SG_ 2172674052 AVH_ActvStaLmpDis 5;
BA_ "Version" SG_ 2172674052 AVH_ActvStaLmpDis "17.12.00";
BA_ "Description" SG_ 2172674052 AVH_LmpDis "Information about the status lamp request from ESC (AVH) to cluster.";
BA_ "UserSigValidity" SG_ 2172674052 AVH_LmpDis 3;
BA_ "RoutingFactor" SG_ 2172674052 AVH_LmpDis 5;
BA_ "Version" SG_ 2172674052 AVH_LmpDis "17.12.00";
BA_ "Description" SG_ 2172674052 AWD_CrdnShftTqLimVal "Interface signal between ABS/TCS/ESC and 4WD, demands 4WD cardan shaft torque limit.";
BA_ "GenSigStartValue" SG_ 2172674052 AWD_CrdnShftTqLimVal 64255;
BA_ "UserSigValidity" SG_ 2172674052 AWD_CrdnShftTqLimVal 3;
BA_ "RoutingFactor" SG_ 2172674052 AWD_CrdnShftTqLimVal 5;
BA_ "Version" SG_ 2172674052 AWD_CrdnShftTqLimVal "17.12.00";
BA_ "Description" SG_ 2172674052 EPB_ActvReq "This signal indicates that an ESC requests EPB to activate braking. 



REQ_EPB_ACT (0H)

 - AVH status : Don¡¯t care

REQ_EPB_ACT (1H)

 - AVH status : Active

REQ_EPB_ACT (2H)

 - AVH status : Active

REQ_EPB_ACT (3H)

 - AVH status : Disabled

(EPB Stand alone)";
BA_ "UserSigValidity" SG_ 2172674052 EPB_ActvReq 3;
BA_ "RoutingFactor" SG_ 2172674052 EPB_ActvReq 5;
BA_ "Version" SG_ 2172674052 EPB_ActvReq "17.12.00";
BA_ "Description" SG_ 2172674052 AWD_CltchDtyLimVal "Interface signal between ABS/TCS/ESC and 4WD and demands 4WD clutch duty limit.";
BA_ "UserSigValidity" SG_ 2172674052 AWD_CltchDtyLimVal 3;
BA_ "RoutingFactor" SG_ 2172674052 AWD_CltchDtyLimVal 5;
BA_ "Version" SG_ 2172674052 AWD_CltchDtyLimVal "17.12.00";
BA_ "Description" SG_ 2172674052 AWD_TransmsnTqLimModSta "This signal indicates that Interface signal between ESC and 4WD, selecting cardan shaft torque limitation mode of 4WD.";
BA_ "UserSigValidity" SG_ 2172674052 AWD_TransmsnTqLimModSta 3;
BA_ "RoutingFactor" SG_ 2172674052 AWD_TransmsnTqLimModSta 5;
BA_ "Version" SG_ 2172674052 AWD_TransmsnTqLimModSta "17.12.00";
BA_ "Description" SG_ 2172674052 AWD_RrWhlDtyLimReq "This signal indicates that ESC request 4WD ECU to limit control duty of rear wheels for improvement of stability of a vehicle during ESC control.";
BA_ "UserSigValidity" SG_ 2172674052 AWD_RrWhlDtyLimReq 3;
BA_ "RoutingFactor" SG_ 2172674052 AWD_RrWhlDtyLimReq 5;
BA_ "Version" SG_ 2172674052 AWD_RrWhlDtyLimReq "17.12.00";
BA_ "Description" SG_ 2172674052 EPB_StaReq "This signal indicates the validity of REQ_EPB_ACT (ESC request for EPB to activate braking) signal.";
BA_ "GenSigStartValue" SG_ 2172674052 EPB_StaReq 1;
BA_ "UserSigValidity" SG_ 2172674052 EPB_StaReq 3;
BA_ "RoutingFactor" SG_ 2172674052 EPB_StaReq 5;
BA_ "Version" SG_ 2172674052 EPB_StaReq "17.12.00";
BA_ "Description" SG_ 2172674052 AWD_FastOpnCrdnShftCltchReq "Interface signal between ESC and 4WD, demands fast opening or torque limit of the 4WD cardan shaft clutch.";
BA_ "UserSigValidity" SG_ 2172674052 AWD_FastOpnCrdnShftCltchReq 3;
BA_ "RoutingFactor" SG_ 2172674052 AWD_FastOpnCrdnShftCltchReq 5;
BA_ "Version" SG_ 2172674052 AWD_FastOpnCrdnShftCltchReq "17.12.00";
BA_ "Description" SG_ 2172674052 ECD_ActvSta "ECD Active signal indicates whether ECD function is active (operating) or not.";
BA_ "UserSigValidity" SG_ 2172674052 ECD_ActvSta 3;
BA_ "RoutingFactor" SG_ 2172674052 ECD_ActvSta 5;
BA_ "Version" SG_ 2172674052 ECD_ActvSta "17.12.00";
BA_ "GenMsgCycleTime" BO_ 1458 0;
BA_ "GenMsgCycleTimeFast" BO_ 1458 0;
BA_ "GenMsgNrOfRepetition" BO_ 1458 0;
BA_ "DiagRequest" BO_ 1458 1;
BA_ "GenMsgILSupport" BO_ 1458 0;
BA_ "TpMessage" BO_ 1458 1;
BA_ "TpTxIndex" BO_ 1458 212;
BA_ "Description" SG_ 1458 GST_ATS_Byte0 "TP Index : 212";
BA_ "UsrSigPurpose" SG_ 1458 GST_ATS_Byte0 3;
BA_ "UserSigValidity" SG_ 1458 GST_ATS_Byte0 0;
BA_REL_ "GenSigTimeoutTime" BU_SG_REL_ ATS SG_ 1458 GST_ATS_Byte0 0;
BA_ "NetworkRequest" SG_ 1458 GST_ATS_Byte0 0;
BA_ "NetworkRequestHoldingTime" SG_ 1458 GST_ATS_Byte0 5000;
BA_ "Version" SG_ 1458 GST_ATS_Byte0 "21.02.04";
BA_ "Description" SG_ 1458 GST_ATS_Byte2 "TP Index : 212";
BA_ "UsrSigPurpose" SG_ 1458 GST_ATS_Byte2 3;
BA_ "UserSigValidity" SG_ 1458 GST_ATS_Byte2 0;
BA_REL_ "GenSigTimeoutTime" BU_SG_REL_ ATS SG_ 1458 GST_ATS_Byte2 0;
BA_ "NetworkRequest" SG_ 1458 GST_ATS_Byte2 0;
BA_ "NetworkRequestHoldingTime" SG_ 1458 GST_ATS_Byte2 5000;
BA_ "Version" SG_ 1458 GST_ATS_Byte2 "21.02.04";
BA_ "Description" SG_ 1458 GST_ATS_Byte3 "TP Index : 212";
BA_ "UsrSigPurpose" SG_ 1458 GST_ATS_Byte3 3;
BA_ "UserSigValidity" SG_ 1458 GST_ATS_Byte3 0;
BA_REL_ "GenSigTimeoutTime" BU_SG_REL_ ATS SG_ 1458 GST_ATS_Byte3 0;
BA_ "NetworkRequest" SG_ 1458 GST_ATS_Byte3 0;
BA_ "NetworkRequestHoldingTime" SG_ 1458 GST_ATS_Byte3 5000;
BA_ "Version" SG_ 1458 GST_ATS_Byte3 "21.02.04";
BA_ "Description" SG_ 1458 GST_ATS_Byte4 "TP Index : 212";
BA_ "UsrSigPurpose" SG_ 1458 GST_ATS_Byte4 3;
BA_ "UserSigValidity" SG_ 1458 GST_ATS_Byte4 0;
BA_REL_ "GenSigTimeoutTime" BU_SG_REL_ ATS SG_ 1458 GST_ATS_Byte4 0;
BA_ "NetworkRequest" SG_ 1458 GST_ATS_Byte4 0;
BA_ "NetworkRequestHoldingTime" SG_ 1458 GST_ATS_Byte4 5000;
BA_ "Version" SG_ 1458 GST_ATS_Byte4 "21.02.04";
BA_ "Description" SG_ 1458 GST_ATS_Byte5 "TP Index : 212";
BA_ "UsrSigPurpose" SG_ 1458 GST_ATS_Byte5 3;
BA_ "UserSigValidity" SG_ 1458 GST_ATS_Byte5 0;
BA_REL_ "GenSigTimeoutTime" BU_SG_REL_ ATS SG_ 1458 GST_ATS_Byte5 0;
BA_ "NetworkRequest" SG_ 1458 GST_ATS_Byte5 0;
BA_ "NetworkRequestHoldingTime" SG_ 1458 GST_ATS_Byte5 5000;
BA_ "Version" SG_ 1458 GST_ATS_Byte5 "21.02.04";
BA_ "Description" SG_ 1458 GST_ATS_Byte6 "TP Index : 212";
BA_ "UsrSigPurpose" SG_ 1458 GST_ATS_Byte6 3;
BA_ "UserSigValidity" SG_ 1458 GST_ATS_Byte6 0;
BA_REL_ "GenSigTimeoutTime" BU_SG_REL_ ATS SG_ 1458 GST_ATS_Byte6 0;
BA_ "NetworkRequest" SG_ 1458 GST_ATS_Byte6 0;
BA_ "NetworkRequestHoldingTime" SG_ 1458 GST_ATS_Byte6 5000;
BA_ "Version" SG_ 1458 GST_ATS_Byte6 "21.02.04";
BA_ "Description" SG_ 1458 GST_ATS_Byte7 "TP Index : 212";
BA_ "UsrSigPurpose" SG_ 1458 GST_ATS_Byte7 3;
BA_ "UserSigValidity" SG_ 1458 GST_ATS_Byte7 0;
BA_REL_ "GenSigTimeoutTime" BU_SG_REL_ ATS SG_ 1458 GST_ATS_Byte7 0;
BA_ "NetworkRequest" SG_ 1458 GST_ATS_Byte7 0;
BA_ "NetworkRequestHoldingTime" SG_ 1458 GST_ATS_Byte7 5000;
BA_ "Version" SG_ 1458 GST_ATS_Byte7 "21.02.04";
BA_ "Description" SG_ 1458 GST_ATS_Byte1 "TP Index : 212";
BA_ "UsrSigPurpose" SG_ 1458 GST_ATS_Byte1 3;
BA_ "UserSigValidity" SG_ 1458 GST_ATS_Byte1 0;
BA_REL_ "GenSigTimeoutTime" BU_SG_REL_ ATS SG_ 1458 GST_ATS_Byte1 0;
BA_ "NetworkRequest" SG_ 1458 GST_ATS_Byte1 0;
BA_ "NetworkRequestHoldingTime" SG_ 1458 GST_ATS_Byte1 5000;
BA_ "Version" SG_ 1458 GST_ATS_Byte1 "21.02.04";
BA_ "GenMsgCycleTime" BO_ 491 0;
BA_ "Description" SG_ 491 CF_AVN_Roof_OprLvSet "Smart Glass(Roof) usm setting signal";
BA_ "GenSigSendType" SG_ 491 CF_AVN_Roof_OprLvSet 4;
BA_ "UserSigValidity" SG_ 491 CF_AVN_Roof_OprLvSet 3;
BA_REL_ "GenSigTimeoutTime" BU_SG_REL_ SGU SG_ 491 CF_AVN_Roof_OprLvSet 0;
BA_ "Version" SG_ 491 CF_AVN_Roof_OprLvSet "21.07.05";
BA_ "Description" SG_ 491 CF_AVN_3rdRightDoor_OptLvlSet "Smart Glass (3rd Right Door) usm set signal";
BA_ "GenSigSendType" SG_ 491 CF_AVN_3rdRightDoor_OptLvlSet 4;
BA_ "UserSigValidity" SG_ 491 CF_AVN_3rdRightDoor_OptLvlSet 3;
BA_REL_ "GenSigTimeoutTime" BU_SG_REL_ SGU SG_ 491 CF_AVN_3rdRightDoor_OptLvlSet 0;
BA_ "Version" SG_ 491 CF_AVN_3rdRightDoor_OptLvlSet "21.07.05";
BA_ "Description" SG_ 491 CF_AVN_RearDoor_OptLvlSet "Smart Glass (Rear Door) usm set signal";
BA_ "GenSigSendType" SG_ 491 CF_AVN_RearDoor_OptLvlSet 4;
BA_ "UserSigValidity" SG_ 491 CF_AVN_RearDoor_OptLvlSet 3;
BA_REL_ "GenSigTimeoutTime" BU_SG_REL_ SGU SG_ 491 CF_AVN_RearDoor_OptLvlSet 0;
BA_ "Version" SG_ 491 CF_AVN_RearDoor_OptLvlSet "21.07.05";
BA_ "Description" SG_ 491 CF_AVN_RollBlindOnOffSet "Related Smar Glass RollBlind On,Off for USM set signal";
BA_ "GenSigSendType" SG_ 491 CF_AVN_RollBlindOnOffSet 4;
BA_ "UserSigValidity" SG_ 491 CF_AVN_RollBlindOnOffSet 3;
BA_REL_ "GenSigTimeoutTime" BU_SG_REL_ SGU SG_ 491 CF_AVN_RollBlindOnOffSet 0;
BA_ "Version" SG_ 491 CF_AVN_RollBlindOnOffSet "21.07.07";
BA_ "Description" SG_ 491 CF_AVN_CluThmAutoSet_New "this signal is Cluster theme Auto set signal for New cluster theme";
BA_ "GenSigSendType" SG_ 491 CF_AVN_CluThmAutoSet_New 4;
BA_ "UserSigValidity" SG_ 491 CF_AVN_CluThmAutoSet_New 3;
BA_ "Version" SG_ 491 CF_AVN_CluThmAutoSet_New "21.11.07";
BA_ "Description" SG_ 491 CF_AVN_CluThmSet_New "This signal is Cluster theme large category menu select for Cluster New theme";
BA_ "GenSigSendType" SG_ 491 CF_AVN_CluThmSet_New 4;
BA_ "UserSigValidity" SG_ 491 CF_AVN_CluThmSet_New 3;
BA_ "Version" SG_ 491 CF_AVN_CluThmSet_New "21.11.07";
BA_ "Description" SG_ 491 CF_AVN_CluThmDtlSet_New "This signal is Cluster Theme small category menu select for Cluster New Theme";
BA_ "GenSigSendType" SG_ 491 CF_AVN_CluThmDtlSet_New 4;
BA_ "UserSigValidity" SG_ 491 CF_AVN_CluThmDtlSet_New 3;
BA_ "Version" SG_ 491 CF_AVN_CluThmDtlSet_New "21.11.07";
BA_ "Description" SG_ 491 CF_AVN_2ndLeftDoor_OptLvSet "Smart Glass (2nd Left Door) Usm set signal";
BA_ "GenSigSendType" SG_ 491 CF_AVN_2ndLeftDoor_OptLvSet 4;
BA_ "UserSigValidity" SG_ 491 CF_AVN_2ndLeftDoor_OptLvSet 3;
BA_REL_ "GenSigTimeoutTime" BU_SG_REL_ SGU SG_ 491 CF_AVN_2ndLeftDoor_OptLvSet 0;
BA_ "Version" SG_ 491 CF_AVN_2ndLeftDoor_OptLvSet "21.07.05";
BA_ "Description" SG_ 491 CF_AVN_2ndRightDoor_OptLvSet "Smart Glass (2nd Right Door) usm set signal";
BA_ "GenSigSendType" SG_ 491 CF_AVN_2ndRightDoor_OptLvSet 4;
BA_ "UserSigValidity" SG_ 491 CF_AVN_2ndRightDoor_OptLvSet 3;
BA_REL_ "GenSigTimeoutTime" BU_SG_REL_ SGU SG_ 491 CF_AVN_2ndRightDoor_OptLvSet 0;
BA_ "Version" SG_ 491 CF_AVN_2ndRightDoor_OptLvSet "21.07.05";
BA_ "Description" SG_ 491 CF_AVN_3rdLeftDoor_OptLvlSet "Smart Glass (3rd left door) usm set signal";
BA_ "GenSigSendType" SG_ 491 CF_AVN_3rdLeftDoor_OptLvlSet 4;
BA_ "UserSigValidity" SG_ 491 CF_AVN_3rdLeftDoor_OptLvlSet 3;
BA_REL_ "GenSigTimeoutTime" BU_SG_REL_ SGU SG_ 491 CF_AVN_3rdLeftDoor_OptLvlSet 0;
BA_ "Version" SG_ 491 CF_AVN_3rdLeftDoor_OptLvlSet "21.07.05";
BA_ "GenMsgSendType" BO_ 966 0;
BA_ "Description" SG_ 966 RCM_Crc1Val "The data area for CRC calculation is based on the data length (DLC) of the message DB.

The CRC shall be calculated over the entire data block (excluding the CRC bytes) including the user data, alive counter and Data ID 

 

- CRC Polynomial (0x1D) , Initial Value : 0x00, XOR value : 0xFF, Data ID Mode : Both, Data ID : Message ID + 0xF800 

- The initial value is for CRC calculation and the message should be sent with the calculated result value. 

The mathematical expression to 8 bit CRC polynomial is given here. G(x) = x8 + x4 + x3 + x2 + 1";
BA_ "GenSigSendType" SG_ 966 RCM_Crc1Val 4;
BA_ "GenSigStartValue" SG_ 966 RCM_Crc1Val 255;
BA_ "UserSigValidity" SG_ 966 RCM_Crc1Val 3;
BA_ "Version" SG_ 966 RCM_Crc1Val "21.02.01";
BA_ "Description" SG_ 966 RCM_AlvCnt1Val "For the first transmission request for a data element the counter shall be initialized with 0 and shall be incremented by 1

for every subsequent send request. When the counter reaches the maximum value(0xE), then it shall restart with 0 for the next send request";
BA_ "GenSigSendType" SG_ 966 RCM_AlvCnt1Val 4;
BA_ "UserSigValidity" SG_ 966 RCM_AlvCnt1Val 3;
BA_ "Version" SG_ 966 RCM_AlvCnt1Val "21.02.01";
BA_ "Description" SG_ 966 RCM_OptTyp "RCM (Roof Control Module) Option Type";
BA_ "GenSigSendType" SG_ 966 RCM_OptTyp 4;
BA_ "UserSigValidity" SG_ 966 RCM_OptTyp 0;
BA_REL_ "GenSigTimeoutTime" BU_SG_REL_ CGW_CCU SG_ 966 RCM_OptTyp 1500;
BA_ "Version" SG_ 966 RCM_OptTyp "21.02.02";
BA_ "Description" SG_ 966 RCM_SwStckDet "Sunroof Switch Stuck Detection";
BA_ "GenSigSendType" SG_ 966 RCM_SwStckDet 4;
BA_ "UserSigValidity" SG_ 966 RCM_SwStckDet 0;
BA_ "Version" SG_ 966 RCM_SwStckDet "21.02.02";
BA_ "Description" SG_ 966 RCM_SwSta "OHCL Sunroof Switch Input Status";
BA_ "GenSigSendType" SG_ 966 RCM_SwSta 4;
BA_ "UserSigValidity" SG_ 966 RCM_SwSta 0;
BA_ "Version" SG_ 966 RCM_SwSta "21.02.02";
BA_ "GenMsgSendType" BO_ 967 0;
BA_ "Description" SG_ 967 RCM_Crc2Val "The data area for CRC calculation is based on the data length (DLC) of the message DB.

The CRC shall be calculated over the entire data block (excluding the CRC bytes) including the user data, alive counter and Data ID 

 

- CRC Polynomial (0x1D) , Initial Value : 0x00, XOR value : 0xFF, Data ID Mode : Both, Data ID : Message ID + 0xF800 

- The initial value is for CRC calculation and the message should be sent with the calculated result value. 

The mathematical expression to 8 bit CRC polynomial is given here. G(x) = x8 + x4 + x3 + x2 + 1";
BA_ "GenSigSendType" SG_ 967 RCM_Crc2Val 4;
BA_ "GenSigStartValue" SG_ 967 RCM_Crc2Val 255;
BA_ "UserSigValidity" SG_ 967 RCM_Crc2Val 3;
BA_ "Version" SG_ 967 RCM_Crc2Val "21.02.01";
BA_ "Description" SG_ 967 RCM_AlvCnt2Val "For the first transmission request for a data element the counter shall be initialized with 0 and shall be incremented by 1

for every subsequent send request. When the counter reaches the maximum value(0xE), then it shall restart with 0 for the next send request";
BA_ "GenSigSendType" SG_ 967 RCM_AlvCnt2Val 4;
BA_ "UserSigValidity" SG_ 967 RCM_AlvCnt2Val 3;
BA_ "Version" SG_ 967 RCM_AlvCnt2Val "21.02.01";
BA_ "Description" SG_ 967 RCM_GlsHallSnsrPlsCnt "Sunroof Glass Motor Hall Sensor Pulse Count";
BA_ "GenSigSendType" SG_ 967 RCM_GlsHallSnsrPlsCnt 4;
BA_ "UserSigValidity" SG_ 967 RCM_GlsHallSnsrPlsCnt 0;
BA_ "Version" SG_ 967 RCM_GlsHallSnsrPlsCnt "21.02.02";
BA_ "Description" SG_ 967 RCM_SunroofOpnSta "Sunroof Glass Open Status";
BA_ "GenSigSendType" SG_ 967 RCM_SunroofOpnSta 4;
BA_ "UserSigValidity" SG_ 967 RCM_SunroofOpnSta 0;
BA_REL_ "GenSigTimeoutTime" BU_SG_REL_ CGW_CCU SG_ 967 RCM_SunroofOpnSta 1500;
BA_ "NetworkRequest" SG_ 967 RCM_SunroofOpnSta 0;
BA_ "NetworkRequestHoldingTime" SG_ 967 RCM_SunroofOpnSta 5000;
BA_ "Version" SG_ 967 RCM_SunroofOpnSta "21.02.02";
BA_ "Description" SG_ 967 RCM_GlsOpSta "Sunroof Glass Operation Status";
BA_ "GenSigSendType" SG_ 967 RCM_GlsOpSta 4;
BA_ "UserSigValidity" SG_ 967 RCM_GlsOpSta 0;
BA_REL_ "GenSigTimeoutTime" BU_SG_REL_ CGW_CCU SG_ 967 RCM_GlsOpSta 1500;
BA_ "Version" SG_ 967 RCM_GlsOpSta "21.02.02";
BA_ "Description" SG_ 967 RCM_GlsInitSta "Sunroof Glass Initialization Status";
BA_ "GenSigSendType" SG_ 967 RCM_GlsInitSta 4;
BA_ "UserSigValidity" SG_ 967 RCM_GlsInitSta 0;
BA_ "Version" SG_ 967 RCM_GlsInitSta "21.02.02";
BA_ "Description" SG_ 967 RCM_GlsAntPchSta "Sunroof Glass Anti Pinch Status";
BA_ "GenSigSendType" SG_ 967 RCM_GlsAntPchSta 4;
BA_ "UserSigValidity" SG_ 967 RCM_GlsAntPchSta 0;
BA_ "Version" SG_ 967 RCM_GlsAntPchSta "21.02.02";
BA_ "Description" SG_ 967 RCM_GlsMtrHiTempSta "Sunroof Glass Motor High Termperature Status";
BA_ "GenSigSendType" SG_ 967 RCM_GlsMtrHiTempSta 4;
BA_ "UserSigValidity" SG_ 967 RCM_GlsMtrHiTempSta 0;
BA_ "Version" SG_ 967 RCM_GlsMtrHiTempSta "21.02.02";
BA_ "Description" SG_ 967 RCM_GlsMtRunTtlTime "Sunroof Glass Motor Run Total Time";
BA_ "GenSigSendType" SG_ 967 RCM_GlsMtRunTtlTime 4;
BA_ "UserSigValidity" SG_ 967 RCM_GlsMtRunTtlTime 0;
BA_ "Version" SG_ 967 RCM_GlsMtRunTtlTime "21.02.02";
BA_ "Description" SG_ 967 RCM_GlsPosSta "Sunroof Glass Position Status";
BA_ "GenSigSendType" SG_ 967 RCM_GlsPosSta 4;
BA_ "UserSigValidity" SG_ 967 RCM_GlsPosSta 0;
BA_ "Version" SG_ 967 RCM_GlsPosSta "21.02.02";
BA_ "Description" SG_ 967 RCM_GlsFltVal "Sunroof Glass Fault Value";
BA_ "GenSigSendType" SG_ 967 RCM_GlsFltVal 4;
BA_ "UserSigValidity" SG_ 967 RCM_GlsFltVal 0;
BA_ "Version" SG_ 967 RCM_GlsFltVal "21.02.02";
BA_ "Description" SG_ 967 RCM_GlsFltSta "Sunroof Glass Fault Status";
BA_ "GenSigSendType" SG_ 967 RCM_GlsFltSta 4;
BA_ "UserSigValidity" SG_ 967 RCM_GlsFltSta 0;
BA_REL_ "GenSigTimeoutTime" BU_SG_REL_ CGW_CCU SG_ 967 RCM_GlsFltSta 1500;
BA_ "Version" SG_ 967 RCM_GlsFltSta "21.02.02";
BA_ "GenMsgSendType" BO_ 968 0;
BA_ "Description" SG_ 968 RCM_Crc3Val "The data area for CRC calculation is based on the data length (DLC) of the message DB.

The CRC shall be calculated over the entire data block (excluding the CRC bytes) including the user data, alive counter and Data ID 

 

- CRC Polynomial (0x1D) , Initial Value : 0x00, XOR value : 0xFF, Data ID Mode : Both, Data ID : Message ID + 0xF800 

- The initial value is for CRC calculation and the message should be sent with the calculated result value. 

The mathematical expression to 8 bit CRC polynomial is given here. G(x) = x8 + x4 + x3 + x2 + 1";
BA_ "GenSigSendType" SG_ 968 RCM_Crc3Val 4;
BA_ "GenSigStartValue" SG_ 968 RCM_Crc3Val 255;
BA_ "UserSigValidity" SG_ 968 RCM_Crc3Val 3;
BA_ "Version" SG_ 968 RCM_Crc3Val "21.02.01";
BA_ "Description" SG_ 968 RCM_AlvCnt3Val "For the first transmission request for a data element the counter shall be initialized with 0 and shall be incremented by 1

for every subsequent send request. When the counter reaches the maximum value(0xE), then it shall restart with 0 for the next send request";
BA_ "GenSigSendType" SG_ 968 RCM_AlvCnt3Val 4;
BA_ "UserSigValidity" SG_ 968 RCM_AlvCnt3Val 3;
BA_ "Version" SG_ 968 RCM_AlvCnt3Val "21.02.01";
BA_ "Description" SG_ 968 RCM_BldHallSnsrPlsCnt "Sunroof Blind Motor Hall Sensor Pulse Count";
BA_ "GenSigSendType" SG_ 968 RCM_BldHallSnsrPlsCnt 4;
BA_ "UserSigValidity" SG_ 968 RCM_BldHallSnsrPlsCnt 0;
BA_ "Version" SG_ 968 RCM_BldHallSnsrPlsCnt "21.02.02";
BA_ "Description" SG_ 968 RCM_BldOpSta "Sunroof Blind Operation Status";
BA_ "GenSigSendType" SG_ 968 RCM_BldOpSta 4;
BA_ "UserSigValidity" SG_ 968 RCM_BldOpSta 0;
BA_ "Version" SG_ 968 RCM_BldOpSta "21.02.02";
BA_ "Description" SG_ 968 RCM_BldInitSta "Sunroof Blind Initialization Status";
BA_ "GenSigSendType" SG_ 968 RCM_BldInitSta 4;
BA_ "UserSigValidity" SG_ 968 RCM_BldInitSta 0;
BA_ "Version" SG_ 968 RCM_BldInitSta "21.02.02";
BA_ "Description" SG_ 968 RCM_BldAntPchSta "Sunroof Blind Anti Pinch Status";
BA_ "GenSigSendType" SG_ 968 RCM_BldAntPchSta 4;
BA_ "UserSigValidity" SG_ 968 RCM_BldAntPchSta 0;
BA_ "Version" SG_ 968 RCM_BldAntPchSta "21.02.02";
BA_ "Description" SG_ 968 RCM_BldMtrHiTempSta "Sunroof Blind Motor High Termperature Status";
BA_ "GenSigSendType" SG_ 968 RCM_BldMtrHiTempSta 4;
BA_ "UserSigValidity" SG_ 968 RCM_BldMtrHiTempSta 0;
BA_ "Version" SG_ 968 RCM_BldMtrHiTempSta "21.02.02";
BA_ "Description" SG_ 968 RCM_BldMtRunTtlTime "Sunroof Blind Motor Run Total Time";
BA_ "GenSigSendType" SG_ 968 RCM_BldMtRunTtlTime 4;
BA_ "UserSigValidity" SG_ 968 RCM_BldMtRunTtlTime 0;
BA_ "Version" SG_ 968 RCM_BldMtRunTtlTime "21.02.02";
BA_ "Description" SG_ 968 RCM_BldPosSta "Sunroof Blind Position Status";
BA_ "GenSigSendType" SG_ 968 RCM_BldPosSta 4;
BA_ "UserSigValidity" SG_ 968 RCM_BldPosSta 0;
BA_REL_ "GenSigTimeoutTime" BU_SG_REL_ SGU SG_ 968 RCM_BldPosSta 1500;
BA_ "Version" SG_ 968 RCM_BldPosSta "21.02.02";
BA_ "Description" SG_ 968 RCM_BldFltVal "Sunroof Blind Fault Value";
BA_ "GenSigSendType" SG_ 968 RCM_BldFltVal 4;
BA_ "UserSigValidity" SG_ 968 RCM_BldFltVal 0;
BA_ "Version" SG_ 968 RCM_BldFltVal "21.02.02";
BA_ "Description" SG_ 968 RCM_BldFltSta "Sunroof Blind Fault Status";
BA_ "GenSigSendType" SG_ 968 RCM_BldFltSta 4;
BA_ "UserSigValidity" SG_ 968 RCM_BldFltSta 0;
BA_ "Version" SG_ 968 RCM_BldFltSta "21.02.02";
BA_ "GenMsgSendType" BO_ 2332213249 0;
BA_ "GenMsgCycleTimeFast" BO_ 2332213249 0;
BA_ "GenMsgNrOfRepetition" BO_ 2332213249 0;
BA_ "VFrameFormat" BO_ 2332213249 1;
BA_ "Description" SG_ 2332213249 VCU_Crc6Val "The data area for CRC calculation is based on the data length (DLC) of the message DB.

The CRC shall be calculated over the entire data block (excluding the CRC bytes) including the user data, alive counter and Data ID

 

- CRC Polynomial (0x1021) , Initial Value : 0xFFFF, XOR value : 0x0000, Data ID : Message ID + 0xF800 

- The initial value is for CRC calculation and the message should be sent with the calculated result value. 

- The mathematical expression to 16 bit CRC polynomial is given here. G(x) = x16 + x12 + x5 + 1";
BA_ "GenSigStartValue" SG_ 2332213249 VCU_Crc6Val 65535;
BA_ "UserSigValidity" SG_ 2332213249 VCU_Crc6Val 3;
BA_ "Version" SG_ 2332213249 VCU_Crc6Val "19.07.01";
BA_ "Description" SG_ 2332213249 VCU_AlvCnt6Val "For the first transmission request for a data element the counter shall be initialized with 0 and shall be incremented by 1 for every subsequent send request. 

When the counter reaches the maximum value(0xFF), then it shall restart with 0 for the next send request";
BA_ "UserSigValidity" SG_ 2332213249 VCU_AlvCnt6Val 3;
BA_ "Version" SG_ 2332213249 VCU_AlvCnt6Val "19.07.01";
BA_ "Description" SG_ 2332213249 VCU_Required_ADASMapMsg "Map based ADAS messages information used in VCU";
BA_ "UserSigValidity" SG_ 2332213249 VCU_Required_ADASMapMsg 7;
BA_ "Version" SG_ 2332213249 VCU_Required_ADASMapMsg "19.07.01";
BA_ "Description" SG_ 2332213249 VCU_SwVer "VCU SW Version X.XX (Bit0~3 : Development Step, Bit3~7 : Month)";
BA_ "UserSigValidity" SG_ 2332213249 VCU_SwVer 7;
BA_ "Version" SG_ 2332213249 VCU_SwVer "19.07.01";
BA_ "Description" SG_ 2332213249 VCU_PwrAutoOffInfo "Auto Power Off Activation bit";
BA_ "UserSigValidity" SG_ 2332213249 VCU_PwrAutoOffInfo 7;
BA_ "Version" SG_ 2332213249 VCU_PwrAutoOffInfo "19.12.08";
BA_ "Description" SG_ 2332213249 VCU_PwrAutoOffTimerSta "Auto Power Off Timer Setting Value";
BA_ "UserSigValidity" SG_ 2332213249 VCU_PwrAutoOffTimerSta 7;
BA_ "Version" SG_ 2332213249 VCU_PwrAutoOffTimerSta "19.12.08";
BA_ "Description" SG_ 2332213249 VCU_AutoShutOffTimerMin "0x0:Default(Timer Stop)/

0x1~0xFA:250min ~ 1min/

0xFB~0xFE:Reserved/

0xFF:Invalid";
BA_ "UserSigValidity" SG_ 2332213249 VCU_AutoShutOffTimerMin 7;
BA_ "Version" SG_ 2332213249 VCU_AutoShutOffTimerMin "19.12.08";
BA_ "GenMsgSendType" BO_ 2332213250 0;
BA_ "GenMsgCycleTimeFast" BO_ 2332213250 0;
BA_ "GenMsgNrOfRepetition" BO_ 2332213250 0;
BA_ "VFrameFormat" BO_ 2332213250 1;
BA_ "Description" SG_ 2332213250 VCU_AutoShutOffTimerSec "0x0:Default(Timer Stop)/

0x1~0x3C:60sec ~ 1sec/

0x3D~0x3E:Reserved/

0x3F:Invalid";
BA_ "UserSigValidity" SG_ 2332213250 VCU_AutoShutOffTimerSec 7;
BA_ "Version" SG_ 2332213250 VCU_AutoShutOffTimerSec "19.12.08";
BA_ "Description" SG_ 2332213250 VCU_TireSizeWrnMsgSta "Tire Size Warning Message Popup";
BA_ "UserSigValidity" SG_ 2332213250 VCU_TireSizeWrnMsgSta 7;
BA_ "Version" SG_ 2332213250 VCU_TireSizeWrnMsgSta "20.02.01";
BA_ "Description" SG_ 2332213250 VCU_FrntTqDispPcVal "Front Torque Display Percent Value";
BA_ "TimeoutValue" SG_ 2332213250 VCU_FrntTqDispPcVal "0x0";
BA_ "UserSigValidity" SG_ 2332213250 VCU_FrntTqDispPcVal 7;
BA_ "Version" SG_ 2332213250 VCU_FrntTqDispPcVal "20.02.01";
BA_ "Description" SG_ 2332213250 VCU_RearTqDispPcVal "Rear Torque Display Percent Value";
BA_ "TimeoutValue" SG_ 2332213250 VCU_RearTqDispPcVal "0x0";
BA_ "UserSigValidity" SG_ 2332213250 VCU_RearTqDispPcVal 7;
BA_ "Version" SG_ 2332213250 VCU_RearTqDispPcVal "20.02.01";
BA_ "Description" SG_ 2332213250 VCU_BstOpSta "Boost function's operating status";
BA_ "UserSigValidity" SG_ 2332213250 VCU_BstOpSta 7;
BA_REL_ "GenSigTimeoutTime" BU_SG_REL_ PSB SG_ 2332213250 VCU_BstOpSta 1500;
BA_REL_ "GenSigTimeoutTime" BU_SG_REL_ DLBCU SG_ 2332213250 VCU_BstOpSta 1500;
BA_ "Version" SG_ 2332213250 VCU_BstOpSta "20.08.05";
BA_ "Description" SG_ 2332213250 VCU_BstTimerVal "Boost function's timer value";
BA_ "UserSigValidity" SG_ 2332213250 VCU_BstTimerVal 7;
BA_REL_ "GenSigTimeoutTime" BU_SG_REL_ PSB SG_ 2332213250 VCU_BstTimerVal 1500;
BA_REL_ "GenSigTimeoutTime" BU_SG_REL_ DLBCU SG_ 2332213250 VCU_BstTimerVal 1500;
BA_ "Version" SG_ 2332213250 VCU_BstTimerVal "20.08.05";
BA_ "Description" SG_ 2332213250 VCU_BstWarnMsg "Boost function's warning message";
BA_ "UserSigValidity" SG_ 2332213250 VCU_BstWarnMsg 7;
BA_REL_ "GenSigTimeoutTime" BU_SG_REL_ PSB SG_ 2332213250 VCU_BstWarnMsg 1500;
BA_REL_ "GenSigTimeoutTime" BU_SG_REL_ DLBCU SG_ 2332213250 VCU_BstWarnMsg 1500;
BA_ "Version" SG_ 2332213250 VCU_BstWarnMsg "20.08.05";
BA_ "Description" SG_ 2332213250 VCU_BstAvailSta "Boost function's available status";
BA_ "UserSigValidity" SG_ 2332213250 VCU_BstAvailSta 7;
BA_REL_ "GenSigTimeoutTime" BU_SG_REL_ DLBCU SG_ 2332213250 VCU_BstAvailSta 1500;
BA_ "Version" SG_ 2332213250 VCU_BstAvailSta "20.09.00";
BA_ "Description" SG_ 2332213250 VCU_BstAplySta "Boost function's apply status";
BA_ "UserSigValidity" SG_ 2332213250 VCU_BstAplySta 7;
BA_REL_ "GenSigTimeoutTime" BU_SG_REL_ DLBCU SG_ 2332213250 VCU_BstAplySta 1500;
BA_ "Version" SG_ 2332213250 VCU_BstAplySta "20.10.00";
BA_ "Description" SG_ 2332213250 VCU_PwrAutoOffTimerReset "Auto Power Off Timer Reset bit";
BA_ "UserSigValidity" SG_ 2332213250 VCU_PwrAutoOffTimerReset 7;
BA_ "Version" SG_ 2332213250 VCU_PwrAutoOffTimerReset "19.12.08";
BA_ "Description" SG_ 2332213250 VCU_AutoShutOffReq "0x0~0xE:IG ON/

0xF:IG OFF";
BA_ "UserSigValidity" SG_ 2332213250 VCU_AutoShutOffReq 7;
BA_ "Version" SG_ 2332213250 VCU_AutoShutOffReq "19.12.08";
BA_ "GenMsgSendType" BO_ 2332213251 0;
BA_ "GenMsgCycleTimeFast" BO_ 2332213251 0;
BA_ "GenMsgNrOfRepetition" BO_ 2332213251 0;
BA_ "VFrameFormat" BO_ 2332213251 1;
BA_ "NmMessage" BO_ 1308 1;
BA_ "GenMsgILSupport" BO_ 1308 0;
BA_ "NWM-Botschaft" BO_ 1308 1;
BA_ "UsrSigPurpose" SG_ 1308 Destination_RLPSU 9;
BA_ "UserSigValidity" SG_ 1308 Destination_RLPSU 0;
BA_ "UsrSigPurpose" SG_ 1308 NMCommandCode_RLPSU 9;
BA_ "UserSigValidity" SG_ 1308 NMCommandCode_RLPSU 0;
BA_ "UsrSigPurpose" SG_ 1308 NMSleepFlag_RLPSU 9;
BA_ "UserSigValidity" SG_ 1308 NMSleepFlag_RLPSU 0;
BA_ "NmMessage" BO_ 1336 1;
BA_ "GenMsgILSupport" BO_ 1336 0;
BA_ "NWM-Botschaft" BO_ 1336 1;
BA_ "UsrSigPurpose" SG_ 1336 Destination_DPSU 9;
BA_ "UserSigValidity" SG_ 1336 Destination_DPSU 0;
BA_ "UsrSigPurpose" SG_ 1336 NMCommandCode_DPSU 9;
BA_ "UserSigValidity" SG_ 1336 NMCommandCode_DPSU 0;
BA_ "UsrSigPurpose" SG_ 1336 NMSleepFlag_DPSU 9;
BA_ "UserSigValidity" SG_ 1336 NMSleepFlag_DPSU 0;
BA_ "NmMessage" BO_ 1329 1;
BA_ "GenMsgILSupport" BO_ 1329 0;
BA_ "NWM-Botschaft" BO_ 1329 1;
BA_ "UsrSigPurpose" SG_ 1329 Destination_APSU 9;
BA_ "UserSigValidity" SG_ 1329 Destination_APSU 0;
BA_ "UsrSigPurpose" SG_ 1329 NMCommandCode_APSU 9;
BA_ "UserSigValidity" SG_ 1329 NMCommandCode_APSU 0;
BA_ "UsrSigPurpose" SG_ 1329 NMSleepFlag_APSU 9;
BA_ "UserSigValidity" SG_ 1329 NMSleepFlag_APSU 0;
BA_ "NmMessage" BO_ 1345 1;
BA_ "GenMsgILSupport" BO_ 1345 0;
BA_ "NWM-Botschaft" BO_ 1345 1;
BA_ "UsrSigPurpose" SG_ 1345 Destination_PSB 9;
BA_ "UserSigValidity" SG_ 1345 Destination_PSB 0;
BA_ "UsrSigPurpose" SG_ 1345 NMCommandCode_PSB 9;
BA_ "UserSigValidity" SG_ 1345 NMCommandCode_PSB 0;
BA_ "UsrSigPurpose" SG_ 1345 NMSleepFlag_PSB 9;
BA_ "UserSigValidity" SG_ 1345 NMSleepFlag_PSB 0;
BA_ "NmMessage" BO_ 1323 1;
BA_ "GenMsgILSupport" BO_ 1323 0;
BA_ "NWM-Botschaft" BO_ 1323 1;
BA_ "UsrSigPurpose" SG_ 1323 Destination_SHVU_RR 9;
BA_ "UserSigValidity" SG_ 1323 Destination_SHVU_RR 0;
BA_ "UsrSigPurpose" SG_ 1323 NMCommandCode_SHVU_RR 9;
BA_ "UserSigValidity" SG_ 1323 NMCommandCode_SHVU_RR 0;
BA_ "UsrSigPurpose" SG_ 1323 NMSleepFlag_SHVU_RR 9;
BA_ "UserSigValidity" SG_ 1323 NMSleepFlag_SHVU_RR 0;
BA_ "NmMessage" BO_ 1313 1;
BA_ "GenMsgILSupport" BO_ 1313 0;
BA_ "NWM-Botschaft" BO_ 1313 1;
BA_ "UsrSigPurpose" SG_ 1313 Destination_FCS 9;
BA_ "UserSigValidity" SG_ 1313 Destination_FCS 0;
BA_ "UsrSigPurpose" SG_ 1313 NMCommandCode_FCS 9;
BA_ "UserSigValidity" SG_ 1313 NMCommandCode_FCS 0;
BA_ "UsrSigPurpose" SG_ 1313 NMSleepFlag_FCS 9;
BA_ "UserSigValidity" SG_ 1313 NMSleepFlag_FCS 0;
BA_ "NmMessage" BO_ 1297 1;
BA_ "GenMsgILSupport" BO_ 1297 0;
BA_ "NWM-Botschaft" BO_ 1297 1;
BA_ "UsrSigPurpose" SG_ 1297 Destination_EMCU 9;
BA_ "UserSigValidity" SG_ 1297 Destination_EMCU 0;
BA_ "UsrSigPurpose" SG_ 1297 NMCommandCode_EMCU 9;
BA_ "UserSigValidity" SG_ 1297 NMCommandCode_EMCU 0;
BA_ "UsrSigPurpose" SG_ 1297 NMSleepFlag_EMCU 9;
BA_ "UserSigValidity" SG_ 1297 NMSleepFlag_EMCU 0;
BA_ "NmMessage" BO_ 1307 1;
BA_ "GenMsgILSupport" BO_ 1307 0;
BA_ "NWM-Botschaft" BO_ 1307 1;
BA_ "UsrSigPurpose" SG_ 1307 Destination_SLB 9;
BA_ "UserSigValidity" SG_ 1307 Destination_SLB 0;
BA_ "UsrSigPurpose" SG_ 1307 NMCommandCode_SLB 9;
BA_ "UserSigValidity" SG_ 1307 NMCommandCode_SLB 0;
BA_ "UsrSigPurpose" SG_ 1307 NMSleepFlag_SLB 9;
BA_ "UserSigValidity" SG_ 1307 NMSleepFlag_SLB 0;
BA_ "NmMessage" BO_ 1341 1;
BA_ "GenMsgILSupport" BO_ 1341 0;
BA_ "NWM-Botschaft" BO_ 1341 1;
BA_ "UsrSigPurpose" SG_ 1341 Destination_RCM 9;
BA_ "UserSigValidity" SG_ 1341 Destination_RCM 0;
BA_ "UsrSigPurpose" SG_ 1341 NMCommandCode_RCM 9;
BA_ "UserSigValidity" SG_ 1341 NMCommandCode_RCM 0;
BA_ "UsrSigPurpose" SG_ 1341 NMSleepFlag_RCM 9;
BA_ "UserSigValidity" SG_ 1341 NMSleepFlag_RCM 0;
BA_ "NmMessage" BO_ 1392 1;
BA_ "GenMsgILSupport" BO_ 1392 0;
BA_ "NWM-Botschaft" BO_ 1392 1;
BA_ "UsrSigPurpose" SG_ 1392 Destination_CGW_CCU 9;
BA_ "UserSigValidity" SG_ 1392 Destination_CGW_CCU 0;
BA_ "UsrSigPurpose" SG_ 1392 NMCommandCode_CGW_CCU 9;
BA_ "UserSigValidity" SG_ 1392 NMCommandCode_CGW_CCU 0;
BA_ "UsrSigPurpose" SG_ 1392 NMSleepFlag_CGW_CCU 9;
BA_ "UserSigValidity" SG_ 1392 NMSleepFlag_CGW_CCU 0;
BA_ "NmMessage" BO_ 1360 1;
BA_ "GenMsgILSupport" BO_ 1360 0;
BA_ "NWM-Botschaft" BO_ 1360 1;
BA_ "UsrSigPurpose" SG_ 1360 Destination_ATS 9;
BA_ "UserSigValidity" SG_ 1360 Destination_ATS 0;
BA_ "UsrSigPurpose" SG_ 1360 NMCommandCode_ATS 9;
BA_ "UserSigValidity" SG_ 1360 NMCommandCode_ATS 0;
BA_ "UsrSigPurpose" SG_ 1360 NMSleepFlag_ATS 9;
BA_ "UserSigValidity" SG_ 1360 NMSleepFlag_ATS 0;
BA_ "NmMessage" BO_ 1332 1;
BA_ "GenMsgILSupport" BO_ 1332 0;
BA_ "NWM-Botschaft" BO_ 1332 1;
BA_ "UsrSigPurpose" SG_ 1332 Destination_RLHV 9;
BA_ "UserSigValidity" SG_ 1332 Destination_RLHV 0;
BA_ "UsrSigPurpose" SG_ 1332 NMCommandCode_RLHV 9;
BA_ "UserSigValidity" SG_ 1332 NMCommandCode_RLHV 0;
BA_ "UsrSigPurpose" SG_ 1332 NMSleepFlag_RLHV 9;
BA_ "UserSigValidity" SG_ 1332 NMSleepFlag_RLHV 0;
BA_ "NmMessage" BO_ 1325 1;
BA_ "GenMsgILSupport" BO_ 1325 0;
BA_ "NWM-Botschaft" BO_ 1325 1;
BA_ "UsrSigPurpose" SG_ 1325 Destination_PFSU 9;
BA_ "UserSigValidity" SG_ 1325 Destination_PFSU 0;
BA_ "UsrSigPurpose" SG_ 1325 NMCommandCode_PFSU 9;
BA_ "UserSigValidity" SG_ 1325 NMCommandCode_PFSU 0;
BA_ "UsrSigPurpose" SG_ 1325 NMSleepFlag_PFSU 9;
BA_ "UserSigValidity" SG_ 1325 NMSleepFlag_PFSU 0;
BA_ "NmMessage" BO_ 1342 1;
BA_ "GenMsgILSupport" BO_ 1342 0;
BA_ "NWM-Botschaft" BO_ 1342 1;
BA_ "UsrSigPurpose" SG_ 1342 Destination_SGU 9;
BA_ "UserSigValidity" SG_ 1342 Destination_SGU 0;
BA_ "UsrSigPurpose" SG_ 1342 NMCommandCode_SGU 9;
BA_ "UserSigValidity" SG_ 1342 NMCommandCode_SGU 0;
BA_ "UsrSigPurpose" SG_ 1342 NMSleepFlag_SGU 9;
BA_ "UserSigValidity" SG_ 1342 NMSleepFlag_SGU 0;
BA_ "NmMessage" BO_ 1348 1;
BA_ "GenMsgILSupport" BO_ 1348 0;
BA_ "NWM-Botschaft" BO_ 1348 1;
BA_ "UsrSigPurpose" SG_ 1348 Destination_ALBCU 9;
BA_ "UserSigValidity" SG_ 1348 Destination_ALBCU 0;
BA_ "UsrSigPurpose" SG_ 1348 NMCommandCode_ALBCU 9;
BA_ "UserSigValidity" SG_ 1348 NMCommandCode_ALBCU 0;
BA_ "UsrSigPurpose" SG_ 1348 NMSleepFlag_ALBCU 9;
BA_ "UserSigValidity" SG_ 1348 NMSleepFlag_ALBCU 0;
BA_ "NmMessage" BO_ 1369 1;
BA_ "GenMsgILSupport" BO_ 1369 0;
BA_ "NWM-Botschaft" BO_ 1369 1;
BA_ "UsrSigPurpose" SG_ 1369 Destination_DSAU 9;
BA_ "UserSigValidity" SG_ 1369 Destination_DSAU 0;
BA_ "UsrSigPurpose" SG_ 1369 NMCommandCode_DSAU 9;
BA_ "UserSigValidity" SG_ 1369 NMCommandCode_DSAU 0;
BA_ "UsrSigPurpose" SG_ 1369 NMSleepFlag_DSAU 9;
BA_ "UserSigValidity" SG_ 1369 NMSleepFlag_DSAU 0;
BA_ "NmMessage" BO_ 1288 1;
BA_ "GenMsgILSupport" BO_ 1288 0;
BA_ "NWM-Botschaft" BO_ 1288 1;
BA_ "UsrSigPurpose" SG_ 1288 Destination_SWRC 9;
BA_ "UserSigValidity" SG_ 1288 Destination_SWRC 0;
BA_ "UsrSigPurpose" SG_ 1288 NMCommandCode_SWRC 9;
BA_ "UserSigValidity" SG_ 1288 NMCommandCode_SWRC 0;
BA_ "UsrSigPurpose" SG_ 1288 NMSleepFlag_SWRC 9;
BA_ "UserSigValidity" SG_ 1288 NMSleepFlag_SWRC 0;
BA_ "NmMessage" BO_ 1322 1;
BA_ "GenMsgILSupport" BO_ 1322 0;
BA_ "NWM-Botschaft" BO_ 1322 1;
BA_ "UsrSigPurpose" SG_ 1322 Destination_SHVU_FR 9;
BA_ "UserSigValidity" SG_ 1322 Destination_SHVU_FR 0;
BA_ "UsrSigPurpose" SG_ 1322 NMCommandCode_SHVU_FR 9;
BA_ "UserSigValidity" SG_ 1322 NMCommandCode_SHVU_FR 0;
BA_ "UsrSigPurpose" SG_ 1322 NMSleepFlag_SHVU_FR 9;
BA_ "UserSigValidity" SG_ 1322 NMSleepFlag_SHVU_FR 0;
BA_ "NmMessage" BO_ 1350 1;
BA_ "GenMsgILSupport" BO_ 1350 0;
BA_ "NWM-Botschaft" BO_ 1350 1;
BA_ "UsrSigPurpose" SG_ 1350 Destination_RCS 9;
BA_ "UserSigValidity" SG_ 1350 Destination_RCS 0;
BA_ "UsrSigPurpose" SG_ 1350 NMCommandCode_RCS 9;
BA_ "UserSigValidity" SG_ 1350 NMCommandCode_RCS 0;
BA_ "UsrSigPurpose" SG_ 1350 NMSleepFlag_RCS 9;
BA_ "UserSigValidity" SG_ 1350 NMSleepFlag_RCS 0;
BA_ "NmMessage" BO_ 1309 1;
BA_ "GenMsgILSupport" BO_ 1309 0;
BA_ "NWM-Botschaft" BO_ 1309 1;
BA_ "UsrSigPurpose" SG_ 1309 Destination_RRPSU 9;
BA_ "UserSigValidity" SG_ 1309 Destination_RRPSU 0;
BA_ "UsrSigPurpose" SG_ 1309 NMCommandCode_RRPSU 9;
BA_ "UserSigValidity" SG_ 1309 NMCommandCode_RRPSU 0;
BA_ "UsrSigPurpose" SG_ 1309 NMSleepFlag_RRPSU 9;
BA_ "UserSigValidity" SG_ 1309 NMSleepFlag_RRPSU 0;
BA_ "NmMessage" BO_ 1352 1;
BA_ "GenMsgILSupport" BO_ 1352 0;
BA_ "NWM-Botschaft" BO_ 1352 1;
BA_ "UsrSigPurpose" SG_ 1352 Destination_BLTN_CAM 9;
BA_ "UserSigValidity" SG_ 1352 Destination_BLTN_CAM 0;
BA_ "UsrSigPurpose" SG_ 1352 NMCommandCode_BLTN_CAM 9;
BA_ "UserSigValidity" SG_ 1352 NMCommandCode_BLTN_CAM 0;
BA_ "UsrSigPurpose" SG_ 1352 NMSleepFlag_BLTN_CAM 9;
BA_ "UserSigValidity" SG_ 1352 NMSleepFlag_BLTN_CAM 0;
BA_ "NmMessage" BO_ 1287 1;
BA_ "GenMsgILSupport" BO_ 1287 0;
BA_ "NWM-Botschaft" BO_ 1287 1;
BA_ "UsrSigPurpose" SG_ 1287 Destination_SCM 9;
BA_ "UserSigValidity" SG_ 1287 Destination_SCM 0;
BA_ "UsrSigPurpose" SG_ 1287 NMCommandCode_SCM 9;
BA_ "UserSigValidity" SG_ 1287 NMCommandCode_SCM 0;
BA_ "UsrSigPurpose" SG_ 1287 NMSleepFlag_SCM 9;
BA_ "UserSigValidity" SG_ 1287 NMSleepFlag_SCM 0;
BA_ "NmMessage" BO_ 1344 1;
BA_ "GenMsgILSupport" BO_ 1344 0;
BA_ "NWM-Botschaft" BO_ 1344 1;
BA_ "UsrSigPurpose" SG_ 1344 Destination_DLBCU 9;
BA_ "UserSigValidity" SG_ 1344 Destination_DLBCU 0;
BA_ "UsrSigPurpose" SG_ 1344 NMCommandCode_DLBCU 9;
BA_ "UserSigValidity" SG_ 1344 NMCommandCode_DLBCU 0;
BA_ "UsrSigPurpose" SG_ 1344 NMSleepFlag_DLBCU 9;
BA_ "UserSigValidity" SG_ 1344 NMSleepFlag_DLBCU 0;
BA_ "NmMessage" BO_ 1364 1;
BA_ "GenMsgILSupport" BO_ 1364 0;
BA_ "NWM-Botschaft" BO_ 1364 1;
BA_ "UsrSigPurpose" SG_ 1364 Destination_OHCL 9;
BA_ "UserSigValidity" SG_ 1364 Destination_OHCL 0;
BA_ "UsrSigPurpose" SG_ 1364 NMCommandCode_OHCL 9;
BA_ "UserSigValidity" SG_ 1364 NMCommandCode_OHCL 0;
BA_ "UsrSigPurpose" SG_ 1364 NMSleepFlag_OHCL 9;
BA_ "UserSigValidity" SG_ 1364 NMSleepFlag_OHCL 0;
BA_ "NmMessage" BO_ 1311 1;
BA_ "GenMsgILSupport" BO_ 1311 0;
BA_ "NWM-Botschaft" BO_ 1311 1;
BA_ "UsrSigPurpose" SG_ 1311 Destination_RWPC 9;
BA_ "UserSigValidity" SG_ 1311 Destination_RWPC 0;
BA_ "UsrSigPurpose" SG_ 1311 NMCommandCode_RWPC 9;
BA_ "UserSigValidity" SG_ 1311 NMCommandCode_RWPC 0;
BA_ "UsrSigPurpose" SG_ 1311 NMSleepFlag_RWPC 9;
BA_ "UserSigValidity" SG_ 1311 NMSleepFlag_RWPC 0;
BA_ "NmMessage" BO_ 1333 1;
BA_ "GenMsgILSupport" BO_ 1333 0;
BA_ "NWM-Botschaft" BO_ 1333 1;
BA_ "UsrSigPurpose" SG_ 1333 Destination_RRHV 9;
BA_ "UserSigValidity" SG_ 1333 Destination_RRHV 0;
BA_ "UsrSigPurpose" SG_ 1333 NMCommandCode_RRHV 9;
BA_ "UserSigValidity" SG_ 1333 NMCommandCode_RRHV 0;
BA_ "UsrSigPurpose" SG_ 1333 NMSleepFlag_RRHV 9;
BA_ "UserSigValidity" SG_ 1333 NMSleepFlag_RRHV 0;
BA_ "NmMessage" BO_ 1310 1;
BA_ "GenMsgILSupport" BO_ 1310 0;
BA_ "NWM-Botschaft" BO_ 1310 1;
BA_ "UsrSigPurpose" SG_ 1310 Destination_WPC 9;
BA_ "UserSigValidity" SG_ 1310 Destination_WPC 0;
BA_ "UsrSigPurpose" SG_ 1310 NMCommandCode_WPC 9;
BA_ "UserSigValidity" SG_ 1310 NMCommandCode_WPC 0;
BA_ "UsrSigPurpose" SG_ 1310 NMSleepFlag_WPC 9;
BA_ "UserSigValidity" SG_ 1310 NMSleepFlag_WPC 0;
BA_ "NmMessage" BO_ 1354 1;
BA_ "GenMsgILSupport" BO_ 1354 0;
BA_ "NWM-Botschaft" BO_ 1354 1;
BA_ "UsrSigPurpose" SG_ 1354 Destination_HOD 9;
BA_ "UserSigValidity" SG_ 1354 Destination_HOD 0;
BA_ "UsrSigPurpose" SG_ 1354 NMCommandCode_HOD 9;
BA_ "UserSigValidity" SG_ 1354 NMCommandCode_HOD 0;
BA_ "UsrSigPurpose" SG_ 1354 NMSleepFlag_HOD 9;
BA_ "UserSigValidity" SG_ 1354 NMSleepFlag_HOD 0;
BA_ "NmMessage" BO_ 1363 1;
BA_ "GenMsgILSupport" BO_ 1363 0;
BA_ "NWM-Botschaft" BO_ 1363 1;
BA_ "UsrSigPurpose" SG_ 1363 Destination_ASAU 9;
BA_ "UserSigValidity" SG_ 1363 Destination_ASAU 0;
BA_ "UsrSigPurpose" SG_ 1363 NMCommandCode_ASAU 9;
BA_ "UserSigValidity" SG_ 1363 NMCommandCode_ASAU 0;
BA_ "UsrSigPurpose" SG_ 1363 NMSleepFlag_ASAU 9;
BA_ "UserSigValidity" SG_ 1363 NMSleepFlag_ASAU 0;
VAL_ 2151682049 ACU_CrshActvSta 0 "Crash Active time is expired (Crash is Inactive)" 1 "Crash Active time started (Crash Detected)" 2 "Not used" 3 "Error Indicator" ;
VAL_ 2151682049 ACU_CrshInfo 0 "Received ESC feedback signal" 1 "Crash output signal not issued" 2 "Crash output signal issued" ;
VAL_ 981 APSS_StExtFwdMvBtn 0 "Default" 1 "Off" 2 "On" 3 "Invalid" ;
VAL_ 981 APSS_StSldFwdMvBtn 0 "Default" 1 "Off" 2 "On" 3 "Invalid" ;
VAL_ 981 APSS_StSldBwdMvBtn 0 "Default" 1 "Off" 2 "On" 3 "Invalid" ;
VAL_ 981 APSS_StExtBwdMvBtn 0 "Default" 1 "Off" 2 "On" 3 "Invaild" ;
VAL_ 981 APSS_StRclFwdMvBtn 0 "Default" 1 "Off" 2 "On" 3 "Invalid" ;
VAL_ 981 APSS_StRclBwdMvBtn 0 "Default" 1 "Off" 2 "On" 3 "Invalid" ;
VAL_ 981 APSS_StHgtUpMvBtn 0 "Default" 1 "Off" 2 "On" 3 "Invalid" ;
VAL_ 981 APSS_StHgtDnMvBtn 0 "Default" 1 "Off" 2 "On" 3 "Invalid" ;
VAL_ 981 APSS_StTltUpMvBtn 0 "Default" 1 "Off" 2 "On" 3 "Invalid" ;
VAL_ 981 APSS_StTltDnMvBtn 0 "Default" 1 "Off" 2 "On" 3 "Invalid" ;
VAL_ 981 APSS_StHRestUpMvBtn 0 "Default" 1 "Off" 2 "On" 3 "Invalid" ;
VAL_ 981 APSS_StHRestDnMvBtn 0 "Default" 1 "Off" 2 "On" 3 "Invalid" ;
VAL_ 981 APSS_StHRestFwdMvBtn 0 "Default" 1 "Off" 2 "On" 3 "Invalid" ;
VAL_ 981 APSS_StHRestBwdMvBtn 0 "Default" 1 "Off" 2 "On" 3 "Invalid" ;
VAL_ 981 APSS_StLegUpMvBtn 0 "Default" 1 "Off" 2 "On" 3 "Invalid" ;
VAL_ 981 APSS_StLegDnMvBtn 0 "Default" 1 "Off" 2 "On" 3 "Invalid" ;
VAL_ 981 APSS_StRlxModeBtn 0 "Default" 1 "Off" 2 "On" 3 "Invalid" ;
VAL_ 981 APSS_StRlxReturnBtn 0 "Default" 1 "Off" 2 "On" 3 "Invalid" ;
VAL_ 981 APSS_StRlxTltUpMvBtn 0 "Default" 1 "Off" 2 "On" 3 "Invalid" ;
VAL_ 981 APSS_StRlxTltDnMvBtn 0 "Default" 1 "Off" 2 "On" 3 "Invalid" ;
VAL_ 963 IBU_SWVerMajor1 0 "0x0x0~0x7F:ASCII Code Value (HEX)" 127 "0x0x0~0x7F:ASCII Code Value (HEX)" ;
VAL_ 963 IBU_SWVerMinor1 0 "0x0x0~0x7F:ASCII Code Value (HEX)" 127 "0x0x0~0x7F:ASCII Code Value (HEX)" ;
VAL_ 963 IBU_SWVerMinor2 0 "0x0x0~0x7F:ASCII Code Value (HEX)" 127 "0x0x0~0x7F:ASCII Code Value (HEX)" ;
VAL_ 963 ECW_Fault 0 "Else" 1 "Detected" 2 "Not used" 3 "Error Indicator" ;
VAL_ 963 ECW_FaultActv 0 "Else" 1 "Valid" 2 "Not used" 3 "Error Indicator" ;
VAL_ 963 ECW_HiVolt 0 "Else" 1 "Detected" 2 "Not used" 3 "Error Indicator" ;
VAL_ 963 ECW_HiVoltActv 0 "Else" 1 "Valid" 2 "Not used" 3 "Error Indicator" ;
VAL_ 963 ECW_LoVolt 0 "Else" 1 "Detected" 2 "Not used" 3 "Error Indicator" ;
VAL_ 963 ECW_LoVoltActv 0 "Else" 1 "Valid" 2 "Not used" 3 "Error Indicator" ;
VAL_ 963 ECW_Overload 0 "Else" 1 "Detected" 2 "Not used" 3 "Error Indicator" ;
VAL_ 963 ECW_OverloadActv 0 "Else" 1 "Valid" 2 "Not used" 3 "Error Indicator" ;
VAL_ 963 ECW_CommErr 0 "No error" 1 "Error" 2 "Not used" 3 "Error Indicator" ;
VAL_ 963 SunRoof_RearBlindOprSta 0 "No Action" 1 "FullOpen" 2 "FullClose" 3 "PartiallyOpen" 4 "Opening" 5 "Closing" 6 "Reserved" 7 "Reserved" 8 "Reserved" 9 "Reserved" 10 "Reserved" 11 "Reserved" 12 "Reserved" 13 "Reserved" 14 "Reserved" 15 "Invalid" ;
VAL_ 983 BLTN_CAM_SWVerMajor 0 "ASCII Code Value (HEX)" 1 "ASCII Code Value (HEX)" 2 "ASCII Code Value (HEX)" 3 "ASCII Code Value (HEX)" 4 "ASCII Code Value (HEX)" 5 "ASCII Code Value (HEX)" 6 "ASCII Code Value (HEX)" 7 "ASCII Code Value (HEX)" 8 "ASCII Code Value (HEX)" 9 "ASCII Code Value (HEX)" 10 "ASCII Code Value (HEX)" 11 "ASCII Code Value (HEX)" 12 "ASCII Code Value (HEX)" 13 "ASCII Code Value (HEX)" 14 "ASCII Code Value (HEX)" 15 "ASCII Code Value (HEX)" ;
VAL_ 983 BLTN_CAM_SWVerMinor2 0 "Minor2 verion, 0~99 dec" 1 "Minor2 verion, 0~99 dec" 2 "Minor2 verion, 0~99 dec" 3 "Minor2 verion, 0~99 dec" 4 "Minor2 verion, 0~99 dec" 5 "Minor2 verion, 0~99 dec" 6 "Minor2 verion, 0~99 dec" 7 "Minor2 verion, 0~99 dec" 8 "Minor2 verion, 0~99 dec" 9 "Minor2 verion, 0~99 dec" 10 "Minor2 verion, 0~99 dec" 11 "Minor2 verion, 0~99 dec" 12 "Minor2 verion, 0~99 dec" 13 "Minor2 verion, 0~99 dec" 14 "Minor2 verion, 0~99 dec" 15 "Minor2 verion, 0~99 dec" 16 "Minor2 verion, 0~99 dec" 17 "Minor2 verion, 0~99 dec" 18 "Minor2 verion, 0~99 dec" 19 "Minor2 verion, 0~99 dec" 20 "Minor2 verion, 0~99 dec" 21 "Minor2 verion, 0~99 dec" 22 "Minor2 verion, 0~99 dec" 23 "Minor2 verion, 0~99 dec" 24 "Minor2 verion, 0~99 dec" 25 "Minor2 verion, 0~99 dec" 26 "Minor2 verion, 0~99 dec" 27 "Minor2 verion, 0~99 dec" 28 "Minor2 verion, 0~99 dec" 29 "Minor2 verion, 0~99 dec" 30 "Minor2 verion, 0~99 dec" 31 "Minor2 verion, 0~99 dec" 32 "Minor2 verion, 0~99 dec" 33 "Minor2 verion, 0~99 dec" 34 "Minor2 verion, 0~99 dec" 35 "Minor2 verion, 0~99 dec" 36 "Minor2 verion, 0~99 dec" 37 "Minor2 verion, 0~99 dec" 38 "Minor2 verion, 0~99 dec" 39 "Minor2 verion, 0~99 dec" 40 "Minor2 verion, 0~99 dec" 41 "Minor2 verion, 0~99 dec" 42 "Minor2 verion, 0~99 dec" 43 "Minor2 verion, 0~99 dec" 44 "Minor2 verion, 0~99 dec" 45 "Minor2 verion, 0~99 dec" 46 "Minor2 verion, 0~99 dec" 47 "Minor2 verion, 0~99 dec" 48 "Minor2 verion, 0~99 dec" 49 "Minor2 verion, 0~99 dec" 50 "Minor2 verion, 0~99 dec" 51 "Minor2 verion, 0~99 dec" 52 "Minor2 verion, 0~99 dec" 53 "Minor2 verion, 0~99 dec" 54 "Minor2 verion, 0~99 dec" 55 "Minor2 verion, 0~99 dec" 56 "Minor2 verion, 0~99 dec" 57 "Minor2 verion, 0~99 dec" 58 "Minor2 verion, 0~99 dec" 59 "Minor2 verion, 0~99 dec" 60 "Minor2 verion, 0~99 dec" 61 "Minor2 verion, 0~99 dec" 62 "Minor2 verion, 0~99 dec" 63 "Minor2 verion, 0~99 dec" 64 "Minor2 verion, 0~99 dec" 65 "Minor2 verion, 0~99 dec" 66 "Minor2 verion, 0~99 dec" 67 "Minor2 verion, 0~99 dec" 68 "Minor2 verion, 0~99 dec" 69 "Minor2 verion, 0~99 dec" 70 "Minor2 verion, 0~99 dec" 71 "Minor2 verion, 0~99 dec" 72 "Minor2 verion, 0~99 dec" 73 "Minor2 verion, 0~99 dec" 74 "Minor2 verion, 0~99 dec" 75 "Minor2 verion, 0~99 dec" 76 "Minor2 verion, 0~99 dec" 77 "Minor2 verion, 0~99 dec" 78 "Minor2 verion, 0~99 dec" 79 "Minor2 verion, 0~99 dec" 80 "Minor2 verion, 0~99 dec" 81 "Minor2 verion, 0~99 dec" 82 "Minor2 verion, 0~99 dec" 83 "Minor2 verion, 0~99 dec" 84 "Minor2 verion, 0~99 dec" 85 "Minor2 verion, 0~99 dec" 86 "Minor2 verion, 0~99 dec" 87 "Minor2 verion, 0~99 dec" 88 "Minor2 verion, 0~99 dec" 89 "Minor2 verion, 0~99 dec" 90 "Minor2 verion, 0~99 dec" 91 "Minor2 verion, 0~99 dec" 92 "Minor2 verion, 0~99 dec" 93 "Minor2 verion, 0~99 dec" 94 "Minor2 verion, 0~99 dec" 95 "Minor2 verion, 0~99 dec" 96 "Minor2 verion, 0~99 dec" 97 "Minor2 verion, 0~99 dec" 98 "Minor2 verion, 0~99 dec" 99 "Minor2 verion, 0~99 dec" 100 "Reserved" 101 "Reserved" 102 "Reserved" 103 "Reserved" 104 "Reserved" 105 "Reserved" 106 "Reserved" 107 "Reserved" 108 "Reserved" 109 "Reserved" 110 "Reserved" 111 "Reserved" 112 "Reserved" 113 "Reserved" 114 "Reserved" 115 "Reserved" 116 "Reserved" 117 "Reserved" 118 "Reserved" 119 "Reserved" 120 "Reserved" 121 "Reserved" 122 "Reserved" 123 "Reserved" 124 "Reserved" 125 "Reserved" 126 "Reserved" 127 "Invalid" ;
VAL_ 983 BLTN_CAM_SWVerMinor3 0 "Minor3 version, 0~99 dec" 1 "Minor3 version, 0~99 dec" 2 "Minor3 version, 0~99 dec" 3 "Minor3 version, 0~99 dec" 4 "Minor3 version, 0~99 dec" 5 "Minor3 version, 0~99 dec" 6 "Minor3 version, 0~99 dec" 7 "Minor3 version, 0~99 dec" 8 "Minor3 version, 0~99 dec" 9 "Minor3 version, 0~99 dec" 10 "Minor3 version, 0~99 dec" 11 "Minor3 version, 0~99 dec" 12 "Minor3 version, 0~99 dec" 13 "Minor3 version, 0~99 dec" 14 "Minor3 version, 0~99 dec" 15 "Minor3 version, 0~99 dec" 16 "Minor3 version, 0~99 dec" 17 "Minor3 version, 0~99 dec" 18 "Minor3 version, 0~99 dec" 19 "Minor3 version, 0~99 dec" 20 "Minor3 version, 0~99 dec" 21 "Minor3 version, 0~99 dec" 22 "Minor3 version, 0~99 dec" 23 "Minor3 version, 0~99 dec" 24 "Minor3 version, 0~99 dec" 25 "Minor3 version, 0~99 dec" 26 "Minor3 version, 0~99 dec" 27 "Minor3 version, 0~99 dec" 28 "Minor3 version, 0~99 dec" 29 "Minor3 version, 0~99 dec" 30 "Minor3 version, 0~99 dec" 31 "Minor3 version, 0~99 dec" 32 "Minor3 version, 0~99 dec" 33 "Minor3 version, 0~99 dec" 34 "Minor3 version, 0~99 dec" 35 "Minor3 version, 0~99 dec" 36 "Minor3 version, 0~99 dec" 37 "Minor3 version, 0~99 dec" 38 "Minor3 version, 0~99 dec" 39 "Minor3 version, 0~99 dec" 40 "Minor3 version, 0~99 dec" 41 "Minor3 version, 0~99 dec" 42 "Minor3 version, 0~99 dec" 43 "Minor3 version, 0~99 dec" 44 "Minor3 version, 0~99 dec" 45 "Minor3 version, 0~99 dec" 46 "Minor3 version, 0~99 dec" 47 "Minor3 version, 0~99 dec" 48 "Minor3 version, 0~99 dec" 49 "Minor3 version, 0~99 dec" 50 "Minor3 version, 0~99 dec" 51 "Minor3 version, 0~99 dec" 52 "Minor3 version, 0~99 dec" 53 "Minor3 version, 0~99 dec" 54 "Minor3 version, 0~99 dec" 55 "Minor3 version, 0~99 dec" 56 "Minor3 version, 0~99 dec" 57 "Minor3 version, 0~99 dec" 58 "Minor3 version, 0~99 dec" 59 "Minor3 version, 0~99 dec" 60 "Minor3 version, 0~99 dec" 61 "Minor3 version, 0~99 dec" 62 "Minor3 version, 0~99 dec" 63 "Minor3 version, 0~99 dec" 64 "Minor3 version, 0~99 dec" 65 "Minor3 version, 0~99 dec" 66 "Minor3 version, 0~99 dec" 67 "Minor3 version, 0~99 dec" 68 "Minor3 version, 0~99 dec" 69 "Minor3 version, 0~99 dec" 70 "Minor3 version, 0~99 dec" 71 "Minor3 version, 0~99 dec" 72 "Minor3 version, 0~99 dec" 73 "Minor3 version, 0~99 dec" 74 "Minor3 version, 0~99 dec" 75 "Minor3 version, 0~99 dec" 76 "Minor3 version, 0~99 dec" 77 "Minor3 version, 0~99 dec" 78 "Minor3 version, 0~99 dec" 79 "Minor3 version, 0~99 dec" 80 "Minor3 version, 0~99 dec" 81 "Minor3 version, 0~99 dec" 82 "Minor3 version, 0~99 dec" 83 "Minor3 version, 0~99 dec" 84 "Minor3 version, 0~99 dec" 85 "Minor3 version, 0~99 dec" 86 "Minor3 version, 0~99 dec" 87 "Minor3 version, 0~99 dec" 88 "Minor3 version, 0~99 dec" 89 "Minor3 version, 0~99 dec" 90 "Minor3 version, 0~99 dec" 91 "Minor3 version, 0~99 dec" 92 "Minor3 version, 0~99 dec" 93 "Minor3 version, 0~99 dec" 94 "Minor3 version, 0~99 dec" 95 "Minor3 version, 0~99 dec" 96 "Minor3 version, 0~99 dec" 97 "Minor3 version, 0~99 dec" 98 "Minor3 version, 0~99 dec" 99 "Minor3 version, 0~99 dec" 100 "Reserved" 101 "Reserved" 102 "Reserved" 103 "Reserved" 104 "Reserved" 105 "Reserved" 106 "Reserved" 107 "Reserved" 108 "Reserved" 109 "Reserved" 110 "Reserved" 111 "Reserved" 112 "Reserved" 113 "Reserved" 114 "Reserved" 115 "Reserved" 116 "Reserved" 117 "Reserved" 118 "Reserved" 119 "Reserved" 120 "Reserved" 121 "Reserved" 122 "Reserved" 123 "Reserved" 124 "Reserved" 125 "Reserved" 126 "Reserved" 127 "Invalid" ;
VAL_ 983 BLTN_CAM_SWVerMinor1 0 "Minor1 version, 0~99 dec" 1 "Minor1 version, 0~99 dec" 2 "Minor1 version, 0~99 dec" 3 "Minor1 version, 0~99 dec" 4 "Minor1 version, 0~99 dec" 5 "Minor1 version, 0~99 dec" 6 "Minor1 version, 0~99 dec" 7 "Minor1 version, 0~99 dec" 8 "Minor1 version, 0~99 dec" 9 "Minor1 version, 0~99 dec" 10 "Minor1 version, 0~99 dec" 11 "Minor1 version, 0~99 dec" 12 "Minor1 version, 0~99 dec" 13 "Minor1 version, 0~99 dec" 14 "Minor1 version, 0~99 dec" 15 "Minor1 version, 0~99 dec" 16 "Minor1 version, 0~99 dec" 17 "Minor1 version, 0~99 dec" 18 "Minor1 version, 0~99 dec" 19 "Minor1 version, 0~99 dec" 20 "Minor1 version, 0~99 dec" 21 "Minor1 version, 0~99 dec" 22 "Minor1 version, 0~99 dec" 23 "Minor1 version, 0~99 dec" 24 "Minor1 version, 0~99 dec" 25 "Minor1 version, 0~99 dec" 26 "Minor1 version, 0~99 dec" 27 "Minor1 version, 0~99 dec" 28 "Minor1 version, 0~99 dec" 29 "Minor1 version, 0~99 dec" 30 "Minor1 version, 0~99 dec" 31 "Minor1 version, 0~99 dec" 32 "Minor1 version, 0~99 dec" 33 "Minor1 version, 0~99 dec" 34 "Minor1 version, 0~99 dec" 35 "Minor1 version, 0~99 dec" 36 "Minor1 version, 0~99 dec" 37 "Minor1 version, 0~99 dec" 38 "Minor1 version, 0~99 dec" 39 "Minor1 version, 0~99 dec" 40 "Minor1 version, 0~99 dec" 41 "Minor1 version, 0~99 dec" 42 "Minor1 version, 0~99 dec" 43 "Minor1 version, 0~99 dec" 44 "Minor1 version, 0~99 dec" 45 "Minor1 version, 0~99 dec" 46 "Minor1 version, 0~99 dec" 47 "Minor1 version, 0~99 dec" 48 "Minor1 version, 0~99 dec" 49 "Minor1 version, 0~99 dec" 50 "Minor1 version, 0~99 dec" 51 "Minor1 version, 0~99 dec" 52 "Minor1 version, 0~99 dec" 53 "Minor1 version, 0~99 dec" 54 "Minor1 version, 0~99 dec" 55 "Minor1 version, 0~99 dec" 56 "Minor1 version, 0~99 dec" 57 "Minor1 version, 0~99 dec" 58 "Minor1 version, 0~99 dec" 59 "Minor1 version, 0~99 dec" 60 "Minor1 version, 0~99 dec" 61 "Minor1 version, 0~99 dec" 62 "Minor1 version, 0~99 dec" 63 "Minor1 version, 0~99 dec" 64 "Minor1 version, 0~99 dec" 65 "Minor1 version, 0~99 dec" 66 "Minor1 version, 0~99 dec" 67 "Minor1 version, 0~99 dec" 68 "Minor1 version, 0~99 dec" 69 "Minor1 version, 0~99 dec" 70 "Minor1 version, 0~99 dec" 71 "Minor1 version, 0~99 dec" 72 "Minor1 version, 0~99 dec" 73 "Minor1 version, 0~99 dec" 74 "Minor1 version, 0~99 dec" 75 "Minor1 version, 0~99 dec" 76 "Minor1 version, 0~99 dec" 77 "Minor1 version, 0~99 dec" 78 "Minor1 version, 0~99 dec" 79 "Minor1 version, 0~99 dec" 80 "Minor1 version, 0~99 dec" 81 "Minor1 version, 0~99 dec" 82 "Minor1 version, 0~99 dec" 83 "Minor1 version, 0~99 dec" 84 "Minor1 version, 0~99 dec" 85 "Minor1 version, 0~99 dec" 86 "Minor1 version, 0~99 dec" 87 "Minor1 version, 0~99 dec" 88 "Minor1 version, 0~99 dec" 89 "Minor1 version, 0~99 dec" 90 "Minor1 version, 0~99 dec" 91 "Minor1 version, 0~99 dec" 92 "Minor1 version, 0~99 dec" 93 "Minor1 version, 0~99 dec" 94 "Minor1 version, 0~99 dec" 95 "Minor1 version, 0~99 dec" 96 "Minor1 version, 0~99 dec" 97 "Minor1 version, 0~99 dec" 98 "Minor1 version, 0~99 dec" 99 "Minor1 version, 0~99 dec" 100 "Reserved" 101 "Reserved" 102 "Reserved" 103 "Reserved" 104 "Reserved" 105 "Reserved" 106 "Reserved" 107 "Reserved" 108 "Reserved" 109 "Reserved" 110 "Reserved" 111 "Reserved" 112 "Reserved" 113 "Reserved" 114 "Reserved" 115 "Reserved" 116 "Reserved" 117 "Reserved" 118 "Reserved" 119 "Reserved" 120 "Reserved" 121 "Reserved" 122 "Reserved" 123 "Reserved" 124 "Reserved" 125 "Reserved" 126 "Reserved" 127 "Invalid" ;
VAL_ 2328014849 DATC_FrontPwmIsVolt 255 "Error Indicator" ;
VAL_ 2328014849 DATC_FrontBlwDuty 255 "Error Indicator" ;
VAL_ 2328014849 DATC_FrontBlwDiagStat 0 "Default" 1 "Normal State" 2 "Blower Motor Stall" 3 "Reserved" 4 "Reserved" 5 "Reserved" 6 "Reserved" 7 "Error Indicator" ;
VAL_ 2328014849 DATC_BlwrLvl_Ps 0 "OFF" 1 "0 Level" 2 "1 Level" 3 "2 Level" 4 "3 Level" 5 "4 Level" 6 "5 Level" 7 "6 Level" 8 "7 Level" 9 "8 Level" 10 "Reserved" 11 "Reserved" 12 "Reserved" 13 "Reserved" 14 "Reserved" 15 "Error Indicator" ;
VAL_ 2328014849 DATC_BlwrLvl_Rr 0 "OFF" 1 "0 level" 2 "1 level" 3 "2 level" 4 "3 level" 5 "4 level" 6 "5 level" 7 "6 level" 8 "7 evel" 9 "8 level" 10 "Reserved" 11 "Reserved" 12 "Reserved" 13 "Reserved" 14 "Reserved" 15 "Error Indicator" ;
VAL_ 2328014849 DATC_SwlSta 0 "ON LAMP OFF&OFF LAMP OFF" 1 "ON LAMP OFF&OFF LAMP ON" 2 "ON LAMP ON&OFF LAMP OFF" 3 "ON LAMP ON&OFF LAMP ON" 4 "ACU message error" 7 "Lamp Circuit Failure" ;
VAL_ 2328014849 DATC_FnDstSnsrVal 508 "Sensor Off" 509 "Sensor Initializing" 510 "Sensor Fail" 511 "Error Indicator" ;
VAL_ 2328014850 DATC_FnDstStp 0 "Default" 1 "Good" 2 "Normal" 3 "Poor" 4 "Very Poor" 5 "Reserved" 6 "Reserved" 7 "Error Indicator" ;
VAL_ 2328014850 DATC_OutTempOpt 0 "Not Applied (Default)" 1 "Applied (Send)" 2 "Reserved" 3 "Error Indicator" ;
VAL_ 2328014850 DATC_OutTempDispC 0 "Default" 1 "Blank Display" 254 "Sensor Fail (--Display)" 255 "Invalid" ;
VAL_ 2328014850 DATC_OutTempDispF 0 "Default" 1 "Blank Display" 254 "Sensor Fail (--Display)" 255 "Invalid" ;
VAL_ 2328014850 DATC_EngOffReqWaterTemp 0 "(Default)" 1 "Reserved" 2 "40¡É~100¡É" 3 "40¡É~100¡É" 4 "40¡É~100¡É" 5 "40¡É~100¡É" 6 "40¡É~100¡É" 7 "40¡É~100¡É" 8 "40¡É~100¡É" 9 "40¡É~100¡É" 10 "40¡É~100¡É" 11 "40¡É~100¡É" 12 "40¡É~100¡É" 13 "40¡É~100¡É" 14 "40¡É~100¡É" 15 "40¡É~100¡É" 16 "40¡É~100¡É" 17 "40¡É~100¡É" 18 "40¡É~100¡É" 19 "40¡É~100¡É" 20 "40¡É~100¡É" 21 "40¡É~100¡É" 22 "40¡É~100¡É" 23 "40¡É~100¡É" 24 "40¡É~100¡É" 25 "40¡É~100¡É" 26 "40¡É~100¡É" 27 "40¡É~100¡É" 28 "40¡É~100¡É" 29 "40¡É~100¡É" 30 "40¡É~100¡É" 31 "40¡É~100¡É" 32 "40¡É~100¡É" 33 "40¡É~100¡É" 34 "40¡É~100¡É" 35 "40¡É~100¡É" 36 "40¡É~100¡É" 37 "40¡É~100¡É" 38 "40¡É~100¡É" 39 "40¡É~100¡É" 40 "40¡É~100¡É" 41 "40¡É~100¡É" 42 "40¡É~100¡É" 43 "40¡É~100¡É" 44 "40¡É~100¡É" 45 "40¡É~100¡É" 46 "40¡É~100¡É" 47 "40¡É~100¡É" 48 "40¡É~100¡É" 49 "40¡É~100¡É" 50 "40¡É~100¡É" 51 "40¡É~100¡É" 52 "40¡É~100¡É" 53 "40¡É~100¡É" 54 "40¡É~100¡É" 55 "40¡É~100¡É" 56 "40¡É~100¡É" 57 "40¡É~100¡É" 58 "40¡É~100¡É" 59 "40¡É~100¡É" 60 "40¡É~100¡É" 61 "40¡É~100¡É" 62 "40¡É~100¡É" 63 "Error Indicator" ;
VAL_ 2328014850 DATC_HDPDfg_Sta 0 "Default" 1 "Defog Deactivate for HDP" 2 "Defog Activate for HDP" 3 "Error Indicator" ;
VAL_ 2328014850 DATC_HDPSpptSWVer 0 "Not support" 1 "Spec Ver" 2 "Spec Ver" 3 "Spec Ver" 4 "Spec Ver" 5 "Spec Ver" 6 "Spec Ver" 7 "Spec Ver" 8 "Spec Ver" 9 "Spec Ver" 10 "Spec Ver" 11 "Spec Ver" 12 "Spec Ver" 13 "Spec Ver" 14 "Spec Ver" 15 "Spec Ver" 16 "Spec Ver" 17 "Spec Ver" 18 "Spec Ver" 19 "Spec Ver" 20 "Spec Ver" 21 "Spec Ver" 22 "Spec Ver" 23 "Spec Ver" 24 "Spec Ver" 25 "Spec Ver" 26 "Spec Ver" 27 "Spec Ver" 28 "Spec Ver" 29 "Spec Ver" 30 "Spec Ver" 31 "Error Indicator" ;
VAL_ 2328014850 DATC_HDPHumidity_Sta 0 "Default" 1 "Not Need ADS for HDP" 2 "Need ADS for HDP" 3 "Error Indicator" ;
VAL_ 2328014850 DATC_FnDstStp_Detail 0 "Default" 1 "Good_0" 2 "Good_1" 3 "Good_2" 4 "Good_3" 5 "Good_4" 6 "Normal_1" 7 "Normal_2" 8 "Normal_3" 9 "Normal_4" 10 "Poor_1" 11 "Poor_2" 12 "Poor_3" 13 "Poor_4" 14 "Very Poor_1" 15 "Very Poor_2" 16 "Very Poor_3" 17 "Very Poor_4" 18 "Reserved" 19 "Reserved" 20 "Reserved" 21 "Reserved" 22 "Reserved" 23 "Reserved" 24 "Reserved" 25 "Reserved" 26 "Reserved" 27 "Reserved" 28 "Sensor Off" 29 "Sensor Initializing" 30 "Sensor Fail" 31 "Error Indicator" ;
VAL_ 2172674049 TCS_LmpSta 0 "TCS/ESC Function/Warning Lamp OFF" 1 "TCS/ESC Function/Warning Lamp ON" 2 "TCS/ESC Function/Warning Lamp BLINKING(2Hz)" 3 "Error Indicator" ;
VAL_ 2172674049 TCS_OffLmpSta 0 "TCS/ESC OFF SW Lamp OFF" 1 "TCS/ESC OFF SW Lamp ON" 2 "Not used" 3 "Error Indicator" ;
VAL_ 2172674049 ESC_OffTempSta 0 "Normal Mode" 1 "Sports Mode" 2 "Off Mode" 3 "ESC OFF SW is defective (failed)" ;
VAL_ 2172674049 ESC_OffSwSta 0 "Not Pressed" 1 "Pressed" 2 "Not used" 3 "Not used" ;
VAL_ 2172674049 DBC_WrngLmpSta 0 "DBC Warning lamp OFF" 1 "DBC Warning lamp ON" 2 "Not used" 3 "Error Indicator" ;
VAL_ 2172674049 DBC_FuncLmpSta 0 "DBC Function lamp OFF" 1 "DBC Function lamp ON" 2 "DBC Function lamp BLINKING(2Hz)" 3 "Error Indicator" ;
VAL_ 2172674049 DBC_ClusterDis 0 "DBC Enabled" 1 "DBC Disabled by system fault" 2 "Reserved" 3 "Reserved" ;
VAL_ 2172674049 ESC_SprtLmpSta 0 "ESC Sport Lamp OFF" 1 "ESC Sport Lamp ON" 2 "Reserved" 3 "Reserved" ;
VAL_ 2172674049 ESC_BrkCtrlSta 0 "Brake control is not in activation" 1 "Brake control is in activation" 2 "Not used" 3 "Error Indicator" ;
VAL_ 2172674050 TCS_Sta 0 "Not Applied" 1 "Off" 2 "Ready" 3 "Activated" 4 "Reserved" 5 "Reserved" 6 "Reserved" 7 "Reserved" 8 "Reserved" 9 "Reserved" 10 "Reserved" 11 "Reserved" 12 "Reserved" 13 "Reserved" 14 "Not Coded" 15 "Defective" ;
VAL_ 2172674050 TCS_PreActvSta 0 "-" 1 "Pre TCS Active" 2 "Not used" 3 "Error Indicator" ;
VAL_ 2172674050 DBC_Sta 0 "Not Applied" 1 "Off" 2 "Ready" 3 "Activated" 4 "Reserved" 5 "Reserved" 6 "Reserved" 7 "Reserved" 8 "Reserved" 9 "Reserved" 10 "Reserved" 11 "Reserved" 12 "Reserved" 13 "Reserved" 14 "Not Coded" 15 "Defective" ;
VAL_ 2172674050 TCS_TqFlag 0 "Positive" 1 "Negative" ;
VAL_ 2172674050 MSR_TqFlag 0 "Positive" 1 "Negative" ;
VAL_ 2172674050 HAC_Sta 0 "Not Applied" 1 "Off" 2 "Ready" 3 "Activated" 4 "Reserved" 5 "Reserved" 6 "Reserved" 7 "Reserved" 8 "Reserved" 9 "Reserved" 10 "Reserved" 11 "Reserved" 12 "Reserved" 13 "Reserved" 14 "Not Coded" 15 "Defective" ;
VAL_ 2172674050 BJD_Flag 0 "No Event" 1 "Event" ;
VAL_ 2172674050 TCS_SlwTqFlag 0 "Positive" 1 "Negative" ;
VAL_ 2172674050 TCS_Req 0 "Passive" 1 "TCS/ESC control active" 2 "Not used" 3 "Error Indicator" ;
VAL_ 2172674050 MSR_FuncReq 0 "Passive or TCS function" 1 "MSR control active" 2 "Not used" 3 "Error Indicator" ;
VAL_ 2172674050 TCS_GearShftCharacteristicVal 0 "passive (gear change allowed)" 1 "active (gear change not allowed)" 2 "Not used" 3 "Error Indicator" ;
VAL_ 2172674050 TCS_ManufacturerVal 0 "Using both TQI_TCS and TQI_SLW_TCS" 1 "Using TQI_TCS only (Not using TQI_SLW_TCS)" 2 "Not used" 3 "Error Indicator" ;
VAL_ 2172674050 ESC_Sta 0 "Not Applied" 1 "Off" 2 "Ready" 3 "Activated" 4 "Reserved" 5 "Reserved" 6 "Reserved" 7 "Reserved" 8 "Reserved" 9 "Reserved" 10 "Reserved" 11 "Reserved" 12 "Reserved" 13 "Reserved" 14 "Not Coded" 15 "Defective" ;
VAL_ 2172674051 ESC_CylPrsrVal 4095 "Error" ;
VAL_ 2172674051 ESC_CylPrsrSta 0 "Master cylinder pressure signal is invalid" 1 "Master cylinder pressure signal is valid" 2 "Not used" 3 "Error Indicator" ;
VAL_ 2172674051 ESC_CylPrsrDiagSta 0 "Master cylinder pressure is not available temporarily" 1 "Master cylinder pressure signal is available" 2 "Not used" 3 "Error Indicator" ;
VAL_ 2172674051 ESC_CylPrsrFlagSta 0 "Off" 1 "On" 2 "Not used" 3 "Error Indicator" ;
VAL_ 2172674051 ESC_VsmActvSta 0 "VSM control inactive" 1 "VSM control active" 2 "Not used" 3 "Error Indicator" ;
VAL_ 2172674051 ESC_VsmDfctvSta 0 "VSM is not defective" 1 "VSM is defective" 2 "Not used" 3 "Error Indicator" ;
VAL_ 2172674051 ESC_VsmCtrlModSta 0 "Inactive" 1 "Mode 1 (sensor value overlay mode)" 2 "Mode 2 (output torque overlay mode)" 3 "Mode 3 (Particular control)" ;
VAL_ 2172674051 ESC_StrTqReq 4095 "Error" ;
VAL_ 2172674051 ESC_IMURstStaAck 0 "No reset flag received" 1 "Reset flag has been received" ;
VAL_ 2172674052 AVH_Sta 0 "No apply" 1 "Vehicle is held by the service brake" 2 "Being released" 3 "Error Indicator" ;
VAL_ 2172674052 AVH_CluDis 0 "AVH is off" 1 "AUTO HOLD to be deactivated Press Brake Pedal" 2 "Press Brake Pedal to Release AUTO HOLD" 3 "AUTO HOLD cannot be activated Close Door, Hood, Trunk" 4 "AUTO HOLD cannot be activated Close Door, Hood" 5 "AUTO HOLD cannot be deactivated, Close Door" ;
VAL_ 2172674052 LDM_Sta 0 "ESC ready to DBF/AVH (requested by switch)" 1 "ESC can¡¯t perform DBF/AVH (requested by switch)" 2 "Not used" 3 "Error Indicator" ;
VAL_ 2172674052 AVH_AlrmReq 0 "No alarm" 1 "On AVH Activation, Vehicle is not secured and driver is still inside = comfortable tone" 2 "Not used" 3 "Error Indicator" ;
VAL_ 2172674052 AVH_ActvStaLmpDis 0 "Lamp On" 1 "Lamp Off" 2 "Not used" 3 "Error Indicator" ;
VAL_ 2172674052 AVH_LmpDis 0 "AVH Off (Lamp Status" 1 "AVH failure (Lamp Status" 2 "AVH ACTIVE (Lamp Status" 3 "AVH READY (Lamp Status" 4 "Lamp Status" 5 "Lamp Status" 6 "Lamp Status" ;
VAL_ 2172674052 AWD_CrdnShftTqLimVal 65535 "Error" ;
VAL_ 2172674052 EPB_ActvReq 0 "No request" 1 "Release request" 2 "Close request in comfort mode" 3 "Close request in secure mode" ;
VAL_ 2172674052 AWD_CltchDtyLimVal 255 "Error" ;
VAL_ 2172674052 AWD_TransmsnTqLimModSta 0 "Maximum limitation mode" 1 "Minimum limitation mode" 2 "Not used" 3 "Error Indicator" ;
VAL_ 2172674052 AWD_RrWhlDtyLimReq 0 "No request from ESC" 1 "Request duty limit from ESC" 2 "Not used" 3 "Error Indicator" ;
VAL_ 2172674052 EPB_StaReq 0 "REQ_EPB_ACT signal is invalid" 1 "REQ_EPB_ACT signal is valid" 2 "Not used" 3 "Error Indicator" ;
VAL_ 2172674052 AWD_FastOpnCrdnShftCltchReq 0 "Passive" 1 "Clutch off" 2 "Torque limit" 3 "Error" ;
VAL_ 2172674052 ECD_ActvSta 0 "ECD is not active" 1 "ECD is active(operating)" 2 "Not used" 3 "Error Indicator" ;
VAL_ 491 CF_AVN_Roof_OprLvSet 0 "Default" 1 "Off" 2 "Level1" 3 "Level2" 4 "Level3" 5 "Level4" 6 "Level5" 7 "Invalid" ;
VAL_ 491 CF_AVN_3rdRightDoor_OptLvlSet 0 "Default" 1 "Off" 2 "Level1" 3 "Level2" 4 "Level3" 5 "Level4" 6 "Level5" 7 "Invalid" ;
VAL_ 491 CF_AVN_RearDoor_OptLvlSet 0 "Default" 1 "Off" 2 "Level1" 3 "Level2" 4 "Level3" 5 "Level4" 6 "Level5" 7 "Invalid" ;
VAL_ 491 CF_AVN_RollBlindOnOffSet 0 "Default" 1 "Off" 2 "On" 3 "Invalid" ;
VAL_ 491 CF_AVN_CluThmAutoSet_New 0 "Default" 1 "Disable" 2 "Enable" 3 "Invalid" ;
VAL_ 491 CF_AVN_CluThmSet_New 0 "Default" 1 "Select Theme 1" 2 "Select Theme 2" 3 "Select Theme 3" 4 "Select Theme 4" 5 "Select Theme 5" 6 "Select Theme 6" 7 "Invalid" ;
VAL_ 491 CF_AVN_CluThmDtlSet_New 0 "Default" 1 "Select Theme 1" 2 "Select Theme 2" 3 "Select Theme 3" 4 "Select Theme 4" 5 "Select Theme 5" 6 "Select Theme 6" 7 "Invalid" ;
VAL_ 491 CF_AVN_2ndLeftDoor_OptLvSet 0 "Default" 1 "Off" 2 "Level1" 3 "Level2" 4 "Level3" 5 "Level4" 6 "Level5" 7 "Invalid" ;
VAL_ 491 CF_AVN_2ndRightDoor_OptLvSet 0 "Default" 1 "Off" 2 "Level1" 3 "Level2" 4 "Level3" 5 "Level4" 6 "Level5" 7 "Invalid" ;
VAL_ 491 CF_AVN_3rdLeftDoor_OptLvlSet 0 "Default" 1 "Off" 2 "Level1" 3 "Level2" 4 "Level3" 5 "Level4" 6 "Level5" 7 "Invalid" ;
VAL_ 966 RCM_OptTyp 0 "None" 1 "FR Glass (Normal Sunroof)" 2 "FR Glass+FR Blind (Panorama Roof)" 3 "FR Glass+FR Blind+RR Blind (Panorama with Rear Blind)" 4 "FR Glass+RR Glass (Dual Normal Sunroof)" 5 "FR Blind (Vision Roof)" 6 "FR Glass+RR Blind (Dual Sunroof and Rear Blind)" 7 "Reserved" 8 "Reserved" 9 "Reserved" 10 "Reserved" 11 "Reserved" 12 "Reserved" 13 "Reserved" 14 "Reserved" 15 "Invalid" ;
VAL_ 966 RCM_SwStckDet 0 "Normal" 1 "Error" 2 "Not Used" 3 "Error Indicator" ;
VAL_ 966 RCM_SwSta 0 "None" 1 "Manual Open" 2 "Auto Open" 3 "Manual Close" 4 "Auto Close" 5 "Manual Tilt Up" 6 "Auto Tilt Up" 7 "Error Indicator" ;
VAL_ 967 RCM_GlsHallSnsrPlsCnt 16383 "Error Indicator" ;
VAL_ 967 RCM_SunroofOpnSta 0 "Close" 1 "Open" 2 "Not Used" 3 "Error Indicator" ;
VAL_ 967 RCM_GlsOpSta 0 "No Action" 1 "Opening" 2 "Closing" 3 "Error Indicator" ;
VAL_ 967 RCM_GlsInitSta 0 "Not achieved" 1 "Initialized" 2 "Not Used" 3 "Error Indicator" ;
VAL_ 967 RCM_GlsAntPchSta 0 "Normal" 1 "Anti-Pinch Status" 2 "Not Used" 3 "Error Indicator" ;
VAL_ 967 RCM_GlsMtrHiTempSta 0 "Normal" 1 "High Temperature" 2 "Not Used" 3 "Error Indicator" ;
VAL_ 967 RCM_GlsMtRunTtlTime 255 "Error Indicator" ;
VAL_ 967 RCM_GlsPosSta 0 "Glass Fully Close" 1 "Glass Vent Area" 2 "Glass Tilt Up" 3 "Glass Partially Open" 4 "Glass 1st Step Open (OPT)" 5 "Glass More Than 1st Step Open Area (OPT)" 6 "Glass Fully Open" 7 "Glass Undefined" 8 "Reserved" 9 "Reserved" 10 "Reserved" 11 "Reserved" 12 "Reserved" 13 "Reserved" 14 "Reserved" 15 "" ;
VAL_ 967 RCM_GlsFltVal 0 "No Error" 1 "FET Error" 2 "Hall Sensor Error" 3 "MCU Error" 4 "EEPROM Error" 5 "Voltage Error" 6 "Switch Error" 7 "Thermal Protection Active" 8 "Complex Error" 9 "Reserved" 10 "Reserved" 11 "Reserved" 12 "Reserved" 13 "Reserved" 14 "Reserved" 15 "Invalid" ;
VAL_ 967 RCM_GlsFltSta 0 "Normal" 1 "Fault" 2 "Not Used" 3 "Error Indicator" ;
VAL_ 968 RCM_BldHallSnsrPlsCnt 16383 "Error Indicator" ;
VAL_ 968 RCM_BldOpSta 0 "No Action" 1 "Opening" 2 "Closing" 3 "Error Indicator" ;
VAL_ 968 RCM_BldInitSta 0 "Not achieved" 1 "Initialized" 2 "Not Used" 3 "Error Indicator" ;
VAL_ 968 RCM_BldAntPchSta 0 "Normal" 1 "Anti_Pinch Status" 2 "Not Used" 3 "Error Indicator" ;
VAL_ 968 RCM_BldMtrHiTempSta 0 "Normal" 1 "High Temperature" 2 "Not Used" 3 "Error Indicator" ;
VAL_ 968 RCM_BldMtRunTtlTime 255 "Error Indicator" ;
VAL_ 968 RCM_BldPosSta 0 "Blind Fully Close" 1 "Blind Less Than Half Open" 2 "Blind Half Open (OPT)" 3 "Blind More Than Half Open (OPT)" 4 "Blind Fully Open" 5 "Blind Undefined" 6 "Reserved" 7 "Invalid" ;
VAL_ 968 RCM_BldFltVal 0 "No Error" 1 "FET Error" 2 "Hall Sensor Error" 3 "MCU Error" 4 "EEPROM Error" 5 "Voltage Error" 6 "Switch Error" 7 "Thermal Protection Active" 8 "Complex Error" 9 "Reserved" 10 "Reserved" 11 "Reserved" 12 "Reserved" 13 "Reserved" 14 "Reserved" 15 "Invalid" ;
VAL_ 968 RCM_BldFltSta 0 "Normal" 1 "Fault" 2 "Not Used" 3 "Error Indicator" ;
VAL_ 2332213249 VCU_Required_ADASMapMsg 0 "0x0x0~0xFFFE:Required Map based ADAS Messages" 65534 "0x0x0~0xFFFE:Required Map based ADAS Messages" 65535 "Invalid" ;
VAL_ 2332213249 VCU_SwVer 0 "0x0x0~0xFE:VCU SW Version" 254 "0x0x0~0xFE:VCU SW Version" 255 "Invalid" ;
VAL_ 2332213249 VCU_PwrAutoOffInfo 0 "Normal" 1 "AutoPowerOffActived" 2 "TimerActive" 3 "ErrorIndicator" ;
VAL_ 2332213249 VCU_PwrAutoOffTimerSta 0 "Default" 1 "Timer1" 2 "Timer2" 3 "Timer3" 4 "Timer4" 5 "Disable" 6 "Invalid" 7 "ErrorIndicator" ;
VAL_ 2332213250 VCU_TireSizeWrnMsgSta 0 "Not Display" 1 "Popup Req" 2 "Reserved" 3 "Reserved" ;
VAL_ 2332213250 VCU_BstOpSta 0 "Off" 1 "Ready" 2 "Activated" 3 "Wait" 4 "Reserved" 5 "Reserved" 6 "Reserved" 7 "Reserved" ;
VAL_ 2332213250 VCU_BstWarnMsg 0 "None(Default)" 1 "Failed by vehicle condition" 2 "Reserved" 3 "Reserved" ;
VAL_ 2332213250 VCU_BstAvailSta 0 "Not available" 1 "Available" 2 "Reserved" 3 "Reserved" ;
VAL_ 2332213250 VCU_BstAplySta 0 "Not Applied" 1 "Applied" 2 "Reserved" 3 "Reserved" ;
VAL_ 2332213250 VCU_PwrAutoOffTimerReset 0 "Normal" 1 "AutoPowerTimerResetActived" 2 "NotUsed" 3 "ErrorIndicator" ;
VAL_ 1308 NMCommandCode_RLPSU 1 "Alive" 2 "Ring" 4 "Limphome" ;
VAL_ 1308 NMSleepFlag_RLPSU 0 "Alive" 1 "SleepInd" 3 "SleepAck" ;
VAL_ 1336 NMCommandCode_DPSU 1 "Alive" 2 "Ring" 4 "Limphome" ;
VAL_ 1336 NMSleepFlag_DPSU 0 "Alive" 1 "SleepInd" 3 "SleepAck" ;
VAL_ 1329 NMCommandCode_APSU 1 "Alive" 2 "Ring" 4 "Limphome" ;
VAL_ 1329 NMSleepFlag_APSU 0 "Alive" 1 "SleepInd" 3 "SleepAck" ;
VAL_ 1345 NMCommandCode_PSB 1 "Alive" 2 "Ring" 4 "Limphome" ;
VAL_ 1345 NMSleepFlag_PSB 0 "Alive" 1 "SleepInd" 3 "SleepAck" ;
VAL_ 1323 NMCommandCode_SHVU_RR 1 "Alive" 2 "Ring" 4 "Limphome" ;
VAL_ 1323 NMSleepFlag_SHVU_RR 0 "Alive" 1 "SleepInd" 3 "SleepAck" ;
VAL_ 1313 NMCommandCode_FCS 1 "Alive" 2 "Ring" 4 "Limphome" ;
VAL_ 1313 NMSleepFlag_FCS 0 "Alive" 1 "SleepInd" 3 "SleepAck" ;
VAL_ 1297 NMCommandCode_EMCU 1 "Alive" 2 "Ring" 4 "Limphome" ;
VAL_ 1297 NMSleepFlag_EMCU 0 "Alive" 1 "SleepInd" 3 "SleepAck" ;
VAL_ 1307 NMCommandCode_SLB 1 "Alive" 2 "Ring" 4 "Limphome" ;
VAL_ 1307 NMSleepFlag_SLB 0 "Alive" 1 "SleepInd" 3 "SleepAck" ;
VAL_ 1341 NMCommandCode_RCM 1 "Alive" 2 "Ring" 4 "Limphome" ;
VAL_ 1341 NMSleepFlag_RCM 0 "Alive" 1 "SleepInd" 3 "SleepAck" ;
VAL_ 1392 NMCommandCode_CGW_CCU 1 "Alive" 2 "Ring" 4 "Limphome" ;
VAL_ 1392 NMSleepFlag_CGW_CCU 0 "Alive" 1 "SleepInd" 3 "SleepAck" ;
VAL_ 1360 NMCommandCode_ATS 1 "Alive" 2 "Ring" 4 "Limphome" ;
VAL_ 1360 NMSleepFlag_ATS 0 "Alive" 1 "SleepInd" 3 "SleepAck" ;
VAL_ 1332 NMCommandCode_RLHV 1 "Alive" 2 "Ring" 4 "Limphome" ;
VAL_ 1332 NMSleepFlag_RLHV 0 "Alive" 1 "SleepInd" 3 "SleepAck" ;
VAL_ 1325 NMCommandCode_PFSU 1 "Alive" 2 "Ring" 4 "Limphome" ;
VAL_ 1325 NMSleepFlag_PFSU 0 "Alive" 1 "SleepInd" 3 "SleepAck" ;
VAL_ 1342 NMCommandCode_SGU 1 "Alive" 2 "Ring" 4 "Limphome" ;
VAL_ 1342 NMSleepFlag_SGU 0 "Alive" 1 "SleepInd" 3 "SleepAck" ;
VAL_ 1348 NMCommandCode_ALBCU 1 "Alive" 2 "Ring" 4 "Limphome" ;
VAL_ 1348 NMSleepFlag_ALBCU 0 "Alive" 1 "SleepInd" 3 "SleepAck" ;
VAL_ 1369 NMCommandCode_DSAU 1 "Alive" 2 "Ring" 4 "Limphome" ;
VAL_ 1369 NMSleepFlag_DSAU 0 "Alive" 1 "SleepInd" 3 "SleepAck" ;
VAL_ 1288 NMCommandCode_SWRC 1 "Alive" 2 "Ring" 4 "Limphome" ;
VAL_ 1288 NMSleepFlag_SWRC 0 "Alive" 1 "SleepInd" 3 "SleepAck" ;
VAL_ 1322 NMCommandCode_SHVU_FR 1 "Alive" 2 "Ring" 4 "Limphome" ;
VAL_ 1322 NMSleepFlag_SHVU_FR 0 "Alive" 1 "SleepInd" 3 "SleepAck" ;
VAL_ 1350 NMCommandCode_RCS 1 "Alive" 2 "Ring" 4 "Limphome" ;
VAL_ 1350 NMSleepFlag_RCS 0 "Alive" 1 "SleepInd" 3 "SleepAck" ;
VAL_ 1309 NMCommandCode_RRPSU 1 "Alive" 2 "Ring" 4 "Limphome" ;
VAL_ 1309 NMSleepFlag_RRPSU 0 "Alive" 1 "SleepInd" 3 "SleepAck" ;
VAL_ 1352 NMCommandCode_BLTN_CAM 1 "Alive" 2 "Ring" 4 "Limphome" ;
VAL_ 1352 NMSleepFlag_BLTN_CAM 0 "Alive" 1 "SleepInd" 3 "SleepAck" ;
VAL_ 1287 NMCommandCode_SCM 1 "Alive" 2 "Ring" 4 "Limphome" ;
VAL_ 1287 NMSleepFlag_SCM 0 "Alive" 1 "SleepInd" 3 "SleepAck" ;
VAL_ 1344 NMCommandCode_DLBCU 1 "Alive" 2 "Ring" 4 "Limphome" ;
VAL_ 1344 NMSleepFlag_DLBCU 0 "Alive" 1 "SleepInd" 3 "SleepAck" ;
VAL_ 1364 NMCommandCode_OHCL 1 "Alive" 2 "Ring" 4 "Limphome" ;
VAL_ 1364 NMSleepFlag_OHCL 0 "Alive" 1 "SleepInd" 3 "SleepAck" ;
VAL_ 1311 NMCommandCode_RWPC 1 "Alive" 2 "Ring" 4 "Limphome" ;
VAL_ 1311 NMSleepFlag_RWPC 0 "Alive" 1 "SleepInd" 3 "SleepAck" ;
VAL_ 1333 NMCommandCode_RRHV 1 "Alive" 2 "Ring" 4 "Limphome" ;
VAL_ 1333 NMSleepFlag_RRHV 0 "Alive" 1 "SleepInd" 3 "SleepAck" ;
VAL_ 1310 NMCommandCode_WPC 1 "Alive" 2 "Ring" 4 "Limphome" ;
VAL_ 1310 NMSleepFlag_WPC 0 "Alive" 1 "SleepInd" 3 "SleepAck" ;
VAL_ 1354 NMCommandCode_HOD 1 "Alive" 2 "Ring" 4 "Limphome" ;
VAL_ 1354 NMSleepFlag_HOD 0 "Alive" 1 "SleepInd" 3 "SleepAck" ;
VAL_ 1363 NMCommandCode_ASAU 1 "Alive" 2 "Ring" 4 "Limphome" ;
VAL_ 1363 NMSleepFlag_ASAU 0 "Alive" 1 "SleepInd" 3 "SleepAck" ;
